VERSION ""

NS_ :

BS_:

BU_: IDM FR Tester

BO_ 1136 ADAS_AD1: 16 IDM
 SG_ Sync_SyncTime : 39|32@0+ (1,0) [0|4294967295] "" Vector__XXX
 SG_ Sync_OVS : 25|2@0+ (1,0) [0|3] "" Vector__XXX
 SG_ Sync_SGW : 26|1@0+ (1,0) [0|1] "" Vector__XXX
 SG_ Sync_Resd : 31|5@0+ (1,0) [0|31] "" Vector__XXX
 SG_ Sync_Counter : 19|4@0+ (1,0) [0|15] "" Vector__XXX
 SG_ Sync_TimeDomain : 23|4@0+ (1,0) [0|15] "" Vector__XXX
 SG_ Sync_CRC : 15|8@0+ (1,0) [0|255] "" Vector__XXX
 SG_ Sync_Type : 7|8@0+ (1,0) [0|255] "" Vector__XXX

BO_ 302 IBC_FD1: 64 IDM
 SG_ RollingCounter_IBC_FD1_1 : 59|4@0+ (1,0) [0|15] "NoUnit" Vector__XXX
 SG_ PushrodStauts : 51|2@0+ (1,0) [0|3] "NoUnit" Vector__XXX
 SG_ InpRodStk : 47|10@0+ (0.05,-5) [-5|46.15] "mm" Vector__XXX
 SG_ InpRodStkSts : 32|1@0+ (1,0) [0|1] "NoUnit" Vector__XXX
 SG_ Checksum_IBC_FD1_1 : 7|8@0+ (1,0) [0|255] "NoUnit" Vector__XXX

BO_ 311 ESP_FD2: 64 IDM
 SG_ RollingCounter_ABS3 : 379|4@0+ (1,0) [0|15] "NoUnit" Vector__XXX
 SG_ ABSActv : 347|1@0+ (1,0) [0|1] "NoUnit" Vector__XXX
 SG_ VehSpd : 332|13@0+ (0.05625,0) [0|299.98125] "kph" Vector__XXX
 SG_ ABSFailSts : 335|1@0+ (1,0) [0|1] "NoUnit" Vector__XXX
 SG_ Checksum_ABS3 : 327|8@0+ (1,0) [0|255] "NoUnit" Vector__XXX
 SG_ RollingCounter_ESP1 : 187|4@0+ (1,0) [0|15] "NoUnit" Vector__XXX
 SG_ VDCActv : 148|1@0+ (1,0) [0|1] "NoUnit" Vector__XXX
 SG_ MSRActv : 149|1@0+ (1,0) [0|1] "NoUnit" Vector__XXX
 SG_ PTCActv : 150|1@0+ (1,0) [0|1] "NoUnit" Vector__XXX
 SG_ BTCActv : 151|1@0+ (1,0) [0|1] "NoUnit" Vector__XXX
 SG_ ESPFuncOffSts : 140|1@0+ (1,0) [0|1] "NoUnit" Vector__XXX
 SG_ ESPFailSts : 143|1@0+ (1,0) [0|1] "NoUnit" Vector__XXX
 SG_ Checksum_ESP1 : 135|8@0+ (1,0) [0|255] "NoUnit" Vector__XXX
 SG_ RollingCounter_ESP2 : 123|4@0+ (1,0) [0|15] "NoUnit" Vector__XXX
 SG_ ESP_DiagActv : 73|1@0+ (1,0) [0|1] "NoUnit" Vector__XXX
 SG_ NoBrkForce : 76|1@0+ (1,0) [0|1] "NoUnit" Vector__XXX
 SG_ VehStandstill : 78|2@0+ (1,0) [0|3] "NoUnit" Vector__XXX
 SG_ Checksum_ESP2 : 71|8@0+ (1,0) [0|255] "NoUnit" Vector__XXX

BO_ 315 ESP_FD3: 64 IDM
 SG_ RollingCounter_ABS2 : 379|4@0+ (1,0) [0|15] "NoUnit" Vector__XXX
 SG_ RRWheelSpd : 348|13@0+ (0.05625,0) [0|299.98125] "kph" Vector__XXX
 SG_ RRWheelSpdVld : 349|1@0+ (1,0) [0|1] "NoUnit" Vector__XXX
 SG_ RRWheelDriveDirection : 351|2@0+ (1,0) [0|3] "NoUnit" Vector__XXX
 SG_ RLWheelSpd : 332|13@0+ (0.05625,0) [0|299.98125] "kph" Vector__XXX
 SG_ RLWheelSpdVld : 333|1@0+ (1,0) [0|1] "NoUnit" Vector__XXX
 SG_ RLWheelDriveDirection : 335|2@0+ (1,0) [0|3] "NoUnit" Vector__XXX
 SG_ Checksum_ABS2 : 327|8@0+ (1,0) [0|255] "NoUnit" Vector__XXX
 SG_ RollingCounter_ABS1 : 59|4@0+ (1,0) [0|15] "NoUnit" Vector__XXX
 SG_ FRWheelSpd : 28|13@0+ (0.05625,0) [0|299.98125] "kph" Vector__XXX
 SG_ FRWheelSpdVld : 29|1@0+ (1,0) [0|1] "NoUnit" Vector__XXX
 SG_ FRWheelDriveDirection : 31|2@0+ (1,0) [0|3] "NoUnit" Vector__XXX
 SG_ FLWheelSpd : 12|13@0+ (0.05625,0) [0|299.98125] "kph" Vector__XXX
 SG_ FLWheelSpdVld : 13|1@0+ (1,0) [0|1] "NoUnit" Vector__XXX
 SG_ FLWheelDriveDirection : 15|2@0+ (1,0) [0|3] "NoUnit" Vector__XXX
 SG_ Checksum_ABS1 : 7|8@0+ (1,0) [0|255] "NoUnit" Vector__XXX

BO_ 411 F_PBOX1: 8 IDM
 SG_ HoodSts_F_PBox : 21|1@0+ (1,0) [0|1] "NoUnit" Vector__XXX

BO_ 412 R_PBOX1: 16 IDM
 SG_ RTurnLmpSts_R_PBox : 30|1@0+ (1,0) [0|1] "NoUnit" Vector__XXX
 SG_ LTurnLmpSts_R_PBox : 31|1@0+ (1,0) [0|1] "NoUnit" Vector__XXX

BO_ 545 DCT5: 8 IDM
 SG_ TGS_LEVER : 51|4@0+ (1,0) [0|15] "NoUnit" Vector__XXX

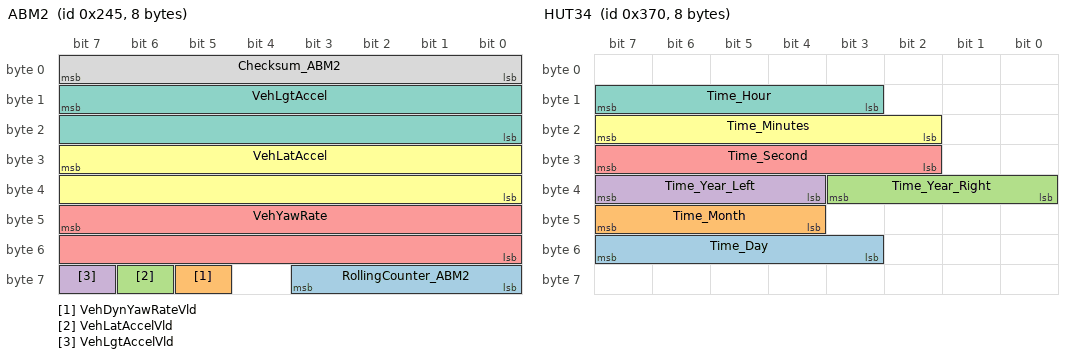
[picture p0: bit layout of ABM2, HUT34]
BO_ 581 ABM2: 8 IDM
 SG_ RollingCounter_ABM2 : 59|4@0+ (1,0) [0|15] "NoUnit" Vector__XXX
 SG_ VehDynYawRateVld : 61|1@0+ (1,0) [0|1] "NoUnit" Vector__XXX
 SG_ VehLatAccelVld : 62|1@0+ (1,0) [0|1] "NoUnit" Vector__XXX
 SG_ VehLgtAccelVld : 63|1@0+ (1,0) [0|1] "NoUnit" Vector__XXX
 SG_ VehYawRate : 47|16@0+ (0.00024,-2.093) [-2.093|2.093] "radPerSec" Vector__XXX
 SG_ VehLatAccel : 31|16@0+ (0.00098,-21.592) [-21.592|21.592] "MtrPerSecSq" Vector__XXX
 SG_ VehLgtAccel : 15|16@0+ (0.00098,-21.592) [-21.592|21.592] "MtrPerSecSq" Vector__XXX
 SG_ Checksum_ABM2 : 7|8@0+ (1,0) [0|255] "NoUnit" Vector__XXX

BO_ 639 IP2: 16 IDM
 SG_ IP_VehTotDistance : 15|24@0+ (0.1,0) [0|999999.9] "km" Vector__XXX

BO_ 671 BCM8: 8 IDM
 SG_ WiprReq_F_PBox : 51|3@0+ (1,0) [0|7] "NoUnit" Vector__XXX

BO_ 719 IFC_FD3: 64 IDM
 SG_ TSRSpdLim : 87|6@0+ (1,0) [0|63] "NoUnit" Vector__XXX
 SG_ TSRConSpdLim : 15|6@0+ (1,0) [0|63] "NoUnit" Vector__XXX

BO_ 849 ABM1: 16 IDM
 SG_ RollingCounter_ABM1 : 59|4@0+ (1,0) [0|15] "NoUnit" Vector__XXX
 SG_ DrvSBR : 11|1@0+ (1,0) [0|1] "NoUnit" Vector__XXX
 SG_ Checksum_ABM1 : 7|8@0+ (1,0) [0|255] "NoUnit" Vector__XXX

BO_ 880 HUT34: 8 IDM
 SG_ Time_Day : 55|5@0+ (1,0) [0|31] "NoUnit" Vector__XXX
 SG_ Time_Month : 47|4@0+ (1,0) [0|15] "NoUnit" Vector__XXX
 SG_ Time_Year_Right : 35|4@0+ (1,0) [0|15] "NoUnit" Vector__XXX
 SG_ Time_Year_Left : 39|4@0+ (1,0) [0|15] "NoUnit" Vector__XXX
 SG_ Time_Second : 31|6@0+ (1,0) [0|63] "NoUnit" Vector__XXX
 SG_ Time_Minutes : 23|6@0+ (1,0) [0|63] "NoUnit" Vector__XXX
 SG_ Time_Hour : 15|5@0+ (1,0) [0|31] "NoUnit" Vector__XXX

BO_ 901 AC2: 8 IDM
 SG_ ACAmbTemp : 23|8@0+ (0.5,-40) [-40|86.5] "DegC" Vector__XXX

BO_ 1001 T_BOX_FD3: 16 IDM
 SG_ T_BOX_SysErrSts : 7|5@0+ (1,0) [0|31] "NoUnit" Vector__XXX

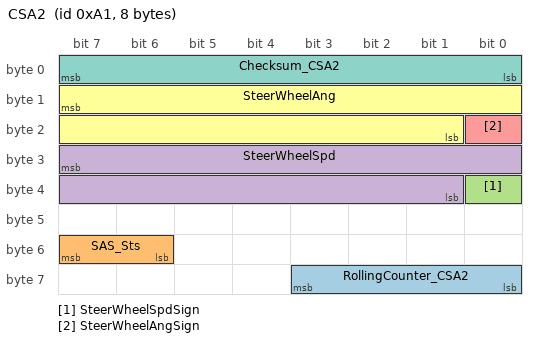
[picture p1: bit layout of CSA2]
BO_ 161 CSA2: 8 IDM
 SG_ RollingCounter_CSA2 : 59|4@0+ (1,0) [0|15] "NoUnit" Vector__XXX
 SG_ SAS_Sts : 55|2@0+ (1,0) [0|3] "NoUnit" Vector__XXX
 SG_ SteerWheelSpdSign : 32|1@0+ (1,0) [0|1] "NoUnit" Vector__XXX
 SG_ SteerWheelSpd : 31|15@0+ (0.1,0) [0|1016] "DegPerSec" Vector__XXX
 SG_ SteerWheelAngSign : 16|1@0+ (1,0) [0|1] "NoUnit" Vector__XXX
 SG_ SteerWheelAng : 15|15@0+ (0.1,0) [0|780] "Deg" Vector__XXX
 SG_ Checksum_CSA2 : 7|8@0+ (1,0) [0|255] "NoUnit" Vector__XXX

BO_ 1073 MRRAD2: 64 FR
 SG_ RollingCounter16 : 507|4@0+ (1,0) [0|15] ""  IDM
 SG_ MRR_ObjMeasured_3 : 497|2@0+ (1,0) [0|3] ""  IDM
 SG_ MRR_ObjMeasured_4 : 499|2@0+ (1,0) [0|3] ""  IDM
 SG_ MRR_ObjHeading_4 : 495|12@0+ (0.002,-3.14) [-3.14|3.14] "rad"  IDM
 SG_ MRR_ObjAge_4 : 487|8@0+ (1,0) [0|255] ""  IDM
 SG_ MRR_ObjRCS_4 : 465|10@0+ (0.125,-50) [-50|70] "dBm2"  IDM
 SG_ BlockCounter2 : 469|4@0+ (1,0) [0|15] ""  IDM
 SG_ VFC_ObjHeight_4 : 463|10@0+ (0.01,0) [0|6] "m"  IDM
 SG_ Checksum16 : 455|8@0+ (1,0) [0|255] ""  IDM
 SG_ RollingCounter15 : 443|4@0+ (1,0) [0|15] ""  IDM
 SG_ VFC_ObjMotionDirection_4 : 432|3@0+ (1,0) [0|7] ""  IDM
 SG_ VFC_ObjLength_4 : 426|10@0+ (0.05,0) [0|20] "m"  IDM
 SG_ VFC_ObjWidth_4 : 420|10@0+ (0.01,0) [0|5] "m"  IDM
 SG_ MRR_ObjMotionType_4 : 423|3@0+ (1,0) [0|7] ""  IDM
 SG_ MRR_ObjRAccelYStd_4 : 413|6@0+ (0.0625,0) [0|3.9375] "mps2"  IDM
 SG_ MRR_ObjRAccelXStd_4 : 403|6@0+ (0.0625,0) [0|3.9375] "mps2"  IDM
 SG_ MRR_ObjRelVelYStd_4 : 393|6@0+ (0.0625,0) [0|3.9375] "mps"  IDM
 SG_ MRR_ObjRelVelXStd_4 : 399|6@0+ (0.0625,0) [0|3.9375] "mps"  IDM
 SG_ Checksum15 : 391|8@0+ (1,0) [0|255] ""  IDM
 SG_ RollingCounter14 : 379|4@0+ (1,0) [0|15] ""  IDM
 SG_ MRR_ObjType_4 : 383|4@0+ (1,0) [0|15] ""  IDM
 SG_ MRR_ObjDistYStd_4 : 373|6@0+ (0.1,0) [0|6] "m"  IDM
 SG_ MRR_ObjDistXStd_4 : 363|6@0+ (0.1,0) [0|6] "m"  IDM
 SG_ MRR_ObjRelAccelY_4 : 357|10@0+ (0.03125,-16) [-16|15.96875] "mps2"  IDM
 SG_ MRR_ObjRelVelY_4 : 338|13@0+ (0.0312,-128) [-128|126.9976] "mps"  IDM
 SG_ MRR_ObjRelVelX_4 : 335|13@0+ (0.0312,-128) [-128|126.9976] "mps"  IDM
 SG_ Checksum14 : 327|8@0+ (1,0) [0|255] ""  IDM
 SG_ RollingCounter13 : 315|4@0+ (1,0) [0|15] ""  IDM
 SG_ MRR_ObjRelAccelX_4 : 310|10@0+ (0.03125,-16) [-16|15.96875] "mps2"  IDM
 SG_ MRR_ObjDistY_4 : 289|11@0+ (0.125,-128) [-128|127.875] "m"  IDM
 SG_ MRR_ObjDistX_4 : 285|12@0+ (0.0625,0) [0|254.9375] "m"  IDM
 SG_ MRR_ObjObstacleProb_4 : 274|5@0+ (0.03125,0) [0|0.96875] ""  IDM
 SG_ MRR_ObjExistProb_4 : 279|5@0+ (0.03125,0) [0|0.96875] ""  IDM
 SG_ MRR_ObjID_4 : 271|8@0+ (1,0) [0|255] ""  IDM
 SG_ Checksum13 : 263|8@0+ (1,0) [0|255] ""  IDM
 SG_ RollingCounter12 : 251|4@0+ (1,0) [0|15] ""  IDM
 SG_ MRR_ObjRefPoint_3 : 243|3@0+ (1,0) [0|7] "NoUnit"  IDM
 SG_ MRR_ObjRefPoint_4 : 247|3@0+ (1,0) [0|7] "NoUnit"  IDM
 SG_ MRR_ObjAge_3 : 239|8@0+ (1,0) [0|255] ""  IDM
 SG_ MRR_ObjRCS_3 : 217|10@0+ (0.125,-50) [-50|70] "dBm2"  IDM
 SG_ MRR_ObjHeading_3 : 213|12@0+ (0.002,-3.14) [-3.14|3.14] "rad"  IDM
 SG_ VFC_ObjHeight_3 : 207|10@0+ (0.01,0) [0|6] "m"  IDM
 SG_ Checksum12 : 199|8@0+ (1,0) [0|255] ""  IDM
 SG_ RollingCounter11 : 187|4@0+ (1,0) [0|15] ""  IDM
 SG_ VFC_ObjMotionDirection_3 : 176|3@0+ (1,0) [0|7] ""  IDM
 SG_ VFC_ObjLength_3 : 170|10@0+ (0.05,0) [0|20] "m"  IDM
 SG_ VFC_ObjWidth_3 : 164|10@0+ (0.01,0) [0|5] "m"  IDM
 SG_ MRR_ObjMotionType_3 : 167|3@0+ (1,0) [0|7] ""  IDM
 SG_ MRR_ObjRAccelYStd_3 : 157|6@0+ (0.0625,0) [0|3.9375] "mps2"  IDM
 SG_ MRR_ObjRAccelXStd_3 : 147|6@0+ (0.0625,0) [0|3.9375] "mps2"  IDM
 SG_ MRR_ObjRelVelYStd_3 : 137|6@0+ (0.0625,0) [0|3.9375] "mps"  IDM
 SG_ MRR_ObjRelVelXStd_3 : 143|6@0+ (0.0625,0) [0|3.9375] "mps"  IDM
 SG_ Checksum11 : 135|8@0+ (1,0) [0|255] ""  IDM
 SG_ RollingCounter10 : 123|4@0+ (1,0) [0|15] ""  IDM
 SG_ MRR_ObjType_3 : 127|4@0+ (1,0) [0|15] ""  IDM
 SG_ MRR_ObjDistYStd_3 : 117|6@0+ (0.1,0) [0|6] "m"  IDM
 SG_ MRR_ObjDistXStd_3 : 107|6@0+ (0.1,0) [0|6] "m"  IDM
 SG_ MRR_ObjRelAccelY_3 : 101|10@0+ (0.03125,-16) [-16|15.96875] "mps2"  IDM
 SG_ MRR_ObjRelVelY_3 : 82|13@0+ (0.0312,-128) [-128|126.9976] "mps"  IDM
 SG_ MRR_ObjRelVelX_3 : 79|13@0+ (0.0312,-128) [-128|126.9976] "mps"  IDM
 SG_ Checksum10 : 71|8@0+ (1,0) [0|255] ""  IDM
 SG_ RollingCounter9 : 59|4@0+ (1,0) [0|15] ""  IDM
 SG_ MRR_ObjRelAccelX_3 : 54|10@0+ (0.03125,-16) [-16|15.96875] "mps2"  IDM
 SG_ MRR_ObjDistY_3 : 33|11@0+ (0.125,-128) [-128|127.875] "m"  IDM
 SG_ MRR_ObjDistX_3 : 29|12@0+ (0.0625,0) [0|254.9375] "m"  IDM
 SG_ MRR_ObjObstacleProb_3 : 18|5@0+ (0.03125,0) [0|0.96875] ""  IDM
 SG_ MRR_ObjExistProb_3 : 23|5@0+ (0.03125,0) [0|0.96875] ""  IDM
 SG_ MRR_ObjID_3 : 15|8@0+ (1,0) [0|255] ""  IDM
 SG_ Checksum9 : 7|8@0+ (1,0) [0|255] ""  IDM

BO_ 1074 MRRAD3: 64 FR
 SG_ RollingCounter24 : 507|4@0+ (1,0) [0|15] ""  IDM
 SG_ MRR_ObjMeasured_5 : 497|2@0+ (1,0) [0|3] ""  IDM
 SG_ MRR_ObjMeasured_6 : 499|2@0+ (1,0) [0|3] ""  IDM
 SG_ MRR_ObjHeading_6 : 495|12@0+ (0.002,-3.14) [-3.14|3.14] "rad"  IDM
 SG_ MRR_ObjAge_6 : 487|8@0+ (1,0) [0|255] ""  IDM
 SG_ MRR_ObjRCS_6 : 465|10@0+ (0.125,-50) [-50|70] "dBm2"  IDM
 SG_ BlockCounter3 : 469|4@0+ (1,0) [0|15] ""  IDM
 SG_ VFC_ObjHeight_6 : 463|10@0+ (0.01,0) [0|6] "m"  IDM
 SG_ Checksum24 : 455|8@0+ (1,0) [0|255] ""  IDM
 SG_ RollingCounter23 : 443|4@0+ (1,0) [0|15] ""  IDM
 SG_ VFC_ObjMotionDirection_6 : 432|3@0+ (1,0) [0|7] ""  IDM
 SG_ VFC_ObjLength_6 : 426|10@0+ (0.05,0) [0|20] "m"  IDM
 SG_ VFC_ObjWidth_6 : 420|10@0+ (0.01,0) [0|5] "m"  IDM
 SG_ MRR_ObjMotionType_6 : 423|3@0+ (1,0) [0|7] ""  IDM
 SG_ MRR_ObjRAccelYStd_6 : 413|6@0+ (0.0625,0) [0|3.9375] "mps2"  IDM
 SG_ MRR_ObjRAccelXStd_6 : 403|6@0+ (0.0625,0) [0|3.9375] "mps2"  IDM
 SG_ MRR_ObjRelVelYStd_6 : 393|6@0+ (0.0625,0) [0|3.9375] "mps"  IDM
 SG_ MRR_ObjRelVelXStd_6 : 399|6@0+ (0.0625,0) [0|3.9375] "mps"  IDM
 SG_ Checksum23 : 391|8@0+ (1,0) [0|255] ""  IDM
 SG_ RollingCounter22 : 379|4@0+ (1,0) [0|15] ""  IDM
 SG_ MRR_ObjType_6 : 383|4@0+ (1,0) [0|15] ""  IDM
 SG_ MRR_ObjDistYStd_6 : 373|6@0+ (0.1,0) [0|6] "m"  IDM
 SG_ MRR_ObjDistXStd_6 : 363|6@0+ (0.1,0) [0|6] "m"  IDM
 SG_ MRR_ObjRelAccelY_6 : 357|10@0+ (0.03125,-16) [-16|15.96875] "mps2"  IDM
 SG_ MRR_ObjRelVelY_6 : 338|13@0+ (0.0312,-128) [-128|126.9976] "mps"  IDM
 SG_ MRR_ObjRelVelX_6 : 335|13@0+ (0.0312,-128) [-128|126.9976] "mps"  IDM
 SG_ Checksum22 : 327|8@0+ (1,0) [0|255] ""  IDM
 SG_ RollingCounter21 : 315|4@0+ (1,0) [0|15] ""  IDM
 SG_ MRR_ObjRelAccelX_6 : 310|10@0+ (0.03125,-16) [-16|15.96875] "mps2"  IDM
 SG_ MRR_ObjDistY_6 : 289|11@0+ (0.125,-128) [-128|127.875] "m"  IDM
 SG_ MRR_ObjDistX_6 : 285|12@0+ (0.0625,0) [0|254.9375] "m"  IDM
 SG_ MRR_ObjObstacleProb_6 : 274|5@0+ (0.03125,0) [0|0.96875] ""  IDM
 SG_ MRR_ObjExistProb_6 : 279|5@0+ (0.03125,0) [0|0.96875] ""  IDM
 SG_ MRR_ObjID_6 : 271|8@0+ (1,0) [0|255] ""  IDM
 SG_ Checksum21 : 263|8@0+ (1,0) [0|255] ""  IDM
 SG_ RollingCounter20 : 251|4@0+ (1,0) [0|15] ""  IDM
 SG_ MRR_ObjRefPoint_5 : 243|3@0+ (1,0) [0|7] "NoUnit"  IDM
 SG_ MRR_ObjRefPoint_6 : 247|3@0+ (1,0) [0|7] "NoUnit"  IDM
 SG_ MRR_ObjAge_5 : 239|8@0+ (1,0) [0|255] ""  IDM
 SG_ MRR_ObjRCS_5 : 217|10@0+ (0.125,-50) [-50|70] "dBm2"  IDM
 SG_ MRR_ObjHeading_5 : 213|12@0+ (0.002,-3.14) [-3.14|3.14] "rad"  IDM
 SG_ VFC_ObjHeight_5 : 207|10@0+ (0.01,0) [0|6] "m"  IDM
 SG_ Checksum20 : 199|8@0+ (1,0) [0|255] ""  IDM
 SG_ RollingCounter19 : 187|4@0+ (1,0) [0|15] ""  IDM
 SG_ VFC_ObjMotionDirection_5 : 176|3@0+ (1,0) [0|7] ""  IDM
 SG_ VFC_ObjLength_5 : 170|10@0+ (0.05,0) [0|20] "m"  IDM
 SG_ VFC_ObjWidth_5 : 164|10@0+ (0.01,0) [0|5] "m"  IDM
 SG_ MRR_ObjMotionType_5 : 167|3@0+ (1,0) [0|7] ""  IDM
 SG_ MRR_ObjRAccelYStd_5 : 157|6@0+ (0.0625,0) [0|3.9375] "mps2"  IDM
 SG_ MRR_ObjRAccelXStd_5 : 147|6@0+ (0.0625,0) [0|3.9375] "mps2"  IDM
 SG_ MRR_ObjRelVelYStd_5 : 137|6@0+ (0.0625,0) [0|3.9375] "mps"  IDM
 SG_ MRR_ObjRelVelXStd_5 : 143|6@0+ (0.0625,0) [0|3.9375] "mps"  IDM
 SG_ Checksum19 : 135|8@0+ (1,0) [0|255] ""  IDM
 SG_ RollingCounter18 : 123|4@0+ (1,0) [0|15] ""  IDM
 SG_ MRR_ObjType_5 : 127|4@0+ (1,0) [0|15] ""  IDM
 SG_ MRR_ObjDistYStd_5 : 117|6@0+ (0.1,0) [0|6] "m"  IDM
 SG_ MRR_ObjDistXStd_5 : 107|6@0+ (0.1,0) [0|6] "m"  IDM
 SG_ MRR_ObjRelAccelY_5 : 101|10@0+ (0.03125,-16) [-16|15.96875] "mps2"  IDM
 SG_ MRR_ObjRelVelY_5 : 82|13@0+ (0.0312,-128) [-128|126.9976] "mps"  IDM
 SG_ MRR_ObjRelVelX_5 : 79|13@0+ (0.0312,-128) [-128|126.9976] "mps"  IDM
 SG_ Checksum18 : 71|8@0+ (1,0) [0|255] ""  IDM
 SG_ RollingCounter17 : 59|4@0+ (1,0) [0|15] ""  IDM
 SG_ MRR_ObjRelAccelX_5 : 54|10@0+ (0.03125,-16) [-16|15.96875] "mps2"  IDM
 SG_ MRR_ObjDistY_5 : 33|11@0+ (0.125,-128) [-128|127.875] "m"  IDM
 SG_ MRR_ObjDistX_5 : 29|12@0+ (0.0625,0) [0|254.9375] "m"  IDM
 SG_ MRR_ObjObstacleProb_5 : 18|5@0+ (0.03125,0) [0|0.96875] ""  IDM
 SG_ MRR_ObjExistProb_5 : 23|5@0+ (0.03125,0) [0|0.96875] ""  IDM
 SG_ MRR_ObjID_5 : 15|8@0+ (1,0) [0|255] ""  IDM
 SG_ Checksum17 : 7|8@0+ (1,0) [0|255] ""  IDM

BO_ 1075 MRRAD4: 64 FR
 SG_ RollingCounter32 : 507|4@0+ (1,0) [0|15] ""  IDM
 SG_ MRR_ObjMeasured_7 : 497|2@0+ (1,0) [0|3] ""  IDM
 SG_ MRR_ObjMeasured_8 : 499|2@0+ (1,0) [0|3] ""  IDM
 SG_ MRR_ObjHeading_8 : 495|12@0+ (0.002,-3.14) [-3.14|3.14] "rad"  IDM
 SG_ MRR_ObjAge_8 : 487|8@0+ (1,0) [0|255] ""  IDM
 SG_ MRR_ObjRCS_8 : 465|10@0+ (0.125,-50) [-50|70] "dBm2"  IDM
 SG_ BlockCounter4 : 469|4@0+ (1,0) [0|15] ""  IDM
 SG_ VFC_ObjHeight_8 : 463|10@0+ (0.01,0) [0|6] "m"  IDM
 SG_ Checksum32 : 455|8@0+ (1,0) [0|255] ""  IDM
 SG_ RollingCounter31 : 443|4@0+ (1,0) [0|15] ""  IDM
 SG_ VFC_ObjMotionDirection_8 : 432|3@0+ (1,0) [0|7] ""  IDM
 SG_ VFC_ObjLength_8 : 426|10@0+ (0.05,0) [0|20] "m"  IDM
 SG_ VFC_ObjWidth_8 : 420|10@0+ (0.01,0) [0|5] "m"  IDM
 SG_ MRR_ObjMotionType_8 : 423|3@0+ (1,0) [0|7] ""  IDM
 SG_ MRR_ObjRAccelYStd_8 : 413|6@0+ (0.0625,0) [0|3.9375] "mps2"  IDM
 SG_ MRR_ObjRAccelXStd_8 : 403|6@0+ (0.0625,0) [0|3.9375] "mps2"  IDM
 SG_ MRR_ObjRelVelYStd_8 : 393|6@0+ (0.0625,0) [0|3.9375] "mps"  IDM
 SG_ MRR_ObjRelVelXStd_8 : 399|6@0+ (0.0625,0) [0|3.9375] "mps"  IDM
 SG_ Checksum31 : 391|8@0+ (1,0) [0|255] ""  IDM
 SG_ RollingCounter30 : 379|4@0+ (1,0) [0|15] ""  IDM
 SG_ MRR_ObjType_8 : 383|4@0+ (1,0) [0|15] ""  IDM
 SG_ MRR_ObjDistYStd_8 : 373|6@0+ (0.1,0) [0|6] "m"  IDM
 SG_ MRR_ObjDistXStd_8 : 363|6@0+ (0.1,0) [0|6] "m"  IDM
 SG_ MRR_ObjRelAccelY_8 : 357|10@0+ (0.03125,-16) [-16|15.96875] "mps2"  IDM
 SG_ MRR_ObjRelVelY_8 : 338|13@0+ (0.0312,-128) [-128|126.9976] "mps"  IDM
 SG_ MRR_ObjRelVelX_8 : 335|13@0+ (0.0312,-128) [-128|126.9976] "mps"  IDM
 SG_ Checksum30 : 327|8@0+ (1,0) [0|255] ""  IDM
 SG_ RollingCounter29 : 315|4@0+ (1,0) [0|15] ""  IDM
 SG_ MRR_ObjRelAccelX_8 : 310|10@0+ (0.03125,-16) [-16|15.96875] "mps2"  IDM
 SG_ MRR_ObjDistY_8 : 289|11@0+ (0.125,-128) [-128|127.875] "m"  IDM
 SG_ MRR_ObjDistX_8 : 285|12@0+ (0.0625,0) [0|254.9375] "m"  IDM
 SG_ MRR_ObjObstacleProb_8 : 274|5@0+ (0.03125,0) [0|0.96875] ""  IDM
 SG_ MRR_ObjExistProb_8 : 279|5@0+ (0.03125,0) [0|0.96875] ""  IDM
 SG_ MRR_ObjID_8 : 271|8@0+ (1,0) [0|255] ""  IDM
 SG_ Checksum29 : 263|8@0+ (1,0) [0|255] ""  IDM
 SG_ RollingCounter28 : 251|4@0+ (1,0) [0|15] ""  IDM
 SG_ MRR_ObjRefPoint_7 : 243|3@0+ (1,0) [0|7] "NoUnit"  IDM
 SG_ MRR_ObjRefPoint_8 : 247|3@0+ (1,0) [0|7] "NoUnit"  IDM
 SG_ MRR_ObjAge_7 : 239|8@0+ (1,0) [0|255] ""  IDM
 SG_ MRR_ObjRCS_7 : 217|10@0+ (0.125,-50) [-50|70] "dBm2"  IDM
 SG_ MRR_ObjHeading_7 : 213|12@0+ (0.002,-3.14) [-3.14|3.14] "rad"  IDM
 SG_ VFC_ObjHeight_7 : 207|10@0+ (0.01,0) [0|6] "m"  IDM
 SG_ Checksum28 : 199|8@0+ (1,0) [0|255] ""  IDM
 SG_ RollingCounter27 : 187|4@0+ (1,0) [0|15] ""  IDM
 SG_ VFC_ObjMotionDirection_7 : 176|3@0+ (1,0) [0|7] ""  IDM
 SG_ VFC_ObjLength_7 : 170|10@0+ (0.05,0) [0|20] "m"  IDM
 SG_ VFC_ObjWidth_7 : 164|10@0+ (0.01,0) [0|5] "m"  IDM
 SG_ MRR_ObjMotionType_7 : 167|3@0+ (1,0) [0|7] ""  IDM
 SG_ MRR_ObjRAccelYStd_7 : 157|6@0+ (0.0625,0) [0|3.9375] "mps2"  IDM
 SG_ MRR_ObjRAccelXStd_7 : 147|6@0+ (0.0625,0) [0|3.9375] "mps2"  IDM
 SG_ MRR_ObjRelVelYStd_7 : 137|6@0+ (0.0625,0) [0|3.9375] "mps"  IDM
 SG_ MRR_ObjRelVelXStd_7 : 143|6@0+ (0.0625,0) [0|3.9375] "mps"  IDM
 SG_ Checksum27 : 135|8@0+ (1,0) [0|255] ""  IDM
 SG_ RollingCounter26 : 123|4@0+ (1,0) [0|15] ""  IDM
 SG_ MRR_ObjType_7 : 127|4@0+ (1,0) [0|15] ""  IDM
 SG_ MRR_ObjDistYStd_7 : 117|6@0+ (0.1,0) [0|6] "m"  IDM
 SG_ MRR_ObjDistXStd_7 : 107|6@0+ (0.1,0) [0|6] "m"  IDM
 SG_ MRR_ObjRelAccelY_7 : 101|10@0+ (0.03125,-16) [-16|15.96875] "mps2"  IDM
 SG_ MRR_ObjRelVelY_7 : 82|13@0+ (0.0312,-128) [-128|126.9976] "mps"  IDM
 SG_ MRR_ObjRelVelX_7 : 79|13@0+ (0.0312,-128) [-128|126.9976] "mps"  IDM
 SG_ Checksum26 : 71|8@0+ (1,0) [0|255] ""  IDM
 SG_ RollingCounter25 : 59|4@0+ (1,0) [0|15] ""  IDM
 SG_ MRR_ObjRelAccelX_7 : 54|10@0+ (0.03125,-16) [-16|15.96875] "mps2"  IDM
 SG_ MRR_ObjDistY_7 : 33|11@0+ (0.125,-128) [-128|127.875] "m"  IDM
 SG_ MRR_ObjDistX_7 : 29|12@0+ (0.0625,0) [0|254.9375] "m"  IDM
 SG_ MRR_ObjObstacleProb_7 : 18|5@0+ (0.03125,0) [0|0.96875] ""  IDM
 SG_ MRR_ObjExistProb_7 : 23|5@0+ (0.03125,0) [0|0.96875] ""  IDM
 SG_ MRR_ObjID_7 : 15|8@0+ (1,0) [0|255] ""  IDM
 SG_ Checksum25 : 7|8@0+ (1,0) [0|255] ""  IDM

BO_ 1076 MRRAD5: 64 FR
 SG_ RollingCounter40 : 507|4@0+ (1,0) [0|15] ""  IDM
 SG_ MRR_ObjMeasured_9 : 497|2@0+ (1,0) [0|3] ""  IDM
 SG_ MRR_ObjMeasured_10 : 499|2@0+ (1,0) [0|3] ""  IDM
 SG_ MRR_ObjHeading_10 : 495|12@0+ (0.002,-3.14) [-3.14|3.14] "rad"  IDM
 SG_ MRR_ObjAge_10 : 487|8@0+ (1,0) [0|255] ""  IDM
 SG_ MRR_ObjRCS_10 : 465|10@0+ (0.125,-50) [-50|70] "dBm2"  IDM
 SG_ BlockCounter5 : 469|4@0+ (1,0) [0|15] ""  IDM
 SG_ VFC_ObjHeight_10 : 463|10@0+ (0.01,0) [0|6] "m"  IDM
 SG_ Checksum40 : 455|8@0+ (1,0) [0|255] ""  IDM
 SG_ RollingCounter39 : 443|4@0+ (1,0) [0|15] ""  IDM
 SG_ VFC_ObjMotionDirection_10 : 432|3@0+ (1,0) [0|7] ""  IDM
 SG_ VFC_ObjLength_10 : 426|10@0+ (0.05,0) [0|20] "m"  IDM
 SG_ VFC_ObjWidth_10 : 420|10@0+ (0.01,0) [0|5] "m"  IDM
 SG_ MRR_ObjMotionType_10 : 423|3@0+ (1,0) [0|7] ""  IDM
 SG_ MRR_ObjRAccelYStd_10 : 413|6@0+ (0.0625,0) [0|3.9375] "mps2"  IDM
 SG_ MRR_ObjRAccelXStd_10 : 403|6@0+ (0.0625,0) [0|3.9375] "mps2"  IDM
 SG_ MRR_ObjRelVelYStd_10 : 393|6@0+ (0.0625,0) [0|3.9375] "mps"  IDM
 SG_ MRR_ObjRelVelXStd_10 : 399|6@0+ (0.0625,0) [0|3.9375] "mps"  IDM
 SG_ Checksum39 : 391|8@0+ (1,0) [0|255] ""  IDM
 SG_ RollingCounter38 : 379|4@0+ (1,0) [0|15] ""  IDM
 SG_ MRR_ObjType_10 : 383|4@0+ (1,0) [0|15] ""  IDM
 SG_ MRR_ObjDistYStd_10 : 373|6@0+ (0.1,0) [0|6] "m"  IDM
 SG_ MRR_ObjDistXStd_10 : 363|6@0+ (0.1,0) [0|6] "m"  IDM
 SG_ MRR_ObjRelAccelY_10 : 357|10@0+ (0.03125,-16) [-16|15.96875] "mps2"  IDM
 SG_ MRR_ObjRelVelY_10 : 338|13@0+ (0.0312,-128) [-128|126.9976] "mps"  IDM
 SG_ MRR_ObjRelVelX_10 : 335|13@0+ (0.0312,-128) [-128|126.9976] "mps"  IDM
 SG_ Checksum38 : 327|8@0+ (1,0) [0|255] ""  IDM
 SG_ RollingCounter37 : 315|4@0+ (1,0) [0|15] ""  IDM
 SG_ MRR_ObjRelAccelX_10 : 310|10@0+ (0.03125,-16) [-16|15.96875] "mps2"  IDM
 SG_ MRR_ObjDistY_10 : 289|11@0+ (0.125,-128) [-128|127.875] "m"  IDM
 SG_ MRR_ObjDistX_10 : 285|12@0+ (0.0625,0) [0|254.9375] "m"  IDM
 SG_ MRR_ObjObstacleProb_10 : 274|5@0+ (0.03125,0) [0|0.96875] ""  IDM
 SG_ MRR_ObjExistProb_10 : 279|5@0+ (0.03125,0) [0|0.96875] ""  IDM
 SG_ MRR_ObjID_10 : 271|8@0+ (1,0) [0|255] ""  IDM
 SG_ Checksum37 : 263|8@0+ (1,0) [0|255] ""  IDM
 SG_ RollingCounter36 : 251|4@0+ (1,0) [0|15] ""  IDM
 SG_ MRR_ObjRefPoint_9 : 243|3@0+ (1,0) [0|7] "NoUnit"  IDM
 SG_ MRR_ObjRefPoint_10 : 247|3@0+ (1,0) [0|7] "NoUnit"  IDM
 SG_ MRR_ObjAge_9 : 239|8@0+ (1,0) [0|255] ""  IDM
 SG_ MRR_ObjRCS_9 : 217|10@0+ (0.125,-50) [-50|70] "dBm2"  IDM
 SG_ MRR_ObjHeading_9 : 213|12@0+ (0.002,-3.14) [-3.14|3.14] "rad"  IDM
 SG_ VFC_ObjHeight_9 : 207|10@0+ (0.01,0) [0|6] "m"  IDM
 SG_ Checksum36 : 199|8@0+ (1,0) [0|255] ""  IDM
 SG_ RollingCounter35 : 187|4@0+ (1,0) [0|15] ""  IDM
 SG_ VFC_ObjMotionDirection_9 : 176|3@0+ (1,0) [0|7] ""  IDM
 SG_ VFC_ObjLength_9 : 170|10@0+ (0.05,0) [0|20] "m"  IDM
 SG_ VFC_ObjWidth_9 : 164|10@0+ (0.01,0) [0|5] "m"  IDM
 SG_ MRR_ObjMotionType_9 : 167|3@0+ (1,0) [0|7] ""  IDM
 SG_ MRR_ObjRAccelYStd_9 : 157|6@0+ (0.0625,0) [0|3.9375] "mps2"  IDM
 SG_ MRR_ObjRAccelXStd_9 : 147|6@0+ (0.0625,0) [0|3.9375] "mps2"  IDM
 SG_ MRR_ObjRelVelYStd_9 : 137|6@0+ (0.0625,0) [0|3.9375] "mps"  IDM
 SG_ MRR_ObjRelVelXStd_9 : 143|6@0+ (0.0625,0) [0|3.9375] "mps"  IDM
 SG_ Checksum35 : 135|8@0+ (1,0) [0|255] ""  IDM
 SG_ RollingCounter34 : 123|4@0+ (1,0) [0|15] ""  IDM
 SG_ MRR_ObjType_9 : 127|4@0+ (1,0) [0|15] ""  IDM
 SG_ MRR_ObjDistYStd_9 : 117|6@0+ (0.1,0) [0|6] "m"  IDM
 SG_ MRR_ObjDistXStd_9 : 107|6@0+ (0.1,0) [0|6] "m"  IDM
 SG_ MRR_ObjRelAccelY_9 : 101|10@0+ (0.03125,-16) [-16|15.96875] "mps2"  IDM
 SG_ MRR_ObjRelVelY_9 : 82|13@0+ (0.0312,-128) [-128|126.9976] "mps"  IDM
 SG_ MRR_ObjRelVelX_9 : 79|13@0+ (0.0312,-128) [-128|126.9976] "mps"  IDM
 SG_ Checksum34 : 71|8@0+ (1,0) [0|255] ""  IDM
 SG_ RollingCounter33 : 59|4@0+ (1,0) [0|15] ""  IDM
 SG_ MRR_ObjRelAccelX_9 : 54|10@0+ (0.03125,-16) [-16|15.96875] "mps2"  IDM
 SG_ MRR_ObjDistY_9 : 33|11@0+ (0.125,-128) [-128|127.875] "m"  IDM
 SG_ MRR_ObjDistX_9 : 29|12@0+ (0.0625,0) [0|254.9375] "m"  IDM
 SG_ MRR_ObjObstacleProb_9 : 18|5@0+ (0.03125,0) [0|0.96875] ""  IDM
 SG_ MRR_ObjExistProb_9 : 23|5@0+ (0.03125,0) [0|0.96875] ""  IDM
 SG_ MRR_ObjID_9 : 15|8@0+ (1,0) [0|255] ""  IDM
 SG_ Checksum33 : 7|8@0+ (1,0) [0|255] ""  IDM

BO_ 1077 MRRAD6: 64 FR
 SG_ RollingCounter48 : 507|4@0+ (1,0) [0|15] ""  IDM
 SG_ MRR_ObjMeasured_11 : 497|2@0+ (1,0) [0|3] ""  IDM
 SG_ MRR_ObjMeasured_12 : 499|2@0+ (1,0) [0|3] ""  IDM
 SG_ MRR_ObjHeading_12 : 495|12@0+ (0.002,-3.14) [-3.14|3.14] "rad"  IDM
 SG_ MRR_ObjAge_12 : 487|8@0+ (1,0) [0|255] ""  IDM
 SG_ MRR_ObjRCS_12 : 465|10@0+ (0.125,-50) [-50|70] "dBm2"  IDM
 SG_ BlockCounter6 : 469|4@0+ (1,0) [0|15] ""  IDM
 SG_ VFC_ObjHeight_12 : 463|10@0+ (0.01,0) [0|6] "m"  IDM
 SG_ Checksum48 : 455|8@0+ (1,0) [0|255] ""  IDM
 SG_ RollingCounter47 : 443|4@0+ (1,0) [0|15] ""  IDM
 SG_ VFC_ObjMotionDirection_12 : 432|3@0+ (1,0) [0|7] ""  IDM
 SG_ VFC_ObjLength_12 : 426|10@0+ (0.05,0) [0|20] "m"  IDM
 SG_ VFC_ObjWidth_12 : 420|10@0+ (0.01,0) [0|5] "m"  IDM
 SG_ MRR_ObjMotionType_12 : 423|3@0+ (1,0) [0|7] ""  IDM
 SG_ MRR_ObjRAccelYStd_12 : 413|6@0+ (0.0625,0) [0|3.9375] "mps2"  IDM
 SG_ MRR_ObjRAccelXStd_12 : 403|6@0+ (0.0625,0) [0|3.9375] "mps2"  IDM
 SG_ MRR_ObjRelVelYStd_12 : 393|6@0+ (0.0625,0) [0|3.9375] "mps"  IDM
 SG_ MRR_ObjRelVelXStd_12 : 399|6@0+ (0.0625,0) [0|3.9375] "mps"  IDM
 SG_ Checksum47 : 391|8@0+ (1,0) [0|255] ""  IDM
 SG_ RollingCounter46 : 379|4@0+ (1,0) [0|15] ""  IDM
 SG_ MRR_ObjType_12 : 383|4@0+ (1,0) [0|15] ""  IDM
 SG_ MRR_ObjDistYStd_12 : 373|6@0+ (0.1,0) [0|6] "m"  IDM
 SG_ MRR_ObjDistXStd_12 : 363|6@0+ (0.1,0) [0|6] "m"  IDM
 SG_ MRR_ObjRelAccelY_12 : 357|10@0+ (0.03125,-16) [-16|15.96875] "mps2"  IDM
 SG_ MRR_ObjRelVelY_12 : 338|13@0+ (0.0312,-128) [-128|126.9976] "mps"  IDM
 SG_ MRR_ObjRelVelX_12 : 335|13@0+ (0.0312,-128) [-128|126.9976] "mps"  IDM
 SG_ Checksum46 : 327|8@0+ (1,0) [0|255] ""  IDM
 SG_ RollingCounter45 : 315|4@0+ (1,0) [0|15] ""  IDM
 SG_ MRR_ObjRelAccelX_12 : 310|10@0+ (0.03125,-16) [-16|15.96875] "mps2"  IDM
 SG_ MRR_ObjDistY_12 : 289|11@0+ (0.125,-128) [-128|127.875] "m"  IDM
 SG_ MRR_ObjDistX_12 : 285|12@0+ (0.0625,0) [0|254.9375] "m"  IDM
 SG_ MRR_ObjObstacleProb_12 : 274|5@0+ (0.03125,0) [0|0.96875] ""  IDM
 SG_ MRR_ObjExistProb_12 : 279|5@0+ (0.03125,0) [0|0.96875] ""  IDM
 SG_ MRR_ObjID_12 : 271|8@0+ (1,0) [0|255] ""  IDM
 SG_ Checksum45 : 263|8@0+ (1,0) [0|255] ""  IDM
 SG_ RollingCounter44 : 251|4@0+ (1,0) [0|15] ""  IDM
 SG_ MRR_ObjRefPoint_11 : 243|3@0+ (1,0) [0|7] "NoUnit"  IDM
 SG_ MRR_ObjRefPoint_12 : 247|3@0+ (1,0) [0|7] "NoUnit"  IDM
 SG_ MRR_ObjAge_11 : 239|8@0+ (1,0) [0|255] ""  IDM
 SG_ MRR_ObjRCS_11 : 217|10@0+ (0.125,-50) [-50|70] "dBm2"  IDM
 SG_ MRR_ObjHeading_11 : 213|12@0+ (0.002,-3.14) [-3.14|3.14] "rad"  IDM
 SG_ VFC_ObjHeight_11 : 207|10@0+ (0.01,0) [0|6] "m"  IDM
 SG_ Checksum44 : 199|8@0+ (1,0) [0|255] ""  IDM
 SG_ RollingCounter43 : 187|4@0+ (1,0) [0|15] ""  IDM
 SG_ VFC_ObjMotionDirection_11 : 176|3@0+ (1,0) [0|7] ""  IDM
 SG_ VFC_ObjLength_11 : 170|10@0+ (0.05,0) [0|20] "m"  IDM
 SG_ VFC_ObjWidth_11 : 164|10@0+ (0.01,0) [0|5] "m"  IDM
 SG_ MRR_ObjMotionType_11 : 167|3@0+ (1,0) [0|7] ""  IDM
 SG_ MRR_ObjRAccelYStd_11 : 157|6@0+ (0.0625,0) [0|3.9375] "mps2"  IDM
 SG_ MRR_ObjRAccelXStd_11 : 147|6@0+ (0.0625,0) [0|3.9375] "mps2"  IDM
 SG_ MRR_ObjRelVelYStd_11 : 137|6@0+ (0.0625,0) [0|3.9375] "mps"  IDM
 SG_ MRR_ObjRelVelXStd_11 : 143|6@0+ (0.0625,0) [0|3.9375] "mps"  IDM
 SG_ Checksum43 : 135|8@0+ (1,0) [0|255] ""  IDM
 SG_ RollingCounter42 : 123|4@0+ (1,0) [0|15] ""  IDM
 SG_ MRR_ObjType_11 : 127|4@0+ (1,0) [0|15] ""  IDM
 SG_ MRR_ObjDistYStd_11 : 117|6@0+ (0.1,0) [0|6] "m"  IDM
 SG_ MRR_ObjDistXStd_11 : 107|6@0+ (0.1,0) [0|6] "m"  IDM
 SG_ MRR_ObjRelAccelY_11 : 101|10@0+ (0.03125,-16) [-16|15.96875] "mps2"  IDM
 SG_ MRR_ObjRelVelY_11 : 82|13@0+ (0.0312,-128) [-128|126.9976] "mps"  IDM
 SG_ MRR_ObjRelVelX_11 : 79|13@0+ (0.0312,-128) [-128|126.9976] "mps"  IDM
 SG_ Checksum42 : 71|8@0+ (1,0) [0|255] ""  IDM
 SG_ RollingCounter41 : 59|4@0+ (1,0) [0|15] ""  IDM
 SG_ MRR_ObjRelAccelX_11 : 54|10@0+ (0.03125,-16) [-16|15.96875] "mps2"  IDM
 SG_ MRR_ObjDistY_11 : 33|11@0+ (0.125,-128) [-128|127.875] "m"  IDM
 SG_ MRR_ObjDistX_11 : 29|12@0+ (0.0625,0) [0|254.9375] "m"  IDM
 SG_ MRR_ObjObstacleProb_11 : 18|5@0+ (0.03125,0) [0|0.96875] ""  IDM
 SG_ MRR_ObjExistProb_11 : 23|5@0+ (0.03125,0) [0|0.96875] ""  IDM
 SG_ MRR_ObjID_11 : 15|8@0+ (1,0) [0|255] ""  IDM
 SG_ Checksum41 : 7|8@0+ (1,0) [0|255] ""  IDM

BO_ 1078 MRRAD7: 64 FR
 SG_ RollingCounter56 : 507|4@0+ (1,0) [0|15] ""  IDM
 SG_ MRR_ObjMeasured_13 : 497|2@0+ (1,0) [0|3] ""  IDM
 SG_ MRR_ObjMeasured_14 : 499|2@0+ (1,0) [0|3] ""  IDM
 SG_ MRR_ObjHeading_14 : 495|12@0+ (0.002,-3.14) [-3.14|3.14] "rad"  IDM
 SG_ MRR_ObjAge_14 : 487|8@0+ (1,0) [0|255] ""  IDM
 SG_ MRR_ObjRCS_14 : 465|10@0+ (0.125,-50) [-50|70] "dBm2"  IDM
 SG_ BlockCounter7 : 469|4@0+ (1,0) [0|15] ""  IDM
 SG_ VFC_ObjHeight_14 : 463|10@0+ (0.01,0) [0|6] "m"  IDM
 SG_ Checksum56 : 455|8@0+ (1,0) [0|255] ""  IDM
 SG_ RollingCounter55 : 443|4@0+ (1,0) [0|15] ""  IDM
 SG_ VFC_ObjMotionDirection_14 : 432|3@0+ (1,0) [0|7] ""  IDM
 SG_ VFC_ObjLength_14 : 426|10@0+ (0.05,0) [0|20] "m"  IDM
 SG_ VFC_ObjWidth_14 : 420|10@0+ (0.01,0) [0|5] "m"  IDM
 SG_ MRR_ObjMotionType_14 : 423|3@0+ (1,0) [0|7] ""  IDM
 SG_ MRR_ObjRAccelYStd_14 : 413|6@0+ (0.0625,0) [0|3.9375] "mps2"  IDM
 SG_ MRR_ObjRAccelXStd_14 : 403|6@0+ (0.0625,0) [0|3.9375] "mps2"  IDM
 SG_ MRR_ObjRelVelYStd_14 : 393|6@0+ (0.0625,0) [0|3.9375] "mps"  IDM
 SG_ MRR_ObjRelVelXStd_14 : 399|6@0+ (0.0625,0) [0|3.9375] "mps"  IDM
 SG_ Checksum55 : 391|8@0+ (1,0) [0|255] ""  IDM
 SG_ RollingCounter54 : 379|4@0+ (1,0) [0|15] ""  IDM
 SG_ MRR_ObjType_14 : 383|4@0+ (1,0) [0|15] ""  IDM
 SG_ MRR_ObjDistYStd_14 : 373|6@0+ (0.1,0) [0|6] "m"  IDM
 SG_ MRR_ObjDistXStd_14 : 363|6@0+ (0.1,0) [0|6] "m"  IDM
 SG_ MRR_ObjRelAccelY_14 : 357|10@0+ (0.03125,-16) [-16|15.96875] "mps2"  IDM
 SG_ MRR_ObjRelVelY_14 : 338|13@0+ (0.0312,-128) [-128|126.9976] "mps"  IDM
 SG_ MRR_ObjRelVelX_14 : 335|13@0+ (0.0312,-128) [-128|126.9976] "mps"  IDM
 SG_ Checksum54 : 327|8@0+ (1,0) [0|255] ""  IDM
 SG_ RollingCounter53 : 315|4@0+ (1,0) [0|15] ""  IDM
 SG_ MRR_ObjRelAccelX_14 : 310|10@0+ (0.03125,-16) [-16|15.96875] "mps2"  IDM
 SG_ MRR_ObjDistY_14 : 289|11@0+ (0.125,-128) [-128|127.875] "m"  IDM
 SG_ MRR_ObjDistX_14 : 285|12@0+ (0.0625,0) [0|254.9375] "m"  IDM
 SG_ MRR_ObjObstacleProb_14 : 274|5@0+ (0.03125,0) [0|0.96875] ""  IDM
 SG_ MRR_ObjExistProb_14 : 279|5@0+ (0.03125,0) [0|0.96875] ""  IDM
 SG_ MRR_ObjID_14 : 271|8@0+ (1,0) [0|255] ""  IDM
 SG_ Checksum53 : 263|8@0+ (1,0) [0|255] ""  IDM
 SG_ RollingCounter52 : 251|4@0+ (1,0) [0|15] ""  IDM
 SG_ MRR_ObjRefPoint_13 : 243|3@0+ (1,0) [0|7] "NoUnit"  IDM
 SG_ MRR_ObjRefPoint_14 : 247|3@0+ (1,0) [0|7] "NoUnit"  IDM
 SG_ MRR_ObjAge_13 : 239|8@0+ (1,0) [0|255] ""  IDM
 SG_ MRR_ObjRCS_13 : 217|10@0+ (0.125,-50) [-50|70] "dBm2"  IDM
 SG_ MRR_ObjHeading_13 : 213|12@0+ (0.002,-3.14) [-3.14|3.14] "rad"  IDM
 SG_ VFC_ObjHeight_13 : 207|10@0+ (0.01,0) [0|6] "m"  IDM
 SG_ Checksum52 : 199|8@0+ (1,0) [0|255] ""  IDM
 SG_ RollingCounter51 : 187|4@0+ (1,0) [0|15] ""  IDM
 SG_ VFC_ObjMotionDirection_13 : 176|3@0+ (1,0) [0|7] ""  IDM
 SG_ VFC_ObjLength_13 : 170|10@0+ (0.05,0) [0|20] "m"  IDM
 SG_ VFC_ObjWidth_13 : 164|10@0+ (0.01,0) [0|5] "m"  IDM
 SG_ MRR_ObjMotionType_13 : 167|3@0+ (1,0) [0|7] ""  IDM
 SG_ MRR_ObjRAccelYStd_13 : 157|6@0+ (0.0625,0) [0|3.9375] "mps2"  IDM
 SG_ MRR_ObjRAccelXStd_13 : 147|6@0+ (0.0625,0) [0|3.9375] "mps2"  IDM
 SG_ MRR_ObjRelVelYStd_13 : 137|6@0+ (0.0625,0) [0|3.9375] "mps"  IDM
 SG_ MRR_ObjRelVelXStd_13 : 143|6@0+ (0.0625,0) [0|3.9375] "mps"  IDM
 SG_ Checksum51 : 135|8@0+ (1,0) [0|255] ""  IDM
 SG_ RollingCounter50 : 123|4@0+ (1,0) [0|15] ""  IDM
 SG_ MRR_ObjType_13 : 127|4@0+ (1,0) [0|15] ""  IDM
 SG_ MRR_ObjDistYStd_13 : 117|6@0+ (0.1,0) [0|6] "m"  IDM
 SG_ MRR_ObjDistXStd_13 : 107|6@0+ (0.1,0) [0|6] "m"  IDM
 SG_ MRR_ObjRelAccelY_13 : 101|10@0+ (0.03125,-16) [-16|15.96875] "mps2"  IDM
 SG_ MRR_ObjRelVelY_13 : 82|13@0+ (0.0312,-128) [-128|126.9976] "mps"  IDM
 SG_ MRR_ObjRelVelX_13 : 79|13@0+ (0.0312,-128) [-128|126.9976] "mps"  IDM
 SG_ Checksum50 : 71|8@0+ (1,0) [0|255] ""  IDM
 SG_ RollingCounter49 : 59|4@0+ (1,0) [0|15] ""  IDM
 SG_ MRR_ObjRelAccelX_13 : 54|10@0+ (0.03125,-16) [-16|15.96875] "mps2"  IDM
 SG_ MRR_ObjDistY_13 : 33|11@0+ (0.125,-128) [-128|127.875] "m"  IDM
 SG_ MRR_ObjDistX_13 : 29|12@0+ (0.0625,0) [0|254.9375] "m"  IDM
 SG_ MRR_ObjObstacleProb_13 : 18|5@0+ (0.03125,0) [0|0.96875] ""  IDM
 SG_ MRR_ObjExistProb_13 : 23|5@0+ (0.03125,0) [0|0.96875] ""  IDM
 SG_ MRR_ObjID_13 : 15|8@0+ (1,0) [0|255] ""  IDM
 SG_ Checksum49 : 7|8@0+ (1,0) [0|255] ""  IDM

BO_ 1079 MRRAD8: 64 FR
 SG_ RollingCounter64 : 507|4@0+ (1,0) [0|15] ""  IDM
 SG_ MRR_ObjMeasured_15 : 497|2@0+ (1,0) [0|3] ""  IDM
 SG_ MRR_ObjMeasured_16 : 499|2@0+ (1,0) [0|3] ""  IDM
 SG_ MRR_ObjHeading_16 : 495|12@0+ (0.002,-3.14) [-3.14|3.14] "rad"  IDM
 SG_ MRR_ObjAge_16 : 487|8@0+ (1,0) [0|255] ""  IDM
 SG_ MRR_ObjRCS_16 : 465|10@0+ (0.125,-50) [-50|70] "dBm2"  IDM
 SG_ BlockCounter8 : 469|4@0+ (1,0) [0|15] ""  IDM
 SG_ VFC_ObjHeight_16 : 463|10@0+ (0.01,0) [0|6] "m"  IDM
 SG_ Checksum64 : 455|8@0+ (1,0) [0|255] ""  IDM
 SG_ RollingCounter63 : 443|4@0+ (1,0) [0|15] ""  IDM
 SG_ VFC_ObjMotionDirection_16 : 432|3@0+ (1,0) [0|7] ""  IDM
 SG_ VFC_ObjLength_16 : 426|10@0+ (0.05,0) [0|20] "m"  IDM
 SG_ VFC_ObjWidth_16 : 420|10@0+ (0.01,0) [0|5] "m"  IDM
 SG_ MRR_ObjMotionType_16 : 423|3@0+ (1,0) [0|7] ""  IDM
 SG_ MRR_ObjRAccelYStd_16 : 413|6@0+ (0.0625,0) [0|3.9375] "mps2"  IDM
 SG_ MRR_ObjRAccelXStd_16 : 403|6@0+ (0.0625,0) [0|3.9375] "mps2"  IDM
 SG_ MRR_ObjRelVelYStd_16 : 393|6@0+ (0.0625,0) [0|3.9375] "mps"  IDM
 SG_ MRR_ObjRelVelXStd_16 : 399|6@0+ (0.0625,0) [0|3.9375] "mps"  IDM
 SG_ Checksum63 : 391|8@0+ (1,0) [0|255] ""  IDM
 SG_ RollingCounter62 : 379|4@0+ (1,0) [0|15] ""  IDM
 SG_ MRR_ObjType_16 : 383|4@0+ (1,0) [0|15] ""  IDM
 SG_ MRR_ObjDistYStd_16 : 373|6@0+ (0.1,0) [0|6] "m"  IDM
 SG_ MRR_ObjDistXStd_16 : 363|6@0+ (0.1,0) [0|6] "m"  IDM
 SG_ MRR_ObjRelAccelY_16 : 357|10@0+ (0.03125,-16) [-16|15.96875] "mps2"  IDM
 SG_ MRR_ObjRelVelY_16 : 338|13@0+ (0.0312,-128) [-128|126.9976] "mps"  IDM
 SG_ MRR_ObjRelVelX_16 : 335|13@0+ (0.0312,-128) [-128|126.9976] "mps"  IDM
 SG_ Checksum62 : 327|8@0+ (1,0) [0|255] ""  IDM
 SG_ RollingCounter61 : 315|4@0+ (1,0) [0|15] ""  IDM
 SG_ MRR_ObjRelAccelX_16 : 310|10@0+ (0.03125,-16) [-16|15.96875] "mps2"  IDM
 SG_ MRR_ObjDistY_16 : 289|11@0+ (0.125,-128) [-128|127.875] "m"  IDM
 SG_ MRR_ObjDistX_16 : 285|12@0+ (0.0625,0) [0|254.9375] "m"  IDM
 SG_ MRR_ObjObstacleProb_16 : 274|5@0+ (0.03125,0) [0|0.96875] ""  IDM
 SG_ MRR_ObjExistProb_16 : 279|5@0+ (0.03125,0) [0|0.96875] ""  IDM
 SG_ MRR_ObjID_16 : 271|8@0+ (1,0) [0|255] ""  IDM
 SG_ Checksum61 : 263|8@0+ (1,0) [0|255] ""  IDM
 SG_ RollingCounter60 : 251|4@0+ (1,0) [0|15] ""  IDM
 SG_ MRR_ObjRefPoint_15 : 243|3@0+ (1,0) [0|7] "NoUnit"  IDM
 SG_ MRR_ObjRefPoint_16 : 247|3@0+ (1,0) [0|7] "NoUnit"  IDM
 SG_ MRR_ObjAge_15 : 239|8@0+ (1,0) [0|255] ""  IDM
 SG_ MRR_ObjRCS_15 : 217|10@0+ (0.125,-50) [-50|70] "dBm2"  IDM
 SG_ MRR_ObjHeading_15 : 213|12@0+ (0.002,-3.14) [-3.14|3.14] "rad"  IDM
 SG_ VFC_ObjHeight_15 : 207|10@0+ (0.01,0) [0|6] "m"  IDM
 SG_ Checksum60 : 199|8@0+ (1,0) [0|255] ""  IDM
 SG_ RollingCounter59 : 187|4@0+ (1,0) [0|15] ""  IDM
 SG_ VFC_ObjMotionDirection_15 : 176|3@0+ (1,0) [0|7] ""  IDM
 SG_ VFC_ObjLength_15 : 170|10@0+ (0.05,0) [0|20] "m"  IDM
 SG_ VFC_ObjWidth_15 : 164|10@0+ (0.01,0) [0|5] "m"  IDM
 SG_ MRR_ObjMotionType_15 : 167|3@0+ (1,0) [0|7] ""  IDM
 SG_ MRR_ObjRAccelYStd_15 : 157|6@0+ (0.0625,0) [0|3.9375] "mps2"  IDM
 SG_ MRR_ObjRAccelXStd_15 : 147|6@0+ (0.0625,0) [0|3.9375] "mps2"  IDM
 SG_ MRR_ObjRelVelYStd_15 : 137|6@0+ (0.0625,0) [0|3.9375] "mps"  IDM
 SG_ MRR_ObjRelVelXStd_15 : 143|6@0+ (0.0625,0) [0|3.9375] "mps"  IDM
 SG_ Checksum59 : 135|8@0+ (1,0) [0|255] ""  IDM
 SG_ RollingCounter58 : 123|4@0+ (1,0) [0|15] ""  IDM
 SG_ MRR_ObjType_15 : 127|4@0+ (1,0) [0|15] ""  IDM
 SG_ MRR_ObjDistYStd_15 : 117|6@0+ (0.1,0) [0|6] "m"  IDM
 SG_ MRR_ObjDistXStd_15 : 107|6@0+ (0.1,0) [0|6] "m"  IDM
 SG_ MRR_ObjRelAccelY_15 : 101|10@0+ (0.03125,-16) [-16|15.96875] "mps2"  IDM
 SG_ MRR_ObjRelVelY_15 : 82|13@0+ (0.0312,-128) [-128|126.9976] "mps"  IDM
 SG_ MRR_ObjRelVelX_15 : 79|13@0+ (0.0312,-128) [-128|126.9976] "mps"  IDM
 SG_ Checksum58 : 71|8@0+ (1,0) [0|255] ""  IDM
 SG_ RollingCounter57 : 59|4@0+ (1,0) [0|15] ""  IDM
 SG_ MRR_ObjRelAccelX_15 : 54|10@0+ (0.03125,-16) [-16|15.96875] "mps2"  IDM
 SG_ MRR_ObjDistY_15 : 33|11@0+ (0.125,-128) [-128|127.875] "m"  IDM
 SG_ MRR_ObjDistX_15 : 29|12@0+ (0.0625,0) [0|254.9375] "m"  IDM
 SG_ MRR_ObjObstacleProb_15 : 18|5@0+ (0.03125,0) [0|0.96875] ""  IDM
 SG_ MRR_ObjExistProb_15 : 23|5@0+ (0.03125,0) [0|0.96875] ""  IDM
 SG_ MRR_ObjID_15 : 15|8@0+ (1,0) [0|255] ""  IDM
 SG_ Checksum57 : 7|8@0+ (1,0) [0|255] ""  IDM

BO_ 1080 MRRAD9: 64 FR
 SG_ RollingCounter72 : 507|4@0+ (1,0) [0|15] ""  IDM
 SG_ MRR_ObjMeasured_17 : 497|2@0+ (1,0) [0|3] ""  IDM
 SG_ MRR_ObjMeasured_18 : 499|2@0+ (1,0) [0|3] ""  IDM
 SG_ MRR_ObjHeading_18 : 495|12@0+ (0.002,-3.14) [-3.14|3.14] "rad"  IDM
 SG_ MRR_ObjAge_18 : 487|8@0+ (1,0) [0|255] ""  IDM
 SG_ MRR_ObjRCS_18 : 465|10@0+ (0.125,-50) [-50|70] "dBm2"  IDM
 SG_ BlockCounter9 : 469|4@0+ (1,0) [0|15] ""  IDM
 SG_ VFC_ObjHeight_18 : 463|10@0+ (0.01,0) [0|6] "m"  IDM
 SG_ Checksum72 : 455|8@0+ (1,0) [0|255] ""  IDM
 SG_ RollingCounter71 : 443|4@0+ (1,0) [0|15] ""  IDM
 SG_ VFC_ObjMotionDirection_18 : 432|3@0+ (1,0) [0|7] ""  IDM
 SG_ VFC_ObjLength_18 : 426|10@0+ (0.05,0) [0|20] "m"  IDM
 SG_ VFC_ObjWidth_18 : 420|10@0+ (0.01,0) [0|5] "m"  IDM
 SG_ MRR_ObjMotionType_18 : 423|3@0+ (1,0) [0|7] ""  IDM
 SG_ MRR_ObjRAccelYStd_18 : 413|6@0+ (0.0625,0) [0|3.9375] "mps2"  IDM
 SG_ MRR_ObjRAccelXStd_18 : 403|6@0+ (0.0625,0) [0|3.9375] "mps2"  IDM
 SG_ MRR_ObjRelVelYStd_18 : 393|6@0+ (0.0625,0) [0|3.9375] "mps"  IDM
 SG_ MRR_ObjRelVelXStd_18 : 399|6@0+ (0.0625,0) [0|3.9375] "mps"  IDM
 SG_ Checksum71 : 391|8@0+ (1,0) [0|255] ""  IDM
 SG_ RollingCounter70 : 379|4@0+ (1,0) [0|15] ""  IDM
 SG_ MRR_ObjType_18 : 383|4@0+ (1,0) [0|15] ""  IDM
 SG_ MRR_ObjDistYStd_18 : 373|6@0+ (0.1,0) [0|6] "m"  IDM
 SG_ MRR_ObjDistXStd_18 : 363|6@0+ (0.1,0) [0|6] "m"  IDM
 SG_ MRR_ObjRelAccelY_18 : 357|10@0+ (0.03125,-16) [-16|15.96875] "mps2"  IDM
 SG_ MRR_ObjRelVelY_18 : 338|13@0+ (0.0312,-128) [-128|126.9976] "mps"  IDM
 SG_ MRR_ObjRelVelX_18 : 335|13@0+ (0.0312,-128) [-128|126.9976] "mps"  IDM
 SG_ Checksum70 : 327|8@0+ (1,0) [0|255] ""  IDM
 SG_ RollingCounter69 : 315|4@0+ (1,0) [0|15] ""  IDM
 SG_ MRR_ObjRelAccelX_18 : 310|10@0+ (0.03125,-16) [-16|15.96875] "mps2"  IDM
 SG_ MRR_ObjDistY_18 : 289|11@0+ (0.125,-128) [-128|127.875] "m"  IDM
 SG_ MRR_ObjDistX_18 : 285|12@0+ (0.0625,0) [0|254.9375] "m"  IDM
 SG_ MRR_ObjObstacleProb_18 : 274|5@0+ (0.03125,0) [0|0.96875] ""  IDM
 SG_ MRR_ObjExistProb_18 : 279|5@0+ (0.03125,0) [0|0.96875] ""  IDM
 SG_ MRR_ObjID_18 : 271|8@0+ (1,0) [0|255] ""  IDM
 SG_ Checksum69 : 263|8@0+ (1,0) [0|255] ""  IDM
 SG_ RollingCounter68 : 251|4@0+ (1,0) [0|15] ""  IDM
 SG_ MRR_ObjRefPoint_17 : 243|3@0+ (1,0) [0|7] "NoUnit"  IDM
 SG_ MRR_ObjRefPoint_18 : 247|3@0+ (1,0) [0|7] "NoUnit"  IDM
 SG_ MRR_ObjAge_17 : 239|8@0+ (1,0) [0|255] ""  IDM
 SG_ MRR_ObjRCS_17 : 217|10@0+ (0.125,-50) [-50|70] "dBm2"  IDM
 SG_ MRR_ObjHeading_17 : 213|12@0+ (0.002,-3.14) [-3.14|3.14] "rad"  IDM
 SG_ VFC_ObjHeight_17 : 207|10@0+ (0.01,0) [0|6] "m"  IDM
 SG_ Checksum68 : 199|8@0+ (1,0) [0|255] ""  IDM
 SG_ RollingCounter67 : 187|4@0+ (1,0) [0|15] ""  IDM
 SG_ VFC_ObjMotionDirection_17 : 176|3@0+ (1,0) [0|7] ""  IDM
 SG_ VFC_ObjLength_17 : 170|10@0+ (0.05,0) [0|20] "m"  IDM
 SG_ VFC_ObjWidth_17 : 164|10@0+ (0.01,0) [0|5] "m"  IDM
 SG_ MRR_ObjMotionType_17 : 167|3@0+ (1,0) [0|7] ""  IDM
 SG_ MRR_ObjRAccelYStd_17 : 157|6@0+ (0.0625,0) [0|3.9375] "mps2"  IDM
 SG_ MRR_ObjRAccelXStd_17 : 147|6@0+ (0.0625,0) [0|3.9375] "mps2"  IDM
 SG_ MRR_ObjRelVelYStd_17 : 137|6@0+ (0.0625,0) [0|3.9375] "mps"  IDM
 SG_ MRR_ObjRelVelXStd_17 : 143|6@0+ (0.0625,0) [0|3.9375] "mps"  IDM
 SG_ Checksum67 : 135|8@0+ (1,0) [0|255] ""  IDM
 SG_ RollingCounter66 : 123|4@0+ (1,0) [0|15] ""  IDM
 SG_ MRR_ObjType_17 : 127|4@0+ (1,0) [0|15] ""  IDM
 SG_ MRR_ObjDistYStd_17 : 117|6@0+ (0.1,0) [0|6] "m"  IDM
 SG_ MRR_ObjDistXStd_17 : 107|6@0+ (0.1,0) [0|6] "m"  IDM
 SG_ MRR_ObjRelAccelY_17 : 101|10@0+ (0.03125,-16) [-16|15.96875] "mps2"  IDM
 SG_ MRR_ObjRelVelY_17 : 82|13@0+ (0.0312,-128) [-128|126.9976] "mps"  IDM
 SG_ MRR_ObjRelVelX_17 : 79|13@0+ (0.0312,-128) [-128|126.9976] "mps"  IDM
 SG_ Checksum66 : 71|8@0+ (1,0) [0|255] ""  IDM
 SG_ RollingCounter65 : 59|4@0+ (1,0) [0|15] ""  IDM
 SG_ MRR_ObjRelAccelX_17 : 54|10@0+ (0.03125,-16) [-16|15.96875] "mps2"  IDM
 SG_ MRR_ObjDistY_17 : 33|11@0+ (0.125,-128) [-128|127.875] "m"  IDM
 SG_ MRR_ObjDistX_17 : 29|12@0+ (0.0625,0) [0|254.9375] "m"  IDM
 SG_ MRR_ObjObstacleProb_17 : 18|5@0+ (0.03125,0) [0|0.96875] ""  IDM
 SG_ MRR_ObjExistProb_17 : 23|5@0+ (0.03125,0) [0|0.96875] ""  IDM
 SG_ MRR_ObjID_17 : 15|8@0+ (1,0) [0|255] ""  IDM
 SG_ Checksum65 : 7|8@0+ (1,0) [0|255] ""  IDM

BO_ 1081 MRRAD10: 64 FR
 SG_ RollingCounter80 : 507|4@0+ (1,0) [0|15] ""  IDM
 SG_ MRR_ObjMeasured_19 : 497|2@0+ (1,0) [0|3] ""  IDM
 SG_ MRR_ObjMeasured_20 : 499|2@0+ (1,0) [0|3] ""  IDM
 SG_ MRR_ObjHeading_20 : 495|12@0+ (0.002,-3.14) [-3.14|3.14] "rad"  IDM
 SG_ MRR_ObjAge_20 : 487|8@0+ (1,0) [0|255] ""  IDM
 SG_ MRR_ObjRCS_20 : 465|10@0+ (0.125,-50) [-50|70] "dBm2"  IDM
 SG_ BlockCounter10 : 469|4@0+ (1,0) [0|15] ""  IDM
 SG_ VFC_ObjHeight_20 : 463|10@0+ (0.01,0) [0|6] "m"  IDM
 SG_ Checksum80 : 455|8@0+ (1,0) [0|255] ""  IDM
 SG_ RollingCounter79 : 443|4@0+ (1,0) [0|15] ""  IDM
 SG_ VFC_ObjMotionDirection_20 : 432|3@0+ (1,0) [0|7] ""  IDM
 SG_ VFC_ObjLength_20 : 426|10@0+ (0.05,0) [0|20] "m"  IDM
 SG_ VFC_ObjWidth_20 : 420|10@0+ (0.01,0) [0|5] "m"  IDM
 SG_ MRR_ObjMotionType_20 : 423|3@0+ (1,0) [0|7] ""  IDM
 SG_ MRR_ObjRAccelYStd_20 : 413|6@0+ (0.0625,0) [0|3.9375] "mps2"  IDM
 SG_ MRR_ObjRAccelXStd_20 : 403|6@0+ (0.0625,0) [0|3.9375] "mps2"  IDM
 SG_ MRR_ObjRelVelYStd_20 : 393|6@0+ (0.0625,0) [0|3.9375] "mps"  IDM
 SG_ MRR_ObjRelVelXStd_20 : 399|6@0+ (0.0625,0) [0|3.9375] "mps"  IDM
 SG_ Checksum79 : 391|8@0+ (1,0) [0|255] ""  IDM
 SG_ RollingCounter78 : 379|4@0+ (1,0) [0|15] ""  IDM
 SG_ MRR_ObjType_20 : 383|4@0+ (1,0) [0|15] ""  IDM
 SG_ MRR_ObjDistYStd_20 : 373|6@0+ (0.1,0) [0|6] "m"  IDM
 SG_ MRR_ObjDistXStd_20 : 363|6@0+ (0.1,0) [0|6] "m"  IDM
 SG_ MRR_ObjRelAccelY_20 : 357|10@0+ (0.03125,-16) [-16|15.96875] "mps2"  IDM
 SG_ MRR_ObjRelVelY_20 : 338|13@0+ (0.0312,-128) [-128|126.9976] "mps"  IDM
 SG_ MRR_ObjRelVelX_20 : 335|13@0+ (0.0312,-128) [-128|126.9976] "mps"  IDM
 SG_ Checksum78 : 327|8@0+ (1,0) [0|255] ""  IDM
 SG_ RollingCounter77 : 315|4@0+ (1,0) [0|15] ""  IDM
 SG_ MRR_ObjRelAccelX_20 : 310|10@0+ (0.03125,-16) [-16|15.96875] "mps2"  IDM
 SG_ MRR_ObjDistY_20 : 289|11@0+ (0.125,-128) [-128|127.875] "m"  IDM
 SG_ MRR_ObjDistX_20 : 285|12@0+ (0.0625,0) [0|254.9375] "m"  IDM
 SG_ MRR_ObjObstacleProb_20 : 274|5@0+ (0.03125,0) [0|0.96875] ""  IDM
 SG_ MRR_ObjExistProb_20 : 279|5@0+ (0.03125,0) [0|0.96875] ""  IDM
 SG_ MRR_ObjID_20 : 271|8@0+ (1,0) [0|255] ""  IDM
 SG_ Checksum77 : 263|8@0+ (1,0) [0|255] ""  IDM
 SG_ RollingCounter76 : 251|4@0+ (1,0) [0|15] ""  IDM
 SG_ MRR_ObjRefPoint_19 : 243|3@0+ (1,0) [0|7] "NoUnit"  IDM
 SG_ MRR_ObjRefPoint_20 : 247|3@0+ (1,0) [0|7] "NoUnit"  IDM
 SG_ MRR_ObjAge_19 : 239|8@0+ (1,0) [0|255] ""  IDM
 SG_ MRR_ObjRCS_19 : 217|10@0+ (0.125,-50) [-50|70] "dBm2"  IDM
 SG_ MRR_ObjHeading_19 : 213|12@0+ (0.002,-3.14) [-3.14|3.14] "rad"  IDM
 SG_ VFC_ObjHeight_19 : 207|10@0+ (0.01,0) [0|6] "m"  IDM
 SG_ Checksum76 : 199|8@0+ (1,0) [0|255] ""  IDM
 SG_ RollingCounter75 : 187|4@0+ (1,0) [0|15] ""  IDM
 SG_ VFC_ObjMotionDirection_19 : 176|3@0+ (1,0) [0|7] ""  IDM
 SG_ VFC_ObjLength_19 : 170|10@0+ (0.05,0) [0|20] "m"  IDM
 SG_ VFC_ObjWidth_19 : 164|10@0+ (0.01,0) [0|5] "m"  IDM
 SG_ MRR_ObjMotionType_19 : 167|3@0+ (1,0) [0|7] ""  IDM
 SG_ MRR_ObjRAccelYStd_19 : 157|6@0+ (0.0625,0) [0|3.9375] "mps2"  IDM
 SG_ MRR_ObjRAccelXStd_19 : 147|6@0+ (0.0625,0) [0|3.9375] "mps2"  IDM
 SG_ MRR_ObjRelVelYStd_19 : 137|6@0+ (0.0625,0) [0|3.9375] "mps"  IDM
 SG_ MRR_ObjRelVelXStd_19 : 143|6@0+ (0.0625,0) [0|3.9375] "mps"  IDM
 SG_ Checksum75 : 135|8@0+ (1,0) [0|255] ""  IDM
 SG_ RollingCounter74 : 123|4@0+ (1,0) [0|15] ""  IDM
 SG_ MRR_ObjType_19 : 127|4@0+ (1,0) [0|15] ""  IDM
 SG_ MRR_ObjDistYStd_19 : 117|6@0+ (0.1,0) [0|6] "m"  IDM
 SG_ MRR_ObjDistXStd_19 : 107|6@0+ (0.1,0) [0|6] "m"  IDM
 SG_ MRR_ObjRelAccelY_19 : 101|10@0+ (0.03125,-16) [-16|15.96875] "mps2"  IDM
 SG_ MRR_ObjRelVelY_19 : 82|13@0+ (0.0312,-128) [-128|126.9976] "mps"  IDM
 SG_ MRR_ObjRelVelX_19 : 79|13@0+ (0.0312,-128) [-128|126.9976] "mps"  IDM
 SG_ Checksum74 : 71|8@0+ (1,0) [0|255] ""  IDM
 SG_ RollingCounter73 : 59|4@0+ (1,0) [0|15] ""  IDM
 SG_ MRR_ObjRelAccelX_19 : 54|10@0+ (0.03125,-16) [-16|15.96875] "mps2"  IDM
 SG_ MRR_ObjDistY_19 : 33|11@0+ (0.125,-128) [-128|127.875] "m"  IDM
 SG_ MRR_ObjDistX_19 : 29|12@0+ (0.0625,0) [0|254.9375] "m"  IDM
 SG_ MRR_ObjObstacleProb_19 : 18|5@0+ (0.03125,0) [0|0.96875] ""  IDM
 SG_ MRR_ObjExistProb_19 : 23|5@0+ (0.03125,0) [0|0.96875] ""  IDM
 SG_ MRR_ObjID_19 : 15|8@0+ (1,0) [0|255] ""  IDM
 SG_ Checksum73 : 7|8@0+ (1,0) [0|255] ""  IDM

BO_ 1082 MRRAD11: 64 FR
 SG_ RollingCounter88 : 507|4@0+ (1,0) [0|15] ""  IDM
 SG_ MRR_ObjMeasured_21 : 497|2@0+ (1,0) [0|3] ""  IDM
 SG_ MRR_ObjMeasured_22 : 499|2@0+ (1,0) [0|3] ""  IDM
 SG_ MRR_ObjHeading_22 : 495|12@0+ (0.002,-3.14) [-3.14|3.14] "rad"  IDM
 SG_ MRR_ObjAge_22 : 487|8@0+ (1,0) [0|255] ""  IDM
 SG_ MRR_ObjRCS_22 : 465|10@0+ (0.125,-50) [-50|70] "dBm2"  IDM
 SG_ BlockCounter11 : 469|4@0+ (1,0) [0|15] ""  IDM
 SG_ VFC_ObjHeight_22 : 463|10@0+ (0.01,0) [0|6] "m"  IDM
 SG_ Checksum88 : 455|8@0+ (1,0) [0|255] ""  IDM
 SG_ RollingCounter87 : 443|4@0+ (1,0) [0|15] ""  IDM
 SG_ VFC_ObjMotionDirection_22 : 432|3@0+ (1,0) [0|7] ""  IDM
 SG_ VFC_ObjLength_22 : 426|10@0+ (0.05,0) [0|20] "m"  IDM
 SG_ VFC_ObjWidth_22 : 420|10@0+ (0.01,0) [0|5] "m"  IDM
 SG_ MRR_ObjMotionType_22 : 423|3@0+ (1,0) [0|7] ""  IDM
 SG_ MRR_ObjRAccelYStd_22 : 413|6@0+ (0.0625,0) [0|3.9375] "mps2"  IDM
 SG_ MRR_ObjRAccelXStd_22 : 403|6@0+ (0.0625,0) [0|3.9375] "mps2"  IDM
 SG_ MRR_ObjRelVelYStd_22 : 393|6@0+ (0.0625,0) [0|3.9375] "mps"  IDM
 SG_ MRR_ObjRelVelXStd_22 : 399|6@0+ (0.0625,0) [0|3.9375] "mps"  IDM
 SG_ Checksum87 : 391|8@0+ (1,0) [0|255] ""  IDM
 SG_ RollingCounter86 : 379|4@0+ (1,0) [0|15] ""  IDM
 SG_ MRR_ObjType_22 : 383|4@0+ (1,0) [0|15] ""  IDM
 SG_ MRR_ObjDistYStd_22 : 373|6@0+ (0.1,0) [0|6] "m"  IDM
 SG_ MRR_ObjDistXStd_22 : 363|6@0+ (0.1,0) [0|6] "m"  IDM
 SG_ MRR_ObjRelAccelY_22 : 357|10@0+ (0.03125,-16) [-16|15.96875] "mps2"  IDM
 SG_ MRR_ObjRelVelY_22 : 338|13@0+ (0.0312,-128) [-128|126.9976] "mps"  IDM
 SG_ MRR_ObjRelVelX_22 : 335|13@0+ (0.0312,-128) [-128|126.9976] "mps"  IDM
 SG_ Checksum86 : 327|8@0+ (1,0) [0|255] ""  IDM
 SG_ RollingCounter85 : 315|4@0+ (1,0) [0|15] ""  IDM
 SG_ MRR_ObjRelAccelX_22 : 310|10@0+ (0.03125,-16) [-16|15.96875] "mps2"  IDM
 SG_ MRR_ObjDistY_22 : 289|11@0+ (0.125,-128) [-128|127.875] "m"  IDM
 SG_ MRR_ObjDistX_22 : 285|12@0+ (0.0625,0) [0|254.9375] "m"  IDM
 SG_ MRR_ObjObstacleProb_22 : 274|5@0+ (0.03125,0) [0|0.96875] ""  IDM
 SG_ MRR_ObjExistProb_22 : 279|5@0+ (0.03125,0) [0|0.96875] ""  IDM
 SG_ MRR_ObjID_22 : 271|8@0+ (1,0) [0|255] ""  IDM
 SG_ Checksum85 : 263|8@0+ (1,0) [0|255] ""  IDM
 SG_ RollingCounter84 : 251|4@0+ (1,0) [0|15] ""  IDM
 SG_ MRR_ObjRefPoint_21 : 243|3@0+ (1,0) [0|7] "NoUnit"  IDM
 SG_ MRR_ObjRefPoint_22 : 247|3@0+ (1,0) [0|7] "NoUnit"  IDM
 SG_ MRR_ObjAge_21 : 239|8@0+ (1,0) [0|255] ""  IDM
 SG_ MRR_ObjRCS_21 : 217|10@0+ (0.125,-50) [-50|70] "dBm2"  IDM
 SG_ MRR_ObjHeading_21 : 213|12@0+ (0.002,-3.14) [-3.14|3.14] "rad"  IDM
 SG_ VFC_ObjHeight_21 : 207|10@0+ (0.01,0) [0|6] "m"  IDM
 SG_ Checksum84 : 199|8@0+ (1,0) [0|255] ""  IDM
 SG_ RollingCounter83 : 187|4@0+ (1,0) [0|15] ""  IDM
 SG_ VFC_ObjMotionDirection_21 : 176|3@0+ (1,0) [0|7] ""  IDM
 SG_ VFC_ObjLength_21 : 170|10@0+ (0.05,0) [0|20] "m"  IDM
 SG_ VFC_ObjWidth_21 : 164|10@0+ (0.01,0) [0|5] "m"  IDM
 SG_ MRR_ObjMotionType_21 : 167|3@0+ (1,0) [0|7] ""  IDM
 SG_ MRR_ObjRAccelYStd_21 : 157|6@0+ (0.0625,0) [0|3.9375] "mps2"  IDM
 SG_ MRR_ObjRAccelXStd_21 : 147|6@0+ (0.0625,0) [0|3.9375] "mps2"  IDM
 SG_ MRR_ObjRelVelYStd_21 : 137|6@0+ (0.0625,0) [0|3.9375] "mps"  IDM
 SG_ MRR_ObjRelVelXStd_21 : 143|6@0+ (0.0625,0) [0|3.9375] "mps"  IDM
 SG_ Checksum83 : 135|8@0+ (1,0) [0|255] ""  IDM
 SG_ RollingCounter82 : 123|4@0+ (1,0) [0|15] ""  IDM
 SG_ MRR_ObjType_21 : 127|4@0+ (1,0) [0|15] ""  IDM
 SG_ MRR_ObjDistYStd_21 : 117|6@0+ (0.1,0) [0|6] "m"  IDM
 SG_ MRR_ObjDistXStd_21 : 107|6@0+ (0.1,0) [0|6] "m"  IDM
 SG_ MRR_ObjRelAccelY_21 : 101|10@0+ (0.03125,-16) [-16|15.96875] "mps2"  IDM
 SG_ MRR_ObjRelVelY_21 : 82|13@0+ (0.0312,-128) [-128|126.9976] "mps"  IDM
 SG_ MRR_ObjRelVelX_21 : 79|13@0+ (0.0312,-128) [-128|126.9976] "mps"  IDM
 SG_ Checksum82 : 71|8@0+ (1,0) [0|255] ""  IDM
 SG_ RollingCounter81 : 59|4@0+ (1,0) [0|15] ""  IDM
 SG_ MRR_ObjRelAccelX_21 : 54|10@0+ (0.03125,-16) [-16|15.96875] "mps2"  IDM
 SG_ MRR_ObjDistY_21 : 33|11@0+ (0.125,-128) [-128|127.875] "m"  IDM
 SG_ MRR_ObjDistX_21 : 29|12@0+ (0.0625,0) [0|254.9375] "m"  IDM
 SG_ MRR_ObjObstacleProb_21 : 18|5@0+ (0.03125,0) [0|0.96875] ""  IDM
 SG_ MRR_ObjExistProb_21 : 23|5@0+ (0.03125,0) [0|0.96875] ""  IDM
 SG_ MRR_ObjID_21 : 15|8@0+ (1,0) [0|255] ""  IDM
 SG_ Checksum81 : 7|8@0+ (1,0) [0|255] ""  IDM

BO_ 1083 MRRAD12: 64 FR
 SG_ RollingCounter96 : 507|4@0+ (1,0) [0|15] ""  IDM
 SG_ MRR_ObjMeasured_23 : 497|2@0+ (1,0) [0|3] ""  IDM
 SG_ MRR_ObjMeasured_24 : 499|2@0+ (1,0) [0|3] ""  IDM
 SG_ MRR_ObjHeading_24 : 495|12@0+ (0.002,-3.14) [-3.14|3.14] "rad"  IDM
 SG_ MRR_ObjAge_24 : 487|8@0+ (1,0) [0|255] ""  IDM
 SG_ MRR_ObjRCS_24 : 465|10@0+ (0.125,-50) [-50|70] "dBm2"  IDM
 SG_ BlockCounter12 : 469|4@0+ (1,0) [0|15] ""  IDM
 SG_ VFC_ObjHeight_24 : 463|10@0+ (0.01,0) [0|6] "m"  IDM
 SG_ Checksum96 : 455|8@0+ (1,0) [0|255] ""  IDM
 SG_ RollingCounter95 : 443|4@0+ (1,0) [0|15] ""  IDM
 SG_ VFC_ObjMotionDirection_24 : 432|3@0+ (1,0) [0|7] ""  IDM
 SG_ VFC_ObjLength_24 : 426|10@0+ (0.05,0) [0|20] "m"  IDM
 SG_ VFC_ObjWidth_24 : 420|10@0+ (0.01,0) [0|5] "m"  IDM
 SG_ MRR_ObjMotionType_24 : 423|3@0+ (1,0) [0|7] ""  IDM
 SG_ MRR_ObjRAccelYStd_24 : 413|6@0+ (0.0625,0) [0|3.9375] "mps2"  IDM
 SG_ MRR_ObjRAccelXStd_24 : 403|6@0+ (0.0625,0) [0|3.9375] "mps2"  IDM
 SG_ MRR_ObjRelVelYStd_24 : 393|6@0+ (0.0625,0) [0|3.9375] "mps"  IDM
 SG_ MRR_ObjRelVelXStd_24 : 399|6@0+ (0.0625,0) [0|3.9375] "mps"  IDM
 SG_ Checksum95 : 391|8@0+ (1,0) [0|255] ""  IDM
 SG_ RollingCounter94 : 379|4@0+ (1,0) [0|15] ""  IDM
 SG_ MRR_ObjType_24 : 383|4@0+ (1,0) [0|15] ""  IDM
 SG_ MRR_ObjDistYStd_24 : 373|6@0+ (0.1,0) [0|6] "m"  IDM
 SG_ MRR_ObjDistXStd_24 : 363|6@0+ (0.1,0) [0|6] "m"  IDM
 SG_ MRR_ObjRelAccelY_24 : 357|10@0+ (0.03125,-16) [-16|15.96875] "mps2"  IDM
 SG_ MRR_ObjRelVelY_24 : 338|13@0+ (0.0312,-128) [-128|126.9976] "mps"  IDM
 SG_ MRR_ObjRelVelX_24 : 335|13@0+ (0.0312,-128) [-128|126.9976] "mps"  IDM
 SG_ Checksum94 : 327|8@0+ (1,0) [0|255] ""  IDM
 SG_ RollingCounter93 : 315|4@0+ (1,0) [0|15] ""  IDM
 SG_ MRR_ObjRelAccelX_24 : 310|10@0+ (0.03125,-16) [-16|15.96875] "mps2"  IDM
 SG_ MRR_ObjDistY_24 : 289|11@0+ (0.125,-128) [-128|127.875] "m"  IDM
 SG_ MRR_ObjDistX_24 : 285|12@0+ (0.0625,0) [0|254.9375] "m"  IDM
 SG_ MRR_ObjObstacleProb_24 : 274|5@0+ (0.03125,0) [0|0.96875] ""  IDM
 SG_ MRR_ObjExistProb_24 : 279|5@0+ (0.03125,0) [0|0.96875] ""  IDM
 SG_ MRR_ObjID_24 : 271|8@0+ (1,0) [0|255] ""  IDM
 SG_ Checksum93 : 263|8@0+ (1,0) [0|255] ""  IDM
 SG_ RollingCounter92 : 251|4@0+ (1,0) [0|15] ""  IDM
 SG_ MRR_ObjRefPoint_23 : 243|3@0+ (1,0) [0|7] "NoUnit"  IDM
 SG_ MRR_ObjRefPoint_24 : 247|3@0+ (1,0) [0|7] "NoUnit"  IDM
 SG_ MRR_ObjAge_23 : 239|8@0+ (1,0) [0|255] ""  IDM
 SG_ MRR_ObjRCS_23 : 217|10@0+ (0.125,-50) [-50|70] "dBm2"  IDM
 SG_ MRR_ObjHeading_23 : 213|12@0+ (0.002,-3.14) [-3.14|3.14] "rad"  IDM
 SG_ VFC_ObjHeight_23 : 207|10@0+ (0.01,0) [0|6] "m"  IDM
 SG_ Checksum92 : 199|8@0+ (1,0) [0|255] ""  IDM
 SG_ RollingCounter91 : 187|4@0+ (1,0) [0|15] ""  IDM
 SG_ VFC_ObjMotionDirection_23 : 176|3@0+ (1,0) [0|7] ""  IDM
 SG_ VFC_ObjLength_23 : 170|10@0+ (0.05,0) [0|20] "m"  IDM
 SG_ VFC_ObjWidth_23 : 164|10@0+ (0.01,0) [0|5] "m"  IDM
 SG_ MRR_ObjMotionType_23 : 167|3@0+ (1,0) [0|7] ""  IDM
 SG_ MRR_ObjRAccelYStd_23 : 157|6@0+ (0.0625,0) [0|3.9375] "mps2"  IDM
 SG_ MRR_ObjRAccelXStd_23 : 147|6@0+ (0.0625,0) [0|3.9375] "mps2"  IDM
 SG_ MRR_ObjRelVelYStd_23 : 137|6@0+ (0.0625,0) [0|3.9375] "mps"  IDM
 SG_ MRR_ObjRelVelXStd_23 : 143|6@0+ (0.0625,0) [0|3.9375] "mps"  IDM
 SG_ Checksum91 : 135|8@0+ (1,0) [0|255] ""  IDM
 SG_ RollingCounter90 : 123|4@0+ (1,0) [0|15] ""  IDM
 SG_ MRR_ObjType_23 : 127|4@0+ (1,0) [0|15] ""  IDM
 SG_ MRR_ObjDistYStd_23 : 117|6@0+ (0.1,0) [0|6] "m"  IDM
 SG_ MRR_ObjDistXStd_23 : 107|6@0+ (0.1,0) [0|6] "m"  IDM
 SG_ MRR_ObjRelAccelY_23 : 101|10@0+ (0.03125,-16) [-16|15.96875] "mps2"  IDM
 SG_ MRR_ObjRelVelY_23 : 82|13@0+ (0.0312,-128) [-128|126.9976] "mps"  IDM
 SG_ MRR_ObjRelVelX_23 : 79|13@0+ (0.0312,-128) [-128|126.9976] "mps"  IDM
 SG_ Checksum90 : 71|8@0+ (1,0) [0|255] ""  IDM
 SG_ RollingCounter89 : 59|4@0+ (1,0) [0|15] ""  IDM
 SG_ MRR_ObjRelAccelX_23 : 54|10@0+ (0.03125,-16) [-16|15.96875] "mps2"  IDM
 SG_ MRR_ObjDistY_23 : 33|11@0+ (0.125,-128) [-128|127.875] "m"  IDM
 SG_ MRR_ObjDistX_23 : 29|12@0+ (0.0625,0) [0|254.9375] "m"  IDM
 SG_ MRR_ObjObstacleProb_23 : 18|5@0+ (0.03125,0) [0|0.96875] ""  IDM
 SG_ MRR_ObjExistProb_23 : 23|5@0+ (0.03125,0) [0|0.96875] ""  IDM
 SG_ MRR_ObjID_23 : 15|8@0+ (1,0) [0|255] ""  IDM
 SG_ Checksum89 : 7|8@0+ (1,0) [0|255] ""  IDM

CM_ SG_ 545 TGS_LEVER "B";
CM_ SG_ 901 ACAmbTemp "/";
BA_DEF_ BO_  "GenMsgILSupport" ENUM  "No","Yes";
BA_DEF_ BO_  "VFrameFormat" ENUM  "StandardCAN","ExtendedCAN","reserved","reserved","reserved","reserved","reserved","reserved","reserved","reserved","reserved","reserved","reserved","reserved","StandardCAN_FD","ExtendedCAN_FD";
BA_DEF_ SG_  "GenSigSendType" ENUM  "Cyclic","OnWrite","OnWriteWithRepetition","OnChange","OnChangeWithRepetition","IfActive","IfActiveWithRepetition","NoSigSendType","CyclicAndSpontanX","NotUsed","Event","CE";
BA_DEF_ SG_  "IsMonitor" ENUM  "*","Monitor";
BA_DEF_  "DBName" STRING ;
BA_DEF_  "BusType" STRING ;
BA_DEF_  "Manufacturer" STRING ;
BA_DEF_ SG_  "UnitConversionFactor" FLOAT -100 100;
BA_DEF_ SG_  "SigInvalidSetFlag" ENUM  "*","Yes";
BA_DEF_ SG_  "Internal_type" ENUM  "*","UB","UW","UL","SB","SW","SL";
BA_DEF_ SG_  "IsCrcSignal" ENUM  "No","Yes";
BA_DEF_ SG_  "IsRcSignal" ENUM  "No","Yes";
BA_DEF_ BO_  "GenMsgSendType" ENUM  "Cyclic","Event","CE","NotUsed","NotUsed","NotUsed","NotUsed","NotUsed","NoMsgSendType","IfActive","IfActiveWithRepetition","CyclicAndSpontanX";
BA_DEF_ SG_  "GenSigStartValue" INT 0 2147483647;
BA_DEF_ BO_  "MsgType" ENUM  "Normal","NM","Diag","vector_leerstring";
BA_DEF_ BO_  "GenMsgCycleTime" INT 0 65535;
BA_DEF_DEF_  "GenMsgILSupport" "Yes";
BA_DEF_DEF_  "VFrameFormat" "StandardCAN";
BA_DEF_DEF_  "GenSigSendType" "Cyclic";
BA_DEF_DEF_  "IsMonitor" "*";
BA_DEF_DEF_  "DBName" "";
BA_DEF_DEF_  "BusType" "";
BA_DEF_DEF_  "Manufacturer" "Vector";
BA_DEF_DEF_  "UnitConversionFactor" 1;
BA_DEF_DEF_  "SigInvalidSetFlag" "*";
BA_DEF_DEF_  "Internal_type" "*";
BA_DEF_DEF_  "IsCrcSignal" "No";
BA_DEF_DEF_  "IsRcSignal" "No";
BA_DEF_DEF_  "GenMsgSendType" "Cyclic";
BA_DEF_DEF_  "GenSigStartValue" 0;
BA_DEF_DEF_  "MsgType" "";
BA_DEF_DEF_  "GenMsgCycleTime" 0;
BA_ "BusType" "CAN FD";
BA_ "DBName" "CAN_PR2";
BA_ "GenMsgCycleTime" BO_ 1136 500;
BA_ "MsgType" BO_ 1136 0;
BA_ "GenMsgILSupport" BO_ 1136 0;
BA_ "VFrameFormat" BO_ 1136 14;
BA_ "GenMsgCycleTime" BO_ 302 20;
BA_ "MsgType" BO_ 302 0;
BA_ "GenMsgILSupport" BO_ 302 0;
BA_ "VFrameFormat" BO_ 302 14;
BA_ "GenMsgCycleTime" BO_ 311 20;
BA_ "MsgType" BO_ 311 0;
BA_ "GenMsgILSupport" BO_ 311 0;
BA_ "VFrameFormat" BO_ 311 14;
BA_ "GenMsgCycleTime" BO_ 315 20;
BA_ "MsgType" BO_ 315 0;
BA_ "GenMsgILSupport" BO_ 315 0;
BA_ "VFrameFormat" BO_ 315 14;
BA_ "GenMsgCycleTime" BO_ 411 50;
BA_ "MsgType" BO_ 411 0;
BA_ "GenMsgILSupport" BO_ 411 0;
BA_ "VFrameFormat" BO_ 411 14;
BA_ "GenMsgCycleTime" BO_ 412 50;
BA_ "MsgType" BO_ 412 0;
BA_ "GenMsgILSupport" BO_ 412 0;
BA_ "VFrameFormat" BO_ 412 14;
BA_ "GenMsgCycleTime" BO_ 545 20;
BA_ "MsgType" BO_ 545 0;
BA_ "GenMsgILSupport" BO_ 545 0;
BA_ "VFrameFormat" BO_ 545 14;
BA_ "GenMsgCycleTime" BO_ 581 20;
BA_ "MsgType" BO_ 581 0;
BA_ "GenMsgILSupport" BO_ 581 0;
BA_ "VFrameFormat" BO_ 581 14;
BA_ "GenMsgCycleTime" BO_ 639 50;
BA_ "MsgType" BO_ 639 0;
BA_ "GenMsgILSupport" BO_ 639 0;
BA_ "VFrameFormat" BO_ 639 14;
BA_ "GenMsgCycleTime" BO_ 671 100;
BA_ "MsgType" BO_ 671 0;
BA_ "GenMsgILSupport" BO_ 671 0;
BA_ "VFrameFormat" BO_ 671 14;
BA_ "GenMsgCycleTime" BO_ 719 100;
BA_ "MsgType" BO_ 719 0;
BA_ "VFrameFormat" BO_ 719 14;
BA_ "GenMsgCycleTime" BO_ 849 500;
BA_ "MsgType" BO_ 849 0;
BA_ "GenMsgILSupport" BO_ 849 0;
BA_ "GenMsgSendType" BO_ 849 11;
BA_ "VFrameFormat" BO_ 849 14;
BA_ "GenMsgCycleTime" BO_ 880 1000;
BA_ "MsgType" BO_ 880 0;
BA_ "GenMsgILSupport" BO_ 880 0;
BA_ "VFrameFormat" BO_ 880 14;
BA_ "GenMsgCycleTime" BO_ 901 100;
BA_ "MsgType" BO_ 901 0;
BA_ "GenMsgILSupport" BO_ 901 0;
BA_ "VFrameFormat" BO_ 901 14;
BA_ "GenMsgCycleTime" BO_ 1001 1000;
BA_ "MsgType" BO_ 1001 0;
BA_ "GenMsgILSupport" BO_ 1001 0;
BA_ "VFrameFormat" BO_ 1001 14;
BA_ "GenMsgCycleTime" BO_ 161 10;
BA_ "MsgType" BO_ 161 0;
BA_ "GenMsgILSupport" BO_ 161 0;
BA_ "VFrameFormat" BO_ 161 14;
BA_ "MsgType" BO_ 1073 0;
BA_ "GenMsgSendType" BO_ 1073 1;
BA_ "VFrameFormat" BO_ 1073 14;
BA_ "MsgType" BO_ 1074 0;
BA_ "GenMsgSendType" BO_ 1074 1;
BA_ "VFrameFormat" BO_ 1074 14;
BA_ "MsgType" BO_ 1075 0;
BA_ "GenMsgSendType" BO_ 1075 1;
BA_ "VFrameFormat" BO_ 1075 14;
BA_ "MsgType" BO_ 1076 0;
BA_ "GenMsgSendType" BO_ 1076 1;
BA_ "VFrameFormat" BO_ 1076 14;
BA_ "MsgType" BO_ 1077 0;
BA_ "GenMsgSendType" BO_ 1077 1;
BA_ "VFrameFormat" BO_ 1077 14;
BA_ "MsgType" BO_ 1078 0;
BA_ "GenMsgSendType" BO_ 1078 1;
BA_ "VFrameFormat" BO_ 1078 14;
BA_ "MsgType" BO_ 1079 0;
BA_ "GenMsgSendType" BO_ 1079 1;
BA_ "VFrameFormat" BO_ 1079 14;
BA_ "MsgType" BO_ 1080 0;
BA_ "GenMsgSendType" BO_ 1080 1;
BA_ "VFrameFormat" BO_ 1080 14;
BA_ "MsgType" BO_ 1081 0;
BA_ "GenMsgSendType" BO_ 1081 1;
BA_ "VFrameFormat" BO_ 1081 14;
BA_ "MsgType" BO_ 1082 0;
BA_ "GenMsgSendType" BO_ 1082 1;
BA_ "VFrameFormat" BO_ 1082 14;
BA_ "MsgType" BO_ 1083 0;
BA_ "GenMsgSendType" BO_ 1083 1;
BA_ "VFrameFormat" BO_ 1083 14;
BA_ "IsRcSignal" SG_ 302 RollingCounter_IBC_FD1_1 1;
BA_ "IsCrcSignal" SG_ 302 Checksum_IBC_FD1_1 1;
BA_ "IsRcSignal" SG_ 311 RollingCounter_ABS3 1;
BA_ "GenSigStartValue" SG_ 311 ABSFailSts 1;
BA_ "IsCrcSignal" SG_ 311 Checksum_ABS3 1;
BA_ "IsRcSignal" SG_ 311 RollingCounter_ESP1 1;
BA_ "IsCrcSignal" SG_ 311 Checksum_ESP1 1;
BA_ "IsRcSignal" SG_ 311 RollingCounter_ESP2 1;
BA_ "IsCrcSignal" SG_ 311 Checksum_ESP2 1;
BA_ "IsRcSignal" SG_ 315 RollingCounter_ABS2 1;
BA_ "IsCrcSignal" SG_ 315 Checksum_ABS2 1;
BA_ "IsRcSignal" SG_ 315 RollingCounter_ABS1 1;
BA_ "IsCrcSignal" SG_ 315 Checksum_ABS1 1;
BA_ "GenSigStartValue" SG_ 545 TGS_LEVER 14;
BA_ "IsRcSignal" SG_ 581 RollingCounter_ABM2 1;
BA_ "GenSigStartValue" SG_ 581 VehYawRate 8721;
BA_ "GenSigStartValue" SG_ 581 VehLatAccel 22033;
BA_ "GenSigStartValue" SG_ 581 VehLgtAccel 22033;
BA_ "IsCrcSignal" SG_ 581 Checksum_ABM2 1;
BA_ "IsRcSignal" SG_ 849 RollingCounter_ABM1 1;
BA_ "GenSigStartValue" SG_ 849 DrvSBR 1;
BA_ "IsCrcSignal" SG_ 849 Checksum_ABM1 1;
BA_ "GenSigStartValue" SG_ 880 Time_Year_Right 15;
BA_ "GenSigStartValue" SG_ 880 Time_Year_Left 15;
BA_ "GenSigStartValue" SG_ 880 Time_Second 63;
BA_ "GenSigStartValue" SG_ 880 Time_Minutes 63;
BA_ "GenSigStartValue" SG_ 880 Time_Hour 31;
BA_ "GenSigStartValue" SG_ 901 ACAmbTemp 254;
BA_ "IsRcSignal" SG_ 161 RollingCounter_CSA2 1;
BA_ "IsCrcSignal" SG_ 161 Checksum_CSA2 1;
BA_ "IsRcSignal" SG_ 1073 RollingCounter16 1;
BA_ "GenSigSendType" SG_ 1073 RollingCounter16 9;
BA_ "GenSigSendType" SG_ 1073 MRR_ObjMeasured_3 9;
BA_ "GenSigStartValue" SG_ 1073 MRR_ObjMeasured_3 1;
BA_ "GenSigSendType" SG_ 1073 MRR_ObjMeasured_4 9;
BA_ "GenSigStartValue" SG_ 1073 MRR_ObjMeasured_4 1;
BA_ "GenSigSendType" SG_ 1073 MRR_ObjHeading_4 9;
BA_ "GenSigSendType" SG_ 1073 MRR_ObjAge_4 9;
BA_ "GenSigSendType" SG_ 1073 MRR_ObjRCS_4 9;
BA_ "GenSigStartValue" SG_ 1073 MRR_ObjRCS_4 400;
BA_ "GenSigSendType" SG_ 1073 BlockCounter2 9;
BA_ "GenSigSendType" SG_ 1073 VFC_ObjHeight_4 9;
BA_ "IsCrcSignal" SG_ 1073 Checksum16 1;
BA_ "GenSigSendType" SG_ 1073 Checksum16 9;
BA_ "IsRcSignal" SG_ 1073 RollingCounter15 1;
BA_ "GenSigSendType" SG_ 1073 RollingCounter15 9;
BA_ "GenSigSendType" SG_ 1073 VFC_ObjMotionDirection_4 9;
BA_ "GenSigSendType" SG_ 1073 VFC_ObjLength_4 9;
BA_ "GenSigSendType" SG_ 1073 VFC_ObjWidth_4 9;
BA_ "GenSigSendType" SG_ 1073 MRR_ObjMotionType_4 9;
BA_ "GenSigSendType" SG_ 1073 MRR_ObjRAccelYStd_4 9;
BA_ "GenSigSendType" SG_ 1073 MRR_ObjRAccelXStd_4 9;
BA_ "GenSigSendType" SG_ 1073 MRR_ObjRelVelYStd_4 9;
BA_ "GenSigSendType" SG_ 1073 MRR_ObjRelVelXStd_4 9;
BA_ "IsCrcSignal" SG_ 1073 Checksum15 1;
BA_ "GenSigSendType" SG_ 1073 Checksum15 9;
BA_ "IsRcSignal" SG_ 1073 RollingCounter14 1;
BA_ "GenSigSendType" SG_ 1073 RollingCounter14 9;
BA_ "GenSigSendType" SG_ 1073 MRR_ObjType_4 9;
BA_ "GenSigSendType" SG_ 1073 MRR_ObjDistYStd_4 9;
BA_ "GenSigSendType" SG_ 1073 MRR_ObjDistXStd_4 9;
BA_ "GenSigSendType" SG_ 1073 MRR_ObjRelAccelY_4 9;
BA_ "GenSigStartValue" SG_ 1073 MRR_ObjRelAccelY_4 512;
BA_ "GenSigSendType" SG_ 1073 MRR_ObjRelVelY_4 9;
BA_ "GenSigStartValue" SG_ 1073 MRR_ObjRelVelY_4 4102;
BA_ "GenSigSendType" SG_ 1073 MRR_ObjRelVelX_4 9;
BA_ "GenSigStartValue" SG_ 1073 MRR_ObjRelVelX_4 4102;
BA_ "IsCrcSignal" SG_ 1073 Checksum14 1;
BA_ "GenSigSendType" SG_ 1073 Checksum14 9;
BA_ "IsRcSignal" SG_ 1073 RollingCounter13 1;
BA_ "GenSigSendType" SG_ 1073 RollingCounter13 9;
BA_ "GenSigSendType" SG_ 1073 MRR_ObjRelAccelX_4 9;
BA_ "GenSigStartValue" SG_ 1073 MRR_ObjRelAccelX_4 512;
BA_ "GenSigSendType" SG_ 1073 MRR_ObjDistY_4 9;
BA_ "GenSigStartValue" SG_ 1073 MRR_ObjDistY_4 1024;
BA_ "GenSigSendType" SG_ 1073 MRR_ObjDistX_4 9;
BA_ "GenSigSendType" SG_ 1073 MRR_ObjObstacleProb_4 9;
BA_ "GenSigSendType" SG_ 1073 MRR_ObjExistProb_4 9;
BA_ "GenSigSendType" SG_ 1073 MRR_ObjID_4 9;
BA_ "IsCrcSignal" SG_ 1073 Checksum13 1;
BA_ "GenSigSendType" SG_ 1073 Checksum13 9;
BA_ "IsRcSignal" SG_ 1073 RollingCounter12 1;
BA_ "GenSigSendType" SG_ 1073 RollingCounter12 9;
BA_ "GenSigSendType" SG_ 1073 MRR_ObjRefPoint_3 9;
BA_ "GenSigSendType" SG_ 1073 MRR_ObjRefPoint_4 9;
BA_ "GenSigSendType" SG_ 1073 MRR_ObjAge_3 9;
BA_ "GenSigSendType" SG_ 1073 MRR_ObjRCS_3 9;
BA_ "GenSigStartValue" SG_ 1073 MRR_ObjRCS_3 400;
BA_ "GenSigSendType" SG_ 1073 MRR_ObjHeading_3 9;
BA_ "GenSigSendType" SG_ 1073 VFC_ObjHeight_3 9;
BA_ "IsCrcSignal" SG_ 1073 Checksum12 1;
BA_ "GenSigSendType" SG_ 1073 Checksum12 9;
BA_ "IsRcSignal" SG_ 1073 RollingCounter11 1;
BA_ "GenSigSendType" SG_ 1073 RollingCounter11 9;
BA_ "GenSigSendType" SG_ 1073 VFC_ObjMotionDirection_3 9;
BA_ "GenSigSendType" SG_ 1073 VFC_ObjLength_3 9;
BA_ "GenSigSendType" SG_ 1073 VFC_ObjWidth_3 9;
BA_ "GenSigSendType" SG_ 1073 MRR_ObjMotionType_3 9;
BA_ "GenSigSendType" SG_ 1073 MRR_ObjRAccelYStd_3 9;
BA_ "GenSigSendType" SG_ 1073 MRR_ObjRAccelXStd_3 9;
BA_ "GenSigSendType" SG_ 1073 MRR_ObjRelVelYStd_3 9;
BA_ "GenSigSendType" SG_ 1073 MRR_ObjRelVelXStd_3 9;
BA_ "IsCrcSignal" SG_ 1073 Checksum11 1;
BA_ "GenSigSendType" SG_ 1073 Checksum11 9;
BA_ "IsRcSignal" SG_ 1073 RollingCounter10 1;
BA_ "GenSigSendType" SG_ 1073 RollingCounter10 9;
BA_ "GenSigSendType" SG_ 1073 MRR_ObjType_3 9;
BA_ "GenSigSendType" SG_ 1073 MRR_ObjDistYStd_3 9;
BA_ "GenSigSendType" SG_ 1073 MRR_ObjDistXStd_3 9;
BA_ "GenSigSendType" SG_ 1073 MRR_ObjRelAccelY_3 9;
BA_ "GenSigStartValue" SG_ 1073 MRR_ObjRelAccelY_3 512;
BA_ "GenSigSendType" SG_ 1073 MRR_ObjRelVelY_3 9;
BA_ "GenSigStartValue" SG_ 1073 MRR_ObjRelVelY_3 4102;
BA_ "GenSigSendType" SG_ 1073 MRR_ObjRelVelX_3 9;
BA_ "GenSigStartValue" SG_ 1073 MRR_ObjRelVelX_3 4102;
BA_ "IsCrcSignal" SG_ 1073 Checksum10 1;
BA_ "GenSigSendType" SG_ 1073 Checksum10 9;
BA_ "IsRcSignal" SG_ 1073 RollingCounter9 1;
BA_ "GenSigSendType" SG_ 1073 RollingCounter9 9;
BA_ "GenSigSendType" SG_ 1073 MRR_ObjRelAccelX_3 9;
BA_ "GenSigStartValue" SG_ 1073 MRR_ObjRelAccelX_3 512;
BA_ "GenSigSendType" SG_ 1073 MRR_ObjDistY_3 9;
BA_ "GenSigStartValue" SG_ 1073 MRR_ObjDistY_3 1024;
BA_ "GenSigSendType" SG_ 1073 MRR_ObjDistX_3 9;
BA_ "GenSigSendType" SG_ 1073 MRR_ObjObstacleProb_3 9;
BA_ "GenSigSendType" SG_ 1073 MRR_ObjExistProb_3 9;
BA_ "GenSigSendType" SG_ 1073 MRR_ObjID_3 9;
BA_ "IsCrcSignal" SG_ 1073 Checksum9 1;
BA_ "GenSigSendType" SG_ 1073 Checksum9 9;
BA_ "IsRcSignal" SG_ 1074 RollingCounter24 1;
BA_ "GenSigSendType" SG_ 1074 RollingCounter24 9;
BA_ "GenSigSendType" SG_ 1074 MRR_ObjMeasured_5 9;
BA_ "GenSigStartValue" SG_ 1074 MRR_ObjMeasured_5 1;
BA_ "GenSigSendType" SG_ 1074 MRR_ObjMeasured_6 9;
BA_ "GenSigStartValue" SG_ 1074 MRR_ObjMeasured_6 1;
BA_ "GenSigSendType" SG_ 1074 MRR_ObjHeading_6 9;
BA_ "GenSigSendType" SG_ 1074 MRR_ObjAge_6 9;
BA_ "GenSigSendType" SG_ 1074 MRR_ObjRCS_6 9;
BA_ "GenSigStartValue" SG_ 1074 MRR_ObjRCS_6 400;
BA_ "GenSigSendType" SG_ 1074 BlockCounter3 9;
BA_ "GenSigSendType" SG_ 1074 VFC_ObjHeight_6 9;
BA_ "IsCrcSignal" SG_ 1074 Checksum24 1;
BA_ "GenSigSendType" SG_ 1074 Checksum24 9;
BA_ "IsRcSignal" SG_ 1074 RollingCounter23 1;
BA_ "GenSigSendType" SG_ 1074 RollingCounter23 9;
BA_ "GenSigSendType" SG_ 1074 VFC_ObjMotionDirection_6 9;
BA_ "GenSigSendType" SG_ 1074 VFC_ObjLength_6 9;
BA_ "GenSigSendType" SG_ 1074 VFC_ObjWidth_6 9;
BA_ "GenSigSendType" SG_ 1074 MRR_ObjMotionType_6 9;
BA_ "GenSigSendType" SG_ 1074 MRR_ObjRAccelYStd_6 9;
BA_ "GenSigSendType" SG_ 1074 MRR_ObjRAccelXStd_6 9;
BA_ "GenSigSendType" SG_ 1074 MRR_ObjRelVelYStd_6 9;
BA_ "GenSigSendType" SG_ 1074 MRR_ObjRelVelXStd_6 9;
BA_ "IsCrcSignal" SG_ 1074 Checksum23 1;
BA_ "GenSigSendType" SG_ 1074 Checksum23 9;
BA_ "IsRcSignal" SG_ 1074 RollingCounter22 1;
BA_ "GenSigSendType" SG_ 1074 RollingCounter22 9;
BA_ "GenSigSendType" SG_ 1074 MRR_ObjType_6 9;
BA_ "GenSigSendType" SG_ 1074 MRR_ObjDistYStd_6 9;
BA_ "GenSigSendType" SG_ 1074 MRR_ObjDistXStd_6 9;
BA_ "GenSigSendType" SG_ 1074 MRR_ObjRelAccelY_6 9;
BA_ "GenSigStartValue" SG_ 1074 MRR_ObjRelAccelY_6 512;
BA_ "GenSigSendType" SG_ 1074 MRR_ObjRelVelY_6 9;
BA_ "GenSigStartValue" SG_ 1074 MRR_ObjRelVelY_6 4102;
BA_ "GenSigSendType" SG_ 1074 MRR_ObjRelVelX_6 9;
BA_ "GenSigStartValue" SG_ 1074 MRR_ObjRelVelX_6 4102;
BA_ "IsCrcSignal" SG_ 1074 Checksum22 1;
BA_ "GenSigSendType" SG_ 1074 Checksum22 9;
BA_ "IsRcSignal" SG_ 1074 RollingCounter21 1;
BA_ "GenSigSendType" SG_ 1074 RollingCounter21 9;
BA_ "GenSigSendType" SG_ 1074 MRR_ObjRelAccelX_6 9;
BA_ "GenSigStartValue" SG_ 1074 MRR_ObjRelAccelX_6 512;
BA_ "GenSigSendType" SG_ 1074 MRR_ObjDistY_6 9;
BA_ "GenSigStartValue" SG_ 1074 MRR_ObjDistY_6 1024;
BA_ "GenSigSendType" SG_ 1074 MRR_ObjDistX_6 9;
BA_ "GenSigSendType" SG_ 1074 MRR_ObjObstacleProb_6 9;
BA_ "GenSigSendType" SG_ 1074 MRR_ObjExistProb_6 9;
BA_ "GenSigSendType" SG_ 1074 MRR_ObjID_6 9;
BA_ "IsCrcSignal" SG_ 1074 Checksum21 1;
BA_ "GenSigSendType" SG_ 1074 Checksum21 9;
BA_ "IsRcSignal" SG_ 1074 RollingCounter20 1;
BA_ "GenSigSendType" SG_ 1074 RollingCounter20 9;
BA_ "GenSigSendType" SG_ 1074 MRR_ObjRefPoint_5 9;
BA_ "GenSigSendType" SG_ 1074 MRR_ObjRefPoint_6 9;
BA_ "GenSigSendType" SG_ 1074 MRR_ObjAge_5 9;
BA_ "GenSigSendType" SG_ 1074 MRR_ObjRCS_5 9;
BA_ "GenSigStartValue" SG_ 1074 MRR_ObjRCS_5 400;
BA_ "GenSigSendType" SG_ 1074 MRR_ObjHeading_5 9;
BA_ "GenSigSendType" SG_ 1074 VFC_ObjHeight_5 9;
BA_ "IsCrcSignal" SG_ 1074 Checksum20 1;
BA_ "GenSigSendType" SG_ 1074 Checksum20 9;
BA_ "IsRcSignal" SG_ 1074 RollingCounter19 1;
BA_ "GenSigSendType" SG_ 1074 RollingCounter19 9;
BA_ "GenSigSendType" SG_ 1074 VFC_ObjMotionDirection_5 9;
BA_ "GenSigSendType" SG_ 1074 VFC_ObjLength_5 9;
BA_ "GenSigSendType" SG_ 1074 VFC_ObjWidth_5 9;
BA_ "GenSigSendType" SG_ 1074 MRR_ObjMotionType_5 9;
BA_ "GenSigSendType" SG_ 1074 MRR_ObjRAccelYStd_5 9;
BA_ "GenSigSendType" SG_ 1074 MRR_ObjRAccelXStd_5 9;
BA_ "GenSigSendType" SG_ 1074 MRR_ObjRelVelYStd_5 9;
BA_ "GenSigSendType" SG_ 1074 MRR_ObjRelVelXStd_5 9;
BA_ "IsCrcSignal" SG_ 1074 Checksum19 1;
BA_ "GenSigSendType" SG_ 1074 Checksum19 9;
BA_ "IsRcSignal" SG_ 1074 RollingCounter18 1;
BA_ "GenSigSendType" SG_ 1074 RollingCounter18 9;
BA_ "GenSigSendType" SG_ 1074 MRR_ObjType_5 9;
BA_ "GenSigSendType" SG_ 1074 MRR_ObjDistYStd_5 9;
BA_ "GenSigSendType" SG_ 1074 MRR_ObjDistXStd_5 9;
BA_ "GenSigSendType" SG_ 1074 MRR_ObjRelAccelY_5 9;
BA_ "GenSigStartValue" SG_ 1074 MRR_ObjRelAccelY_5 512;
BA_ "GenSigSendType" SG_ 1074 MRR_ObjRelVelY_5 9;
BA_ "GenSigStartValue" SG_ 1074 MRR_ObjRelVelY_5 4102;
BA_ "GenSigSendType" SG_ 1074 MRR_ObjRelVelX_5 9;
BA_ "GenSigStartValue" SG_ 1074 MRR_ObjRelVelX_5 4102;
BA_ "IsCrcSignal" SG_ 1074 Checksum18 1;
BA_ "GenSigSendType" SG_ 1074 Checksum18 9;
BA_ "IsRcSignal" SG_ 1074 RollingCounter17 1;
BA_ "GenSigSendType" SG_ 1074 RollingCounter17 9;
BA_ "GenSigSendType" SG_ 1074 MRR_ObjRelAccelX_5 9;
BA_ "GenSigStartValue" SG_ 1074 MRR_ObjRelAccelX_5 512;
BA_ "GenSigSendType" SG_ 1074 MRR_ObjDistY_5 9;
BA_ "GenSigStartValue" SG_ 1074 MRR_ObjDistY_5 1024;
BA_ "GenSigSendType" SG_ 1074 MRR_ObjDistX_5 9;
BA_ "GenSigSendType" SG_ 1074 MRR_ObjObstacleProb_5 9;
BA_ "GenSigSendType" SG_ 1074 MRR_ObjExistProb_5 9;
BA_ "GenSigSendType" SG_ 1074 MRR_ObjID_5 9;
BA_ "IsCrcSignal" SG_ 1074 Checksum17 1;
BA_ "GenSigSendType" SG_ 1074 Checksum17 9;
BA_ "IsRcSignal" SG_ 1075 RollingCounter32 1;
BA_ "GenSigSendType" SG_ 1075 RollingCounter32 9;
BA_ "GenSigSendType" SG_ 1075 MRR_ObjMeasured_7 9;
BA_ "GenSigStartValue" SG_ 1075 MRR_ObjMeasured_7 1;
BA_ "GenSigSendType" SG_ 1075 MRR_ObjMeasured_8 9;
BA_ "GenSigStartValue" SG_ 1075 MRR_ObjMeasured_8 1;
BA_ "GenSigSendType" SG_ 1075 MRR_ObjHeading_8 9;
BA_ "GenSigSendType" SG_ 1075 MRR_ObjAge_8 9;
BA_ "GenSigSendType" SG_ 1075 MRR_ObjRCS_8 9;
BA_ "GenSigStartValue" SG_ 1075 MRR_ObjRCS_8 400;
BA_ "GenSigSendType" SG_ 1075 BlockCounter4 9;
BA_ "GenSigSendType" SG_ 1075 VFC_ObjHeight_8 9;
BA_ "IsCrcSignal" SG_ 1075 Checksum32 1;
BA_ "GenSigSendType" SG_ 1075 Checksum32 9;
BA_ "IsRcSignal" SG_ 1075 RollingCounter31 1;
BA_ "GenSigSendType" SG_ 1075 RollingCounter31 9;
BA_ "GenSigSendType" SG_ 1075 VFC_ObjMotionDirection_8 9;
BA_ "GenSigSendType" SG_ 1075 VFC_ObjLength_8 9;
BA_ "GenSigSendType" SG_ 1075 VFC_ObjWidth_8 9;
BA_ "GenSigSendType" SG_ 1075 MRR_ObjMotionType_8 9;
BA_ "GenSigSendType" SG_ 1075 MRR_ObjRAccelYStd_8 9;
BA_ "GenSigSendType" SG_ 1075 MRR_ObjRAccelXStd_8 9;
BA_ "GenSigSendType" SG_ 1075 MRR_ObjRelVelYStd_8 9;
BA_ "GenSigSendType" SG_ 1075 MRR_ObjRelVelXStd_8 9;
BA_ "IsCrcSignal" SG_ 1075 Checksum31 1;
BA_ "GenSigSendType" SG_ 1075 Checksum31 9;
BA_ "IsRcSignal" SG_ 1075 RollingCounter30 1;
BA_ "GenSigSendType" SG_ 1075 RollingCounter30 9;
BA_ "GenSigSendType" SG_ 1075 MRR_ObjType_8 9;
BA_ "GenSigSendType" SG_ 1075 MRR_ObjDistYStd_8 9;
BA_ "GenSigSendType" SG_ 1075 MRR_ObjDistXStd_8 9;
BA_ "GenSigSendType" SG_ 1075 MRR_ObjRelAccelY_8 9;
BA_ "GenSigStartValue" SG_ 1075 MRR_ObjRelAccelY_8 512;
BA_ "GenSigSendType" SG_ 1075 MRR_ObjRelVelY_8 9;
BA_ "GenSigStartValue" SG_ 1075 MRR_ObjRelVelY_8 4102;
BA_ "GenSigSendType" SG_ 1075 MRR_ObjRelVelX_8 9;
BA_ "GenSigStartValue" SG_ 1075 MRR_ObjRelVelX_8 4102;
BA_ "IsCrcSignal" SG_ 1075 Checksum30 1;
BA_ "GenSigSendType" SG_ 1075 Checksum30 9;
BA_ "IsRcSignal" SG_ 1075 RollingCounter29 1;
BA_ "GenSigSendType" SG_ 1075 RollingCounter29 9;
BA_ "GenSigSendType" SG_ 1075 MRR_ObjRelAccelX_8 9;
BA_ "GenSigStartValue" SG_ 1075 MRR_ObjRelAccelX_8 512;
BA_ "GenSigSendType" SG_ 1075 MRR_ObjDistY_8 9;
BA_ "GenSigStartValue" SG_ 1075 MRR_ObjDistY_8 1024;
BA_ "GenSigSendType" SG_ 1075 MRR_ObjDistX_8 9;
BA_ "GenSigSendType" SG_ 1075 MRR_ObjObstacleProb_8 9;
BA_ "GenSigSendType" SG_ 1075 MRR_ObjExistProb_8 9;
BA_ "GenSigSendType" SG_ 1075 MRR_ObjID_8 9;
BA_ "IsCrcSignal" SG_ 1075 Checksum29 1;
BA_ "GenSigSendType" SG_ 1075 Checksum29 9;
BA_ "IsRcSignal" SG_ 1075 RollingCounter28 1;
BA_ "GenSigSendType" SG_ 1075 RollingCounter28 9;
BA_ "GenSigSendType" SG_ 1075 MRR_ObjRefPoint_7 9;
BA_ "GenSigSendType" SG_ 1075 MRR_ObjRefPoint_8 9;
BA_ "GenSigSendType" SG_ 1075 MRR_ObjAge_7 9;
BA_ "GenSigSendType" SG_ 1075 MRR_ObjRCS_7 9;
BA_ "GenSigStartValue" SG_ 1075 MRR_ObjRCS_7 400;
BA_ "GenSigSendType" SG_ 1075 MRR_ObjHeading_7 9;
BA_ "GenSigSendType" SG_ 1075 VFC_ObjHeight_7 9;
BA_ "IsCrcSignal" SG_ 1075 Checksum28 1;
BA_ "GenSigSendType" SG_ 1075 Checksum28 9;
BA_ "IsRcSignal" SG_ 1075 RollingCounter27 1;
BA_ "GenSigSendType" SG_ 1075 RollingCounter27 9;
BA_ "GenSigSendType" SG_ 1075 VFC_ObjMotionDirection_7 9;
BA_ "GenSigSendType" SG_ 1075 VFC_ObjLength_7 9;
BA_ "GenSigSendType" SG_ 1075 VFC_ObjWidth_7 9;
BA_ "GenSigSendType" SG_ 1075 MRR_ObjMotionType_7 9;
BA_ "GenSigSendType" SG_ 1075 MRR_ObjRAccelYStd_7 9;
BA_ "GenSigSendType" SG_ 1075 MRR_ObjRAccelXStd_7 9;
BA_ "GenSigSendType" SG_ 1075 MRR_ObjRelVelYStd_7 9;
BA_ "GenSigSendType" SG_ 1075 MRR_ObjRelVelXStd_7 9;
BA_ "IsCrcSignal" SG_ 1075 Checksum27 1;
BA_ "GenSigSendType" SG_ 1075 Checksum27 9;
BA_ "IsRcSignal" SG_ 1075 RollingCounter26 1;
BA_ "GenSigSendType" SG_ 1075 RollingCounter26 9;
BA_ "GenSigSendType" SG_ 1075 MRR_ObjType_7 9;
BA_ "GenSigSendType" SG_ 1075 MRR_ObjDistYStd_7 9;
BA_ "GenSigSendType" SG_ 1075 MRR_ObjDistXStd_7 9;
BA_ "GenSigSendType" SG_ 1075 MRR_ObjRelAccelY_7 9;
BA_ "GenSigStartValue" SG_ 1075 MRR_ObjRelAccelY_7 512;
BA_ "GenSigSendType" SG_ 1075 MRR_ObjRelVelY_7 9;
BA_ "GenSigStartValue" SG_ 1075 MRR_ObjRelVelY_7 4102;
BA_ "GenSigSendType" SG_ 1075 MRR_ObjRelVelX_7 9;
BA_ "GenSigStartValue" SG_ 1075 MRR_ObjRelVelX_7 4102;
BA_ "IsCrcSignal" SG_ 1075 Checksum26 1;
BA_ "GenSigSendType" SG_ 1075 Checksum26 9;
BA_ "IsRcSignal" SG_ 1075 RollingCounter25 1;
BA_ "GenSigSendType" SG_ 1075 RollingCounter25 9;
BA_ "GenSigSendType" SG_ 1075 MRR_ObjRelAccelX_7 9;
BA_ "GenSigStartValue" SG_ 1075 MRR_ObjRelAccelX_7 512;
BA_ "GenSigSendType" SG_ 1075 MRR_ObjDistY_7 9;
BA_ "GenSigStartValue" SG_ 1075 MRR_ObjDistY_7 1024;
BA_ "GenSigSendType" SG_ 1075 MRR_ObjDistX_7 9;
BA_ "GenSigSendType" SG_ 1075 MRR_ObjObstacleProb_7 9;
BA_ "GenSigSendType" SG_ 1075 MRR_ObjExistProb_7 9;
BA_ "GenSigSendType" SG_ 1075 MRR_ObjID_7 9;
BA_ "IsCrcSignal" SG_ 1075 Checksum25 1;
BA_ "GenSigSendType" SG_ 1075 Checksum25 9;
BA_ "IsRcSignal" SG_ 1076 RollingCounter40 1;
BA_ "GenSigSendType" SG_ 1076 RollingCounter40 9;
BA_ "GenSigSendType" SG_ 1076 MRR_ObjMeasured_9 9;
BA_ "GenSigStartValue" SG_ 1076 MRR_ObjMeasured_9 1;
BA_ "GenSigSendType" SG_ 1076 MRR_ObjMeasured_10 9;
BA_ "GenSigStartValue" SG_ 1076 MRR_ObjMeasured_10 1;
BA_ "GenSigSendType" SG_ 1076 MRR_ObjHeading_10 9;
BA_ "GenSigSendType" SG_ 1076 MRR_ObjAge_10 9;
BA_ "GenSigSendType" SG_ 1076 MRR_ObjRCS_10 9;
BA_ "GenSigStartValue" SG_ 1076 MRR_ObjRCS_10 400;
BA_ "GenSigSendType" SG_ 1076 BlockCounter5 9;
BA_ "GenSigSendType" SG_ 1076 VFC_ObjHeight_10 9;
BA_ "IsCrcSignal" SG_ 1076 Checksum40 1;
BA_ "GenSigSendType" SG_ 1076 Checksum40 9;
BA_ "IsRcSignal" SG_ 1076 RollingCounter39 1;
BA_ "GenSigSendType" SG_ 1076 RollingCounter39 9;
BA_ "GenSigSendType" SG_ 1076 VFC_ObjMotionDirection_10 9;
BA_ "GenSigSendType" SG_ 1076 VFC_ObjLength_10 9;
BA_ "GenSigSendType" SG_ 1076 VFC_ObjWidth_10 9;
BA_ "GenSigSendType" SG_ 1076 MRR_ObjMotionType_10 9;
BA_ "GenSigSendType" SG_ 1076 MRR_ObjRAccelYStd_10 9;
BA_ "GenSigSendType" SG_ 1076 MRR_ObjRAccelXStd_10 9;
BA_ "GenSigSendType" SG_ 1076 MRR_ObjRelVelYStd_10 9;
BA_ "GenSigSendType" SG_ 1076 MRR_ObjRelVelXStd_10 9;
BA_ "IsCrcSignal" SG_ 1076 Checksum39 1;
BA_ "GenSigSendType" SG_ 1076 Checksum39 9;
BA_ "IsRcSignal" SG_ 1076 RollingCounter38 1;
BA_ "GenSigSendType" SG_ 1076 RollingCounter38 9;
BA_ "GenSigSendType" SG_ 1076 MRR_ObjType_10 9;
BA_ "GenSigSendType" SG_ 1076 MRR_ObjDistYStd_10 9;
BA_ "GenSigSendType" SG_ 1076 MRR_ObjDistXStd_10 9;
BA_ "GenSigSendType" SG_ 1076 MRR_ObjRelAccelY_10 9;
BA_ "GenSigStartValue" SG_ 1076 MRR_ObjRelAccelY_10 512;
BA_ "GenSigSendType" SG_ 1076 MRR_ObjRelVelY_10 9;
BA_ "GenSigStartValue" SG_ 1076 MRR_ObjRelVelY_10 4102;
BA_ "GenSigSendType" SG_ 1076 MRR_ObjRelVelX_10 9;
BA_ "GenSigStartValue" SG_ 1076 MRR_ObjRelVelX_10 4102;
BA_ "IsCrcSignal" SG_ 1076 Checksum38 1;
BA_ "GenSigSendType" SG_ 1076 Checksum38 9;
BA_ "IsRcSignal" SG_ 1076 RollingCounter37 1;
BA_ "GenSigSendType" SG_ 1076 RollingCounter37 9;
BA_ "GenSigSendType" SG_ 1076 MRR_ObjRelAccelX_10 9;
BA_ "GenSigStartValue" SG_ 1076 MRR_ObjRelAccelX_10 512;
BA_ "GenSigSendType" SG_ 1076 MRR_ObjDistY_10 9;
BA_ "GenSigStartValue" SG_ 1076 MRR_ObjDistY_10 1024;
BA_ "GenSigSendType" SG_ 1076 MRR_ObjDistX_10 9;
BA_ "GenSigSendType" SG_ 1076 MRR_ObjObstacleProb_10 9;
BA_ "GenSigSendType" SG_ 1076 MRR_ObjExistProb_10 9;
BA_ "GenSigSendType" SG_ 1076 MRR_ObjID_10 9;
BA_ "IsCrcSignal" SG_ 1076 Checksum37 1;
BA_ "GenSigSendType" SG_ 1076 Checksum37 9;
BA_ "IsRcSignal" SG_ 1076 RollingCounter36 1;
BA_ "GenSigSendType" SG_ 1076 RollingCounter36 9;
BA_ "GenSigSendType" SG_ 1076 MRR_ObjRefPoint_9 9;
BA_ "GenSigSendType" SG_ 1076 MRR_ObjRefPoint_10 9;
BA_ "GenSigSendType" SG_ 1076 MRR_ObjAge_9 9;
BA_ "GenSigSendType" SG_ 1076 MRR_ObjRCS_9 9;
BA_ "GenSigStartValue" SG_ 1076 MRR_ObjRCS_9 400;
BA_ "GenSigSendType" SG_ 1076 MRR_ObjHeading_9 9;
BA_ "GenSigSendType" SG_ 1076 VFC_ObjHeight_9 9;
BA_ "IsCrcSignal" SG_ 1076 Checksum36 1;
BA_ "GenSigSendType" SG_ 1076 Checksum36 9;
BA_ "IsRcSignal" SG_ 1076 RollingCounter35 1;
BA_ "GenSigSendType" SG_ 1076 RollingCounter35 9;
BA_ "GenSigSendType" SG_ 1076 VFC_ObjMotionDirection_9 9;
BA_ "GenSigSendType" SG_ 1076 VFC_ObjLength_9 9;
BA_ "GenSigSendType" SG_ 1076 VFC_ObjWidth_9 9;
BA_ "GenSigSendType" SG_ 1076 MRR_ObjMotionType_9 9;
BA_ "GenSigSendType" SG_ 1076 MRR_ObjRAccelYStd_9 9;
BA_ "GenSigSendType" SG_ 1076 MRR_ObjRAccelXStd_9 9;
BA_ "GenSigSendType" SG_ 1076 MRR_ObjRelVelYStd_9 9;
BA_ "GenSigSendType" SG_ 1076 MRR_ObjRelVelXStd_9 9;
BA_ "IsCrcSignal" SG_ 1076 Checksum35 1;
BA_ "GenSigSendType" SG_ 1076 Checksum35 9;
BA_ "IsRcSignal" SG_ 1076 RollingCounter34 1;
BA_ "GenSigSendType" SG_ 1076 RollingCounter34 9;
BA_ "GenSigSendType" SG_ 1076 MRR_ObjType_9 9;
BA_ "GenSigSendType" SG_ 1076 MRR_ObjDistYStd_9 9;
BA_ "GenSigSendType" SG_ 1076 MRR_ObjDistXStd_9 9;
BA_ "GenSigSendType" SG_ 1076 MRR_ObjRelAccelY_9 9;
BA_ "GenSigStartValue" SG_ 1076 MRR_ObjRelAccelY_9 512;
BA_ "GenSigSendType" SG_ 1076 MRR_ObjRelVelY_9 9;
BA_ "GenSigStartValue" SG_ 1076 MRR_ObjRelVelY_9 4102;
BA_ "GenSigSendType" SG_ 1076 MRR_ObjRelVelX_9 9;
BA_ "GenSigStartValue" SG_ 1076 MRR_ObjRelVelX_9 4102;
BA_ "IsCrcSignal" SG_ 1076 Checksum34 1;
BA_ "GenSigSendType" SG_ 1076 Checksum34 9;
BA_ "IsRcSignal" SG_ 1076 RollingCounter33 1;
BA_ "GenSigSendType" SG_ 1076 RollingCounter33 9;
BA_ "GenSigSendType" SG_ 1076 MRR_ObjRelAccelX_9 9;
BA_ "GenSigStartValue" SG_ 1076 MRR_ObjRelAccelX_9 512;
BA_ "GenSigSendType" SG_ 1076 MRR_ObjDistY_9 9;
BA_ "GenSigStartValue" SG_ 1076 MRR_ObjDistY_9 1024;
BA_ "GenSigSendType" SG_ 1076 MRR_ObjDistX_9 9;
BA_ "GenSigSendType" SG_ 1076 MRR_ObjObstacleProb_9 9;
BA_ "GenSigSendType" SG_ 1076 MRR_ObjExistProb_9 9;
BA_ "GenSigSendType" SG_ 1076 MRR_ObjID_9 9;
BA_ "IsCrcSignal" SG_ 1076 Checksum33 1;
BA_ "GenSigSendType" SG_ 1076 Checksum33 9;
BA_ "IsRcSignal" SG_ 1077 RollingCounter48 1;
BA_ "GenSigSendType" SG_ 1077 RollingCounter48 9;
BA_ "GenSigSendType" SG_ 1077 MRR_ObjMeasured_11 9;
BA_ "GenSigStartValue" SG_ 1077 MRR_ObjMeasured_11 1;
BA_ "GenSigSendType" SG_ 1077 MRR_ObjMeasured_12 9;
BA_ "GenSigStartValue" SG_ 1077 MRR_ObjMeasured_12 1;
BA_ "GenSigSendType" SG_ 1077 MRR_ObjHeading_12 9;
BA_ "GenSigSendType" SG_ 1077 MRR_ObjAge_12 9;
BA_ "GenSigSendType" SG_ 1077 MRR_ObjRCS_12 9;
BA_ "GenSigStartValue" SG_ 1077 MRR_ObjRCS_12 400;
BA_ "GenSigSendType" SG_ 1077 BlockCounter6 9;
BA_ "GenSigSendType" SG_ 1077 VFC_ObjHeight_12 9;
BA_ "IsCrcSignal" SG_ 1077 Checksum48 1;
BA_ "GenSigSendType" SG_ 1077 Checksum48 9;
BA_ "IsRcSignal" SG_ 1077 RollingCounter47 1;
BA_ "GenSigSendType" SG_ 1077 RollingCounter47 9;
BA_ "GenSigSendType" SG_ 1077 VFC_ObjMotionDirection_12 9;
BA_ "GenSigSendType" SG_ 1077 VFC_ObjLength_12 9;
BA_ "GenSigSendType" SG_ 1077 VFC_ObjWidth_12 9;
BA_ "GenSigSendType" SG_ 1077 MRR_ObjMotionType_12 9;
BA_ "GenSigSendType" SG_ 1077 MRR_ObjRAccelYStd_12 9;
BA_ "GenSigSendType" SG_ 1077 MRR_ObjRAccelXStd_12 9;
BA_ "GenSigSendType" SG_ 1077 MRR_ObjRelVelYStd_12 9;
BA_ "GenSigSendType" SG_ 1077 MRR_ObjRelVelXStd_12 9;
BA_ "IsCrcSignal" SG_ 1077 Checksum47 1;
BA_ "GenSigSendType" SG_ 1077 Checksum47 9;
BA_ "IsRcSignal" SG_ 1077 RollingCounter46 1;
BA_ "GenSigSendType" SG_ 1077 RollingCounter46 9;
BA_ "GenSigSendType" SG_ 1077 MRR_ObjType_12 9;
BA_ "GenSigSendType" SG_ 1077 MRR_ObjDistYStd_12 9;
BA_ "GenSigSendType" SG_ 1077 MRR_ObjDistXStd_12 9;
BA_ "GenSigSendType" SG_ 1077 MRR_ObjRelAccelY_12 9;
BA_ "GenSigStartValue" SG_ 1077 MRR_ObjRelAccelY_12 512;
BA_ "GenSigSendType" SG_ 1077 MRR_ObjRelVelY_12 9;
BA_ "GenSigStartValue" SG_ 1077 MRR_ObjRelVelY_12 4102;
BA_ "GenSigSendType" SG_ 1077 MRR_ObjRelVelX_12 9;
BA_ "GenSigStartValue" SG_ 1077 MRR_ObjRelVelX_12 4102;
BA_ "IsCrcSignal" SG_ 1077 Checksum46 1;
BA_ "GenSigSendType" SG_ 1077 Checksum46 9;
BA_ "IsRcSignal" SG_ 1077 RollingCounter45 1;
BA_ "GenSigSendType" SG_ 1077 RollingCounter45 9;
BA_ "GenSigSendType" SG_ 1077 MRR_ObjRelAccelX_12 9;
BA_ "GenSigStartValue" SG_ 1077 MRR_ObjRelAccelX_12 512;
BA_ "GenSigSendType" SG_ 1077 MRR_ObjDistY_12 9;
BA_ "GenSigStartValue" SG_ 1077 MRR_ObjDistY_12 1024;
BA_ "GenSigSendType" SG_ 1077 MRR_ObjDistX_12 9;
BA_ "GenSigSendType" SG_ 1077 MRR_ObjObstacleProb_12 9;
BA_ "GenSigSendType" SG_ 1077 MRR_ObjExistProb_12 9;
BA_ "GenSigSendType" SG_ 1077 MRR_ObjID_12 9;
BA_ "IsCrcSignal" SG_ 1077 Checksum45 1;
BA_ "GenSigSendType" SG_ 1077 Checksum45 9;
BA_ "IsRcSignal" SG_ 1077 RollingCounter44 1;
BA_ "GenSigSendType" SG_ 1077 RollingCounter44 9;
BA_ "GenSigSendType" SG_ 1077 MRR_ObjRefPoint_11 9;
BA_ "GenSigSendType" SG_ 1077 MRR_ObjRefPoint_12 9;
BA_ "GenSigSendType" SG_ 1077 MRR_ObjAge_11 9;
BA_ "GenSigSendType" SG_ 1077 MRR_ObjRCS_11 9;
BA_ "GenSigStartValue" SG_ 1077 MRR_ObjRCS_11 400;
BA_ "GenSigSendType" SG_ 1077 MRR_ObjHeading_11 9;
BA_ "GenSigSendType" SG_ 1077 VFC_ObjHeight_11 9;
BA_ "IsCrcSignal" SG_ 1077 Checksum44 1;
BA_ "GenSigSendType" SG_ 1077 Checksum44 9;
BA_ "IsRcSignal" SG_ 1077 RollingCounter43 1;
BA_ "GenSigSendType" SG_ 1077 RollingCounter43 9;
BA_ "GenSigSendType" SG_ 1077 VFC_ObjMotionDirection_11 9;
BA_ "GenSigSendType" SG_ 1077 VFC_ObjLength_11 9;
BA_ "GenSigSendType" SG_ 1077 VFC_ObjWidth_11 9;
BA_ "GenSigSendType" SG_ 1077 MRR_ObjMotionType_11 9;
BA_ "GenSigSendType" SG_ 1077 MRR_ObjRAccelYStd_11 9;
BA_ "GenSigSendType" SG_ 1077 MRR_ObjRAccelXStd_11 9;
BA_ "GenSigSendType" SG_ 1077 MRR_ObjRelVelYStd_11 9;
BA_ "GenSigSendType" SG_ 1077 MRR_ObjRelVelXStd_11 9;
BA_ "IsCrcSignal" SG_ 1077 Checksum43 1;
BA_ "GenSigSendType" SG_ 1077 Checksum43 9;
BA_ "IsRcSignal" SG_ 1077 RollingCounter42 1;
BA_ "GenSigSendType" SG_ 1077 RollingCounter42 9;
BA_ "GenSigSendType" SG_ 1077 MRR_ObjType_11 9;
BA_ "GenSigSendType" SG_ 1077 MRR_ObjDistYStd_11 9;
BA_ "GenSigSendType" SG_ 1077 MRR_ObjDistXStd_11 9;
BA_ "GenSigSendType" SG_ 1077 MRR_ObjRelAccelY_11 9;
BA_ "GenSigStartValue" SG_ 1077 MRR_ObjRelAccelY_11 512;
BA_ "GenSigSendType" SG_ 1077 MRR_ObjRelVelY_11 9;
BA_ "GenSigStartValue" SG_ 1077 MRR_ObjRelVelY_11 4102;
BA_ "GenSigSendType" SG_ 1077 MRR_ObjRelVelX_11 9;
BA_ "GenSigStartValue" SG_ 1077 MRR_ObjRelVelX_11 4102;
BA_ "IsCrcSignal" SG_ 1077 Checksum42 1;
BA_ "GenSigSendType" SG_ 1077 Checksum42 9;
BA_ "IsRcSignal" SG_ 1077 RollingCounter41 1;
BA_ "GenSigSendType" SG_ 1077 RollingCounter41 9;
BA_ "GenSigSendType" SG_ 1077 MRR_ObjRelAccelX_11 9;
BA_ "GenSigStartValue" SG_ 1077 MRR_ObjRelAccelX_11 512;
BA_ "GenSigSendType" SG_ 1077 MRR_ObjDistY_11 9;
BA_ "GenSigStartValue" SG_ 1077 MRR_ObjDistY_11 1024;
BA_ "GenSigSendType" SG_ 1077 MRR_ObjDistX_11 9;
BA_ "GenSigSendType" SG_ 1077 MRR_ObjObstacleProb_11 9;
BA_ "GenSigSendType" SG_ 1077 MRR_ObjExistProb_11 9;
BA_ "GenSigSendType" SG_ 1077 MRR_ObjID_11 9;
BA_ "IsCrcSignal" SG_ 1077 Checksum41 1;
BA_ "GenSigSendType" SG_ 1077 Checksum41 9;
BA_ "IsRcSignal" SG_ 1078 RollingCounter56 1;
BA_ "GenSigSendType" SG_ 1078 RollingCounter56 9;
BA_ "GenSigSendType" SG_ 1078 MRR_ObjMeasured_13 9;
BA_ "GenSigStartValue" SG_ 1078 MRR_ObjMeasured_13 1;
BA_ "GenSigSendType" SG_ 1078 MRR_ObjMeasured_14 9;
BA_ "GenSigStartValue" SG_ 1078 MRR_ObjMeasured_14 1;
BA_ "GenSigSendType" SG_ 1078 MRR_ObjHeading_14 9;
BA_ "GenSigSendType" SG_ 1078 MRR_ObjAge_14 9;
BA_ "GenSigSendType" SG_ 1078 MRR_ObjRCS_14 9;
BA_ "GenSigStartValue" SG_ 1078 MRR_ObjRCS_14 400;
BA_ "GenSigSendType" SG_ 1078 BlockCounter7 9;
BA_ "GenSigSendType" SG_ 1078 VFC_ObjHeight_14 9;
BA_ "IsCrcSignal" SG_ 1078 Checksum56 1;
BA_ "GenSigSendType" SG_ 1078 Checksum56 9;
BA_ "IsRcSignal" SG_ 1078 RollingCounter55 1;
BA_ "GenSigSendType" SG_ 1078 RollingCounter55 9;
BA_ "GenSigSendType" SG_ 1078 VFC_ObjMotionDirection_14 9;
BA_ "GenSigSendType" SG_ 1078 VFC_ObjLength_14 9;
BA_ "GenSigSendType" SG_ 1078 VFC_ObjWidth_14 9;
BA_ "GenSigSendType" SG_ 1078 MRR_ObjMotionType_14 9;
BA_ "GenSigSendType" SG_ 1078 MRR_ObjRAccelYStd_14 9;
BA_ "GenSigSendType" SG_ 1078 MRR_ObjRAccelXStd_14 9;
BA_ "GenSigSendType" SG_ 1078 MRR_ObjRelVelYStd_14 9;
BA_ "GenSigSendType" SG_ 1078 MRR_ObjRelVelXStd_14 9;
BA_ "IsCrcSignal" SG_ 1078 Checksum55 1;
BA_ "GenSigSendType" SG_ 1078 Checksum55 9;
BA_ "IsRcSignal" SG_ 1078 RollingCounter54 1;
BA_ "GenSigSendType" SG_ 1078 RollingCounter54 9;
BA_ "GenSigSendType" SG_ 1078 MRR_ObjType_14 9;
BA_ "GenSigSendType" SG_ 1078 MRR_ObjDistYStd_14 9;
BA_ "GenSigSendType" SG_ 1078 MRR_ObjDistXStd_14 9;
BA_ "GenSigSendType" SG_ 1078 MRR_ObjRelAccelY_14 9;
BA_ "GenSigStartValue" SG_ 1078 MRR_ObjRelAccelY_14 512;
BA_ "GenSigSendType" SG_ 1078 MRR_ObjRelVelY_14 9;
BA_ "GenSigStartValue" SG_ 1078 MRR_ObjRelVelY_14 4102;
BA_ "GenSigSendType" SG_ 1078 MRR_ObjRelVelX_14 9;
BA_ "GenSigStartValue" SG_ 1078 MRR_ObjRelVelX_14 4102;
BA_ "IsCrcSignal" SG_ 1078 Checksum54 1;
BA_ "GenSigSendType" SG_ 1078 Checksum54 9;
BA_ "IsRcSignal" SG_ 1078 RollingCounter53 1;
BA_ "GenSigSendType" SG_ 1078 RollingCounter53 9;
BA_ "GenSigSendType" SG_ 1078 MRR_ObjRelAccelX_14 9;
BA_ "GenSigStartValue" SG_ 1078 MRR_ObjRelAccelX_14 512;
BA_ "GenSigSendType" SG_ 1078 MRR_ObjDistY_14 9;
BA_ "GenSigStartValue" SG_ 1078 MRR_ObjDistY_14 1024;
BA_ "GenSigSendType" SG_ 1078 MRR_ObjDistX_14 9;
BA_ "GenSigSendType" SG_ 1078 MRR_ObjObstacleProb_14 9;
BA_ "GenSigSendType" SG_ 1078 MRR_ObjExistProb_14 9;
BA_ "GenSigSendType" SG_ 1078 MRR_ObjID_14 9;
BA_ "IsCrcSignal" SG_ 1078 Checksum53 1;
BA_ "GenSigSendType" SG_ 1078 Checksum53 9;
BA_ "IsRcSignal" SG_ 1078 RollingCounter52 1;
BA_ "GenSigSendType" SG_ 1078 RollingCounter52 9;
BA_ "GenSigSendType" SG_ 1078 MRR_ObjRefPoint_13 9;
BA_ "GenSigSendType" SG_ 1078 MRR_ObjRefPoint_14 9;
BA_ "GenSigSendType" SG_ 1078 MRR_ObjAge_13 9;
BA_ "GenSigSendType" SG_ 1078 MRR_ObjRCS_13 9;
BA_ "GenSigStartValue" SG_ 1078 MRR_ObjRCS_13 400;
BA_ "GenSigSendType" SG_ 1078 MRR_ObjHeading_13 9;
BA_ "GenSigSendType" SG_ 1078 VFC_ObjHeight_13 9;
BA_ "IsCrcSignal" SG_ 1078 Checksum52 1;
BA_ "GenSigSendType" SG_ 1078 Checksum52 9;
BA_ "IsRcSignal" SG_ 1078 RollingCounter51 1;
BA_ "GenSigSendType" SG_ 1078 RollingCounter51 9;
BA_ "GenSigSendType" SG_ 1078 VFC_ObjMotionDirection_13 9;
BA_ "GenSigSendType" SG_ 1078 VFC_ObjLength_13 9;
BA_ "GenSigSendType" SG_ 1078 VFC_ObjWidth_13 9;
BA_ "GenSigSendType" SG_ 1078 MRR_ObjMotionType_13 9;
BA_ "GenSigSendType" SG_ 1078 MRR_ObjRAccelYStd_13 9;
BA_ "GenSigSendType" SG_ 1078 MRR_ObjRAccelXStd_13 9;
BA_ "GenSigSendType" SG_ 1078 MRR_ObjRelVelYStd_13 9;
BA_ "GenSigSendType" SG_ 1078 MRR_ObjRelVelXStd_13 9;
BA_ "IsCrcSignal" SG_ 1078 Checksum51 1;
BA_ "GenSigSendType" SG_ 1078 Checksum51 9;
BA_ "IsRcSignal" SG_ 1078 RollingCounter50 1;
BA_ "GenSigSendType" SG_ 1078 RollingCounter50 9;
BA_ "GenSigSendType" SG_ 1078 MRR_ObjType_13 9;
BA_ "GenSigSendType" SG_ 1078 MRR_ObjDistYStd_13 9;
BA_ "GenSigSendType" SG_ 1078 MRR_ObjDistXStd_13 9;
BA_ "GenSigSendType" SG_ 1078 MRR_ObjRelAccelY_13 9;
BA_ "GenSigStartValue" SG_ 1078 MRR_ObjRelAccelY_13 512;
BA_ "GenSigSendType" SG_ 1078 MRR_ObjRelVelY_13 9;
BA_ "GenSigStartValue" SG_ 1078 MRR_ObjRelVelY_13 4102;
BA_ "GenSigSendType" SG_ 1078 MRR_ObjRelVelX_13 9;
BA_ "GenSigStartValue" SG_ 1078 MRR_ObjRelVelX_13 4102;
BA_ "IsCrcSignal" SG_ 1078 Checksum50 1;
BA_ "GenSigSendType" SG_ 1078 Checksum50 9;
BA_ "IsRcSignal" SG_ 1078 RollingCounter49 1;
BA_ "GenSigSendType" SG_ 1078 RollingCounter49 9;
BA_ "GenSigSendType" SG_ 1078 MRR_ObjRelAccelX_13 9;
BA_ "GenSigStartValue" SG_ 1078 MRR_ObjRelAccelX_13 512;
BA_ "GenSigSendType" SG_ 1078 MRR_ObjDistY_13 9;
BA_ "GenSigStartValue" SG_ 1078 MRR_ObjDistY_13 1024;
BA_ "GenSigSendType" SG_ 1078 MRR_ObjDistX_13 9;
BA_ "GenSigSendType" SG_ 1078 MRR_ObjObstacleProb_13 9;
BA_ "GenSigSendType" SG_ 1078 MRR_ObjExistProb_13 9;
BA_ "GenSigSendType" SG_ 1078 MRR_ObjID_13 9;
BA_ "IsCrcSignal" SG_ 1078 Checksum49 1;
BA_ "GenSigSendType" SG_ 1078 Checksum49 9;
BA_ "IsRcSignal" SG_ 1079 RollingCounter64 1;
BA_ "GenSigSendType" SG_ 1079 RollingCounter64 9;
BA_ "GenSigSendType" SG_ 1079 MRR_ObjMeasured_15 9;
BA_ "GenSigStartValue" SG_ 1079 MRR_ObjMeasured_15 1;
BA_ "GenSigSendType" SG_ 1079 MRR_ObjMeasured_16 9;
BA_ "GenSigStartValue" SG_ 1079 MRR_ObjMeasured_16 1;
BA_ "GenSigSendType" SG_ 1079 MRR_ObjHeading_16 9;
BA_ "GenSigSendType" SG_ 1079 MRR_ObjAge_16 9;
BA_ "GenSigSendType" SG_ 1079 MRR_ObjRCS_16 9;
BA_ "GenSigStartValue" SG_ 1079 MRR_ObjRCS_16 400;
BA_ "GenSigSendType" SG_ 1079 BlockCounter8 9;
BA_ "GenSigSendType" SG_ 1079 VFC_ObjHeight_16 9;
BA_ "IsCrcSignal" SG_ 1079 Checksum64 1;
BA_ "GenSigSendType" SG_ 1079 Checksum64 9;
BA_ "IsRcSignal" SG_ 1079 RollingCounter63 1;
BA_ "GenSigSendType" SG_ 1079 RollingCounter63 9;
BA_ "GenSigSendType" SG_ 1079 VFC_ObjMotionDirection_16 9;
BA_ "GenSigSendType" SG_ 1079 VFC_ObjLength_16 9;
BA_ "GenSigSendType" SG_ 1079 VFC_ObjWidth_16 9;
BA_ "GenSigSendType" SG_ 1079 MRR_ObjMotionType_16 9;
BA_ "GenSigSendType" SG_ 1079 MRR_ObjRAccelYStd_16 9;
BA_ "GenSigSendType" SG_ 1079 MRR_ObjRAccelXStd_16 9;
BA_ "GenSigSendType" SG_ 1079 MRR_ObjRelVelYStd_16 9;
BA_ "GenSigSendType" SG_ 1079 MRR_ObjRelVelXStd_16 9;
BA_ "IsCrcSignal" SG_ 1079 Checksum63 1;
BA_ "GenSigSendType" SG_ 1079 Checksum63 9;
BA_ "IsRcSignal" SG_ 1079 RollingCounter62 1;
BA_ "GenSigSendType" SG_ 1079 RollingCounter62 9;
BA_ "GenSigSendType" SG_ 1079 MRR_ObjType_16 9;
BA_ "GenSigSendType" SG_ 1079 MRR_ObjDistYStd_16 9;
BA_ "GenSigSendType" SG_ 1079 MRR_ObjDistXStd_16 9;
BA_ "GenSigSendType" SG_ 1079 MRR_ObjRelAccelY_16 9;
BA_ "GenSigStartValue" SG_ 1079 MRR_ObjRelAccelY_16 512;
BA_ "GenSigSendType" SG_ 1079 MRR_ObjRelVelY_16 9;
BA_ "GenSigStartValue" SG_ 1079 MRR_ObjRelVelY_16 4102;
BA_ "GenSigSendType" SG_ 1079 MRR_ObjRelVelX_16 9;
BA_ "GenSigStartValue" SG_ 1079 MRR_ObjRelVelX_16 4102;
BA_ "IsCrcSignal" SG_ 1079 Checksum62 1;
BA_ "GenSigSendType" SG_ 1079 Checksum62 9;
BA_ "IsRcSignal" SG_ 1079 RollingCounter61 1;
BA_ "GenSigSendType" SG_ 1079 RollingCounter61 9;
BA_ "GenSigSendType" SG_ 1079 MRR_ObjRelAccelX_16 9;
BA_ "GenSigStartValue" SG_ 1079 MRR_ObjRelAccelX_16 512;
BA_ "GenSigSendType" SG_ 1079 MRR_ObjDistY_16 9;
BA_ "GenSigStartValue" SG_ 1079 MRR_ObjDistY_16 1024;
BA_ "GenSigSendType" SG_ 1079 MRR_ObjDistX_16 9;
BA_ "GenSigSendType" SG_ 1079 MRR_ObjObstacleProb_16 9;
BA_ "GenSigSendType" SG_ 1079 MRR_ObjExistProb_16 9;
BA_ "GenSigSendType" SG_ 1079 MRR_ObjID_16 9;
BA_ "IsCrcSignal" SG_ 1079 Checksum61 1;
BA_ "GenSigSendType" SG_ 1079 Checksum61 9;
BA_ "IsRcSignal" SG_ 1079 RollingCounter60 1;
BA_ "GenSigSendType" SG_ 1079 RollingCounter60 9;
BA_ "GenSigSendType" SG_ 1079 MRR_ObjRefPoint_15 9;
BA_ "GenSigSendType" SG_ 1079 MRR_ObjRefPoint_16 9;
BA_ "GenSigSendType" SG_ 1079 MRR_ObjAge_15 9;
BA_ "GenSigSendType" SG_ 1079 MRR_ObjRCS_15 9;
BA_ "GenSigStartValue" SG_ 1079 MRR_ObjRCS_15 400;
BA_ "GenSigSendType" SG_ 1079 MRR_ObjHeading_15 9;
BA_ "GenSigSendType" SG_ 1079 VFC_ObjHeight_15 9;
BA_ "IsCrcSignal" SG_ 1079 Checksum60 1;
BA_ "GenSigSendType" SG_ 1079 Checksum60 9;
BA_ "IsRcSignal" SG_ 1079 RollingCounter59 1;
BA_ "GenSigSendType" SG_ 1079 RollingCounter59 9;
BA_ "GenSigSendType" SG_ 1079 VFC_ObjMotionDirection_15 9;
BA_ "GenSigSendType" SG_ 1079 VFC_ObjLength_15 9;
BA_ "GenSigSendType" SG_ 1079 VFC_ObjWidth_15 9;
BA_ "GenSigSendType" SG_ 1079 MRR_ObjMotionType_15 9;
BA_ "GenSigSendType" SG_ 1079 MRR_ObjRAccelYStd_15 9;
BA_ "GenSigSendType" SG_ 1079 MRR_ObjRAccelXStd_15 9;
BA_ "GenSigSendType" SG_ 1079 MRR_ObjRelVelYStd_15 9;
BA_ "GenSigSendType" SG_ 1079 MRR_ObjRelVelXStd_15 9;
BA_ "IsCrcSignal" SG_ 1079 Checksum59 1;
BA_ "GenSigSendType" SG_ 1079 Checksum59 9;
BA_ "IsRcSignal" SG_ 1079 RollingCounter58 1;
BA_ "GenSigSendType" SG_ 1079 RollingCounter58 9;
BA_ "GenSigSendType" SG_ 1079 MRR_ObjType_15 9;
BA_ "GenSigSendType" SG_ 1079 MRR_ObjDistYStd_15 9;
BA_ "GenSigSendType" SG_ 1079 MRR_ObjDistXStd_15 9;
BA_ "GenSigSendType" SG_ 1079 MRR_ObjRelAccelY_15 9;
BA_ "GenSigStartValue" SG_ 1079 MRR_ObjRelAccelY_15 512;
BA_ "GenSigSendType" SG_ 1079 MRR_ObjRelVelY_15 9;
BA_ "GenSigStartValue" SG_ 1079 MRR_ObjRelVelY_15 4102;
BA_ "GenSigSendType" SG_ 1079 MRR_ObjRelVelX_15 9;
BA_ "GenSigStartValue" SG_ 1079 MRR_ObjRelVelX_15 4102;
BA_ "IsCrcSignal" SG_ 1079 Checksum58 1;
BA_ "GenSigSendType" SG_ 1079 Checksum58 9;
BA_ "IsRcSignal" SG_ 1079 RollingCounter57 1;
BA_ "GenSigSendType" SG_ 1079 RollingCounter57 9;
BA_ "GenSigSendType" SG_ 1079 MRR_ObjRelAccelX_15 9;
BA_ "GenSigStartValue" SG_ 1079 MRR_ObjRelAccelX_15 512;
BA_ "GenSigSendType" SG_ 1079 MRR_ObjDistY_15 9;
BA_ "GenSigStartValue" SG_ 1079 MRR_ObjDistY_15 1024;
BA_ "GenSigSendType" SG_ 1079 MRR_ObjDistX_15 9;
BA_ "GenSigSendType" SG_ 1079 MRR_ObjObstacleProb_15 9;
BA_ "GenSigSendType" SG_ 1079 MRR_ObjExistProb_15 9;
BA_ "GenSigSendType" SG_ 1079 MRR_ObjID_15 9;
BA_ "IsCrcSignal" SG_ 1079 Checksum57 1;
BA_ "GenSigSendType" SG_ 1079 Checksum57 9;
BA_ "IsRcSignal" SG_ 1080 RollingCounter72 1;
BA_ "GenSigSendType" SG_ 1080 RollingCounter72 9;
BA_ "GenSigSendType" SG_ 1080 MRR_ObjMeasured_17 9;
BA_ "GenSigStartValue" SG_ 1080 MRR_ObjMeasured_17 1;
BA_ "GenSigSendType" SG_ 1080 MRR_ObjMeasured_18 9;
BA_ "GenSigStartValue" SG_ 1080 MRR_ObjMeasured_18 1;
BA_ "GenSigSendType" SG_ 1080 MRR_ObjHeading_18 9;
BA_ "GenSigSendType" SG_ 1080 MRR_ObjAge_18 9;
BA_ "GenSigSendType" SG_ 1080 MRR_ObjRCS_18 9;
BA_ "GenSigStartValue" SG_ 1080 MRR_ObjRCS_18 400;
BA_ "GenSigSendType" SG_ 1080 BlockCounter9 9;
BA_ "GenSigSendType" SG_ 1080 VFC_ObjHeight_18 9;
BA_ "IsCrcSignal" SG_ 1080 Checksum72 1;
BA_ "GenSigSendType" SG_ 1080 Checksum72 9;
BA_ "IsRcSignal" SG_ 1080 RollingCounter71 1;
BA_ "GenSigSendType" SG_ 1080 RollingCounter71 9;
BA_ "GenSigSendType" SG_ 1080 VFC_ObjMotionDirection_18 9;
BA_ "GenSigSendType" SG_ 1080 VFC_ObjLength_18 9;
BA_ "GenSigSendType" SG_ 1080 VFC_ObjWidth_18 9;
BA_ "GenSigSendType" SG_ 1080 MRR_ObjMotionType_18 9;
BA_ "GenSigSendType" SG_ 1080 MRR_ObjRAccelYStd_18 9;
BA_ "GenSigSendType" SG_ 1080 MRR_ObjRAccelXStd_18 9;
BA_ "GenSigSendType" SG_ 1080 MRR_ObjRelVelYStd_18 9;
BA_ "GenSigSendType" SG_ 1080 MRR_ObjRelVelXStd_18 9;
BA_ "IsCrcSignal" SG_ 1080 Checksum71 1;
BA_ "GenSigSendType" SG_ 1080 Checksum71 9;
BA_ "IsRcSignal" SG_ 1080 RollingCounter70 1;
BA_ "GenSigSendType" SG_ 1080 RollingCounter70 9;
BA_ "GenSigSendType" SG_ 1080 MRR_ObjType_18 9;
BA_ "GenSigSendType" SG_ 1080 MRR_ObjDistYStd_18 9;
BA_ "GenSigSendType" SG_ 1080 MRR_ObjDistXStd_18 9;
BA_ "GenSigSendType" SG_ 1080 MRR_ObjRelAccelY_18 9;
BA_ "GenSigStartValue" SG_ 1080 MRR_ObjRelAccelY_18 512;
BA_ "GenSigSendType" SG_ 1080 MRR_ObjRelVelY_18 9;
BA_ "GenSigStartValue" SG_ 1080 MRR_ObjRelVelY_18 4102;
BA_ "GenSigSendType" SG_ 1080 MRR_ObjRelVelX_18 9;
BA_ "GenSigStartValue" SG_ 1080 MRR_ObjRelVelX_18 4102;
BA_ "IsCrcSignal" SG_ 1080 Checksum70 1;
BA_ "GenSigSendType" SG_ 1080 Checksum70 9;
BA_ "IsRcSignal" SG_ 1080 RollingCounter69 1;
BA_ "GenSigSendType" SG_ 1080 RollingCounter69 9;
BA_ "GenSigSendType" SG_ 1080 MRR_ObjRelAccelX_18 9;
BA_ "GenSigStartValue" SG_ 1080 MRR_ObjRelAccelX_18 512;
BA_ "GenSigSendType" SG_ 1080 MRR_ObjDistY_18 9;
BA_ "GenSigStartValue" SG_ 1080 MRR_ObjDistY_18 1024;
BA_ "GenSigSendType" SG_ 1080 MRR_ObjDistX_18 9;
BA_ "GenSigSendType" SG_ 1080 MRR_ObjObstacleProb_18 9;
BA_ "GenSigSendType" SG_ 1080 MRR_ObjExistProb_18 9;
BA_ "GenSigSendType" SG_ 1080 MRR_ObjID_18 9;
BA_ "IsCrcSignal" SG_ 1080 Checksum69 1;
BA_ "GenSigSendType" SG_ 1080 Checksum69 9;
BA_ "IsRcSignal" SG_ 1080 RollingCounter68 1;
BA_ "GenSigSendType" SG_ 1080 RollingCounter68 9;
BA_ "GenSigSendType" SG_ 1080 MRR_ObjRefPoint_17 9;
BA_ "GenSigSendType" SG_ 1080 MRR_ObjRefPoint_18 9;
BA_ "GenSigSendType" SG_ 1080 MRR_ObjAge_17 9;
BA_ "GenSigSendType" SG_ 1080 MRR_ObjRCS_17 9;
BA_ "GenSigStartValue" SG_ 1080 MRR_ObjRCS_17 400;
BA_ "GenSigSendType" SG_ 1080 MRR_ObjHeading_17 9;
BA_ "GenSigSendType" SG_ 1080 VFC_ObjHeight_17 9;
BA_ "IsCrcSignal" SG_ 1080 Checksum68 1;
BA_ "GenSigSendType" SG_ 1080 Checksum68 9;
BA_ "IsRcSignal" SG_ 1080 RollingCounter67 1;
BA_ "GenSigSendType" SG_ 1080 RollingCounter67 9;
BA_ "GenSigSendType" SG_ 1080 VFC_ObjMotionDirection_17 9;
BA_ "GenSigSendType" SG_ 1080 VFC_ObjLength_17 9;
BA_ "GenSigSendType" SG_ 1080 VFC_ObjWidth_17 9;
BA_ "GenSigSendType" SG_ 1080 MRR_ObjMotionType_17 9;
BA_ "GenSigSendType" SG_ 1080 MRR_ObjRAccelYStd_17 9;
BA_ "GenSigSendType" SG_ 1080 MRR_ObjRAccelXStd_17 9;
BA_ "GenSigSendType" SG_ 1080 MRR_ObjRelVelYStd_17 9;
BA_ "GenSigSendType" SG_ 1080 MRR_ObjRelVelXStd_17 9;
BA_ "IsCrcSignal" SG_ 1080 Checksum67 1;
BA_ "GenSigSendType" SG_ 1080 Checksum67 9;
BA_ "IsRcSignal" SG_ 1080 RollingCounter66 1;
BA_ "GenSigSendType" SG_ 1080 RollingCounter66 9;
BA_ "GenSigSendType" SG_ 1080 MRR_ObjType_17 9;
BA_ "GenSigSendType" SG_ 1080 MRR_ObjDistYStd_17 9;
BA_ "GenSigSendType" SG_ 1080 MRR_ObjDistXStd_17 9;
BA_ "GenSigSendType" SG_ 1080 MRR_ObjRelAccelY_17 9;
BA_ "GenSigStartValue" SG_ 1080 MRR_ObjRelAccelY_17 512;
BA_ "GenSigSendType" SG_ 1080 MRR_ObjRelVelY_17 9;
BA_ "GenSigStartValue" SG_ 1080 MRR_ObjRelVelY_17 4102;
BA_ "GenSigSendType" SG_ 1080 MRR_ObjRelVelX_17 9;
BA_ "GenSigStartValue" SG_ 1080 MRR_ObjRelVelX_17 4102;
BA_ "IsCrcSignal" SG_ 1080 Checksum66 1;
BA_ "GenSigSendType" SG_ 1080 Checksum66 9;
BA_ "IsRcSignal" SG_ 1080 RollingCounter65 1;
BA_ "GenSigSendType" SG_ 1080 RollingCounter65 9;
BA_ "GenSigSendType" SG_ 1080 MRR_ObjRelAccelX_17 9;
BA_ "GenSigStartValue" SG_ 1080 MRR_ObjRelAccelX_17 512;
BA_ "GenSigSendType" SG_ 1080 MRR_ObjDistY_17 9;
BA_ "GenSigStartValue" SG_ 1080 MRR_ObjDistY_17 1024;
BA_ "GenSigSendType" SG_ 1080 MRR_ObjDistX_17 9;
BA_ "GenSigSendType" SG_ 1080 MRR_ObjObstacleProb_17 9;
BA_ "GenSigSendType" SG_ 1080 MRR_ObjExistProb_17 9;
BA_ "GenSigSendType" SG_ 1080 MRR_ObjID_17 9;
BA_ "IsCrcSignal" SG_ 1080 Checksum65 1;
BA_ "GenSigSendType" SG_ 1080 Checksum65 9;
BA_ "IsRcSignal" SG_ 1081 RollingCounter80 1;
BA_ "GenSigSendType" SG_ 1081 RollingCounter80 9;
BA_ "GenSigSendType" SG_ 1081 MRR_ObjMeasured_19 9;
BA_ "GenSigStartValue" SG_ 1081 MRR_ObjMeasured_19 1;
BA_ "GenSigSendType" SG_ 1081 MRR_ObjMeasured_20 9;
BA_ "GenSigStartValue" SG_ 1081 MRR_ObjMeasured_20 1;
BA_ "GenSigSendType" SG_ 1081 MRR_ObjHeading_20 9;
BA_ "GenSigSendType" SG_ 1081 MRR_ObjAge_20 9;
BA_ "GenSigSendType" SG_ 1081 MRR_ObjRCS_20 9;
BA_ "GenSigStartValue" SG_ 1081 MRR_ObjRCS_20 400;
BA_ "GenSigSendType" SG_ 1081 BlockCounter10 9;
BA_ "GenSigSendType" SG_ 1081 VFC_ObjHeight_20 9;
BA_ "IsCrcSignal" SG_ 1081 Checksum80 1;
BA_ "GenSigSendType" SG_ 1081 Checksum80 9;
BA_ "IsRcSignal" SG_ 1081 RollingCounter79 1;
BA_ "GenSigSendType" SG_ 1081 RollingCounter79 9;
BA_ "GenSigSendType" SG_ 1081 VFC_ObjMotionDirection_20 9;
BA_ "GenSigSendType" SG_ 1081 VFC_ObjLength_20 9;
BA_ "GenSigSendType" SG_ 1081 VFC_ObjWidth_20 9;
BA_ "GenSigSendType" SG_ 1081 MRR_ObjMotionType_20 9;
BA_ "GenSigSendType" SG_ 1081 MRR_ObjRAccelYStd_20 9;
BA_ "GenSigSendType" SG_ 1081 MRR_ObjRAccelXStd_20 9;
BA_ "GenSigSendType" SG_ 1081 MRR_ObjRelVelYStd_20 9;
BA_ "GenSigSendType" SG_ 1081 MRR_ObjRelVelXStd_20 9;
BA_ "IsCrcSignal" SG_ 1081 Checksum79 1;
BA_ "GenSigSendType" SG_ 1081 Checksum79 9;
BA_ "IsRcSignal" SG_ 1081 RollingCounter78 1;
BA_ "GenSigSendType" SG_ 1081 RollingCounter78 9;
BA_ "GenSigSendType" SG_ 1081 MRR_ObjType_20 9;
BA_ "GenSigSendType" SG_ 1081 MRR_ObjDistYStd_20 9;
BA_ "GenSigSendType" SG_ 1081 MRR_ObjDistXStd_20 9;
BA_ "GenSigSendType" SG_ 1081 MRR_ObjRelAccelY_20 9;
BA_ "GenSigStartValue" SG_ 1081 MRR_ObjRelAccelY_20 512;
BA_ "GenSigSendType" SG_ 1081 MRR_ObjRelVelY_20 9;
BA_ "GenSigStartValue" SG_ 1081 MRR_ObjRelVelY_20 4102;
BA_ "GenSigSendType" SG_ 1081 MRR_ObjRelVelX_20 9;
BA_ "GenSigStartValue" SG_ 1081 MRR_ObjRelVelX_20 4102;
BA_ "IsCrcSignal" SG_ 1081 Checksum78 1;
BA_ "GenSigSendType" SG_ 1081 Checksum78 9;
BA_ "IsRcSignal" SG_ 1081 RollingCounter77 1;
BA_ "GenSigSendType" SG_ 1081 RollingCounter77 9;
BA_ "GenSigSendType" SG_ 1081 MRR_ObjRelAccelX_20 9;
BA_ "GenSigStartValue" SG_ 1081 MRR_ObjRelAccelX_20 512;
BA_ "GenSigSendType" SG_ 1081 MRR_ObjDistY_20 9;
BA_ "GenSigStartValue" SG_ 1081 MRR_ObjDistY_20 1024;
BA_ "GenSigSendType" SG_ 1081 MRR_ObjDistX_20 9;
BA_ "GenSigSendType" SG_ 1081 MRR_ObjObstacleProb_20 9;
BA_ "GenSigSendType" SG_ 1081 MRR_ObjExistProb_20 9;
BA_ "GenSigSendType" SG_ 1081 MRR_ObjID_20 9;
BA_ "IsCrcSignal" SG_ 1081 Checksum77 1;
BA_ "GenSigSendType" SG_ 1081 Checksum77 9;
BA_ "IsRcSignal" SG_ 1081 RollingCounter76 1;
BA_ "GenSigSendType" SG_ 1081 RollingCounter76 9;
BA_ "GenSigSendType" SG_ 1081 MRR_ObjRefPoint_19 9;
BA_ "GenSigSendType" SG_ 1081 MRR_ObjRefPoint_20 9;
BA_ "GenSigSendType" SG_ 1081 MRR_ObjAge_19 9;
BA_ "GenSigSendType" SG_ 1081 MRR_ObjRCS_19 9;
BA_ "GenSigStartValue" SG_ 1081 MRR_ObjRCS_19 400;
BA_ "GenSigSendType" SG_ 1081 MRR_ObjHeading_19 9;
BA_ "GenSigSendType" SG_ 1081 VFC_ObjHeight_19 9;
BA_ "IsCrcSignal" SG_ 1081 Checksum76 1;
BA_ "GenSigSendType" SG_ 1081 Checksum76 9;
BA_ "IsRcSignal" SG_ 1081 RollingCounter75 1;
BA_ "GenSigSendType" SG_ 1081 RollingCounter75 9;
BA_ "GenSigSendType" SG_ 1081 VFC_ObjMotionDirection_19 9;
BA_ "GenSigSendType" SG_ 1081 VFC_ObjLength_19 9;
BA_ "GenSigSendType" SG_ 1081 VFC_ObjWidth_19 9;
BA_ "GenSigSendType" SG_ 1081 MRR_ObjMotionType_19 9;
BA_ "GenSigSendType" SG_ 1081 MRR_ObjRAccelYStd_19 9;
BA_ "GenSigSendType" SG_ 1081 MRR_ObjRAccelXStd_19 9;
BA_ "GenSigSendType" SG_ 1081 MRR_ObjRelVelYStd_19 9;
BA_ "GenSigSendType" SG_ 1081 MRR_ObjRelVelXStd_19 9;
BA_ "IsCrcSignal" SG_ 1081 Checksum75 1;
BA_ "GenSigSendType" SG_ 1081 Checksum75 9;
BA_ "IsRcSignal" SG_ 1081 RollingCounter74 1;
BA_ "GenSigSendType" SG_ 1081 RollingCounter74 9;
BA_ "GenSigSendType" SG_ 1081 MRR_ObjType_19 9;
BA_ "GenSigSendType" SG_ 1081 MRR_ObjDistYStd_19 9;
BA_ "GenSigSendType" SG_ 1081 MRR_ObjDistXStd_19 9;
BA_ "GenSigSendType" SG_ 1081 MRR_ObjRelAccelY_19 9;
BA_ "GenSigStartValue" SG_ 1081 MRR_ObjRelAccelY_19 512;
BA_ "GenSigSendType" SG_ 1081 MRR_ObjRelVelY_19 9;
BA_ "GenSigStartValue" SG_ 1081 MRR_ObjRelVelY_19 4102;
BA_ "GenSigSendType" SG_ 1081 MRR_ObjRelVelX_19 9;
BA_ "GenSigStartValue" SG_ 1081 MRR_ObjRelVelX_19 4102;
BA_ "IsCrcSignal" SG_ 1081 Checksum74 1;
BA_ "GenSigSendType" SG_ 1081 Checksum74 9;
BA_ "IsRcSignal" SG_ 1081 RollingCounter73 1;
BA_ "GenSigSendType" SG_ 1081 RollingCounter73 9;
BA_ "GenSigSendType" SG_ 1081 MRR_ObjRelAccelX_19 9;
BA_ "GenSigStartValue" SG_ 1081 MRR_ObjRelAccelX_19 512;
BA_ "GenSigSendType" SG_ 1081 MRR_ObjDistY_19 9;
BA_ "GenSigStartValue" SG_ 1081 MRR_ObjDistY_19 1024;
BA_ "GenSigSendType" SG_ 1081 MRR_ObjDistX_19 9;
BA_ "GenSigSendType" SG_ 1081 MRR_ObjObstacleProb_19 9;
BA_ "GenSigSendType" SG_ 1081 MRR_ObjExistProb_19 9;
BA_ "GenSigSendType" SG_ 1081 MRR_ObjID_19 9;
BA_ "IsCrcSignal" SG_ 1081 Checksum73 1;
BA_ "GenSigSendType" SG_ 1081 Checksum73 9;
BA_ "IsRcSignal" SG_ 1082 RollingCounter88 1;
BA_ "GenSigSendType" SG_ 1082 RollingCounter88 9;
BA_ "GenSigSendType" SG_ 1082 MRR_ObjMeasured_21 9;
BA_ "GenSigStartValue" SG_ 1082 MRR_ObjMeasured_21 1;
BA_ "GenSigSendType" SG_ 1082 MRR_ObjMeasured_22 9;
BA_ "GenSigStartValue" SG_ 1082 MRR_ObjMeasured_22 1;
BA_ "GenSigSendType" SG_ 1082 MRR_ObjHeading_22 9;
BA_ "GenSigSendType" SG_ 1082 MRR_ObjAge_22 9;
BA_ "GenSigSendType" SG_ 1082 MRR_ObjRCS_22 9;
BA_ "GenSigStartValue" SG_ 1082 MRR_ObjRCS_22 400;
BA_ "GenSigSendType" SG_ 1082 BlockCounter11 9;
BA_ "GenSigSendType" SG_ 1082 VFC_ObjHeight_22 9;
BA_ "IsCrcSignal" SG_ 1082 Checksum88 1;
BA_ "GenSigSendType" SG_ 1082 Checksum88 9;
BA_ "IsRcSignal" SG_ 1082 RollingCounter87 1;
BA_ "GenSigSendType" SG_ 1082 RollingCounter87 9;
BA_ "GenSigSendType" SG_ 1082 VFC_ObjMotionDirection_22 9;
BA_ "GenSigSendType" SG_ 1082 VFC_ObjLength_22 9;
BA_ "GenSigSendType" SG_ 1082 VFC_ObjWidth_22 9;
BA_ "GenSigSendType" SG_ 1082 MRR_ObjMotionType_22 9;
BA_ "GenSigSendType" SG_ 1082 MRR_ObjRAccelYStd_22 9;
BA_ "GenSigSendType" SG_ 1082 MRR_ObjRAccelXStd_22 9;
BA_ "GenSigSendType" SG_ 1082 MRR_ObjRelVelYStd_22 9;
BA_ "GenSigSendType" SG_ 1082 MRR_ObjRelVelXStd_22 9;
BA_ "IsCrcSignal" SG_ 1082 Checksum87 1;
BA_ "GenSigSendType" SG_ 1082 Checksum87 9;
BA_ "IsRcSignal" SG_ 1082 RollingCounter86 1;
BA_ "GenSigSendType" SG_ 1082 RollingCounter86 9;
BA_ "GenSigSendType" SG_ 1082 MRR_ObjType_22 9;
BA_ "GenSigSendType" SG_ 1082 MRR_ObjDistYStd_22 9;
BA_ "GenSigSendType" SG_ 1082 MRR_ObjDistXStd_22 9;
BA_ "GenSigSendType" SG_ 1082 MRR_ObjRelAccelY_22 9;
BA_ "GenSigStartValue" SG_ 1082 MRR_ObjRelAccelY_22 512;
BA_ "GenSigSendType" SG_ 1082 MRR_ObjRelVelY_22 9;
BA_ "GenSigStartValue" SG_ 1082 MRR_ObjRelVelY_22 4102;
BA_ "GenSigSendType" SG_ 1082 MRR_ObjRelVelX_22 9;
BA_ "GenSigStartValue" SG_ 1082 MRR_ObjRelVelX_22 4102;
BA_ "IsCrcSignal" SG_ 1082 Checksum86 1;
BA_ "GenSigSendType" SG_ 1082 Checksum86 9;
BA_ "IsRcSignal" SG_ 1082 RollingCounter85 1;
BA_ "GenSigSendType" SG_ 1082 RollingCounter85 9;
BA_ "GenSigSendType" SG_ 1082 MRR_ObjRelAccelX_22 9;
BA_ "GenSigStartValue" SG_ 1082 MRR_ObjRelAccelX_22 512;
BA_ "GenSigSendType" SG_ 1082 MRR_ObjDistY_22 9;
BA_ "GenSigStartValue" SG_ 1082 MRR_ObjDistY_22 1024;
BA_ "GenSigSendType" SG_ 1082 MRR_ObjDistX_22 9;
BA_ "GenSigSendType" SG_ 1082 MRR_ObjObstacleProb_22 9;
BA_ "GenSigSendType" SG_ 1082 MRR_ObjExistProb_22 9;
BA_ "GenSigSendType" SG_ 1082 MRR_ObjID_22 9;
BA_ "IsCrcSignal" SG_ 1082 Checksum85 1;
BA_ "GenSigSendType" SG_ 1082 Checksum85 9;
BA_ "IsRcSignal" SG_ 1082 RollingCounter84 1;
BA_ "GenSigSendType" SG_ 1082 RollingCounter84 9;
BA_ "GenSigSendType" SG_ 1082 MRR_ObjRefPoint_21 9;
BA_ "GenSigSendType" SG_ 1082 MRR_ObjRefPoint_22 9;
BA_ "GenSigSendType" SG_ 1082 MRR_ObjAge_21 9;
BA_ "GenSigSendType" SG_ 1082 MRR_ObjRCS_21 9;
BA_ "GenSigStartValue" SG_ 1082 MRR_ObjRCS_21 400;
BA_ "GenSigSendType" SG_ 1082 MRR_ObjHeading_21 9;
BA_ "GenSigSendType" SG_ 1082 VFC_ObjHeight_21 9;
BA_ "IsCrcSignal" SG_ 1082 Checksum84 1;
BA_ "GenSigSendType" SG_ 1082 Checksum84 9;
BA_ "IsRcSignal" SG_ 1082 RollingCounter83 1;
BA_ "GenSigSendType" SG_ 1082 RollingCounter83 9;
BA_ "GenSigSendType" SG_ 1082 VFC_ObjMotionDirection_21 9;
BA_ "GenSigSendType" SG_ 1082 VFC_ObjLength_21 9;
BA_ "GenSigSendType" SG_ 1082 VFC_ObjWidth_21 9;
BA_ "GenSigSendType" SG_ 1082 MRR_ObjMotionType_21 9;
BA_ "GenSigSendType" SG_ 1082 MRR_ObjRAccelYStd_21 9;
BA_ "GenSigSendType" SG_ 1082 MRR_ObjRAccelXStd_21 9;
BA_ "GenSigSendType" SG_ 1082 MRR_ObjRelVelYStd_21 9;
BA_ "GenSigSendType" SG_ 1082 MRR_ObjRelVelXStd_21 9;
BA_ "IsCrcSignal" SG_ 1082 Checksum83 1;
BA_ "GenSigSendType" SG_ 1082 Checksum83 9;
BA_ "IsRcSignal" SG_ 1082 RollingCounter82 1;
BA_ "GenSigSendType" SG_ 1082 RollingCounter82 9;
BA_ "GenSigSendType" SG_ 1082 MRR_ObjType_21 9;
BA_ "GenSigSendType" SG_ 1082 MRR_ObjDistYStd_21 9;
BA_ "GenSigSendType" SG_ 1082 MRR_ObjDistXStd_21 9;
BA_ "GenSigSendType" SG_ 1082 MRR_ObjRelAccelY_21 9;
BA_ "GenSigStartValue" SG_ 1082 MRR_ObjRelAccelY_21 512;
BA_ "GenSigSendType" SG_ 1082 MRR_ObjRelVelY_21 9;
BA_ "GenSigStartValue" SG_ 1082 MRR_ObjRelVelY_21 4102;
BA_ "GenSigSendType" SG_ 1082 MRR_ObjRelVelX_21 9;
BA_ "GenSigStartValue" SG_ 1082 MRR_ObjRelVelX_21 4102;
BA_ "IsCrcSignal" SG_ 1082 Checksum82 1;
BA_ "GenSigSendType" SG_ 1082 Checksum82 9;
BA_ "IsRcSignal" SG_ 1082 RollingCounter81 1;
BA_ "GenSigSendType" SG_ 1082 RollingCounter81 9;
BA_ "GenSigSendType" SG_ 1082 MRR_ObjRelAccelX_21 9;
BA_ "GenSigStartValue" SG_ 1082 MRR_ObjRelAccelX_21 512;
BA_ "GenSigSendType" SG_ 1082 MRR_ObjDistY_21 9;
BA_ "GenSigStartValue" SG_ 1082 MRR_ObjDistY_21 1024;
BA_ "GenSigSendType" SG_ 1082 MRR_ObjDistX_21 9;
BA_ "GenSigSendType" SG_ 1082 MRR_ObjObstacleProb_21 9;
BA_ "GenSigSendType" SG_ 1082 MRR_ObjExistProb_21 9;
BA_ "GenSigSendType" SG_ 1082 MRR_ObjID_21 9;
BA_ "IsCrcSignal" SG_ 1082 Checksum81 1;
BA_ "GenSigSendType" SG_ 1082 Checksum81 9;
BA_ "IsRcSignal" SG_ 1083 RollingCounter96 1;
BA_ "GenSigSendType" SG_ 1083 RollingCounter96 9;
BA_ "GenSigSendType" SG_ 1083 MRR_ObjMeasured_23 9;
BA_ "GenSigStartValue" SG_ 1083 MRR_ObjMeasured_23 1;
BA_ "GenSigSendType" SG_ 1083 MRR_ObjMeasured_24 9;
BA_ "GenSigStartValue" SG_ 1083 MRR_ObjMeasured_24 1;
BA_ "GenSigSendType" SG_ 1083 MRR_ObjHeading_24 9;
BA_ "GenSigSendType" SG_ 1083 MRR_ObjAge_24 9;
BA_ "GenSigSendType" SG_ 1083 MRR_ObjRCS_24 9;
BA_ "GenSigStartValue" SG_ 1083 MRR_ObjRCS_24 400;
BA_ "GenSigSendType" SG_ 1083 BlockCounter12 9;
BA_ "GenSigSendType" SG_ 1083 VFC_ObjHeight_24 9;
BA_ "IsCrcSignal" SG_ 1083 Checksum96 1;
BA_ "GenSigSendType" SG_ 1083 Checksum96 9;
BA_ "IsRcSignal" SG_ 1083 RollingCounter95 1;
BA_ "GenSigSendType" SG_ 1083 RollingCounter95 9;
BA_ "GenSigSendType" SG_ 1083 VFC_ObjMotionDirection_24 9;
BA_ "GenSigSendType" SG_ 1083 VFC_ObjLength_24 9;
BA_ "GenSigSendType" SG_ 1083 VFC_ObjWidth_24 9;
BA_ "GenSigSendType" SG_ 1083 MRR_ObjMotionType_24 9;
BA_ "GenSigSendType" SG_ 1083 MRR_ObjRAccelYStd_24 9;
BA_ "GenSigSendType" SG_ 1083 MRR_ObjRAccelXStd_24 9;
BA_ "GenSigSendType" SG_ 1083 MRR_ObjRelVelYStd_24 9;
BA_ "GenSigSendType" SG_ 1083 MRR_ObjRelVelXStd_24 9;
BA_ "IsCrcSignal" SG_ 1083 Checksum95 1;
BA_ "GenSigSendType" SG_ 1083 Checksum95 9;
BA_ "IsRcSignal" SG_ 1083 RollingCounter94 1;
BA_ "GenSigSendType" SG_ 1083 RollingCounter94 9;
BA_ "GenSigSendType" SG_ 1083 MRR_ObjType_24 9;
BA_ "GenSigSendType" SG_ 1083 MRR_ObjDistYStd_24 9;
BA_ "GenSigSendType" SG_ 1083 MRR_ObjDistXStd_24 9;
BA_ "GenSigSendType" SG_ 1083 MRR_ObjRelAccelY_24 9;
BA_ "GenSigStartValue" SG_ 1083 MRR_ObjRelAccelY_24 512;
BA_ "GenSigSendType" SG_ 1083 MRR_ObjRelVelY_24 9;
BA_ "GenSigStartValue" SG_ 1083 MRR_ObjRelVelY_24 4102;
BA_ "GenSigSendType" SG_ 1083 MRR_ObjRelVelX_24 9;
BA_ "GenSigStartValue" SG_ 1083 MRR_ObjRelVelX_24 4102;
BA_ "IsCrcSignal" SG_ 1083 Checksum94 1;
BA_ "GenSigSendType" SG_ 1083 Checksum94 9;
BA_ "IsRcSignal" SG_ 1083 RollingCounter93 1;
BA_ "GenSigSendType" SG_ 1083 RollingCounter93 9;
BA_ "GenSigSendType" SG_ 1083 MRR_ObjRelAccelX_24 9;
BA_ "GenSigStartValue" SG_ 1083 MRR_ObjRelAccelX_24 512;
BA_ "GenSigSendType" SG_ 1083 MRR_ObjDistY_24 9;
BA_ "GenSigStartValue" SG_ 1083 MRR_ObjDistY_24 1024;
BA_ "GenSigSendType" SG_ 1083 MRR_ObjDistX_24 9;
BA_ "GenSigSendType" SG_ 1083 MRR_ObjObstacleProb_24 9;
BA_ "GenSigSendType" SG_ 1083 MRR_ObjExistProb_24 9;
BA_ "GenSigSendType" SG_ 1083 MRR_ObjID_24 9;
BA_ "IsCrcSignal" SG_ 1083 Checksum93 1;
BA_ "GenSigSendType" SG_ 1083 Checksum93 9;
BA_ "IsRcSignal" SG_ 1083 RollingCounter92 1;
BA_ "GenSigSendType" SG_ 1083 RollingCounter92 9;
BA_ "GenSigSendType" SG_ 1083 MRR_ObjRefPoint_23 9;
BA_ "GenSigSendType" SG_ 1083 MRR_ObjRefPoint_24 9;
BA_ "GenSigSendType" SG_ 1083 MRR_ObjAge_23 9;
BA_ "GenSigSendType" SG_ 1083 MRR_ObjRCS_23 9;
BA_ "GenSigStartValue" SG_ 1083 MRR_ObjRCS_23 400;
BA_ "GenSigSendType" SG_ 1083 MRR_ObjHeading_23 9;
BA_ "GenSigSendType" SG_ 1083 VFC_ObjHeight_23 9;
BA_ "IsCrcSignal" SG_ 1083 Checksum92 1;
BA_ "GenSigSendType" SG_ 1083 Checksum92 9;
BA_ "IsRcSignal" SG_ 1083 RollingCounter91 1;
BA_ "GenSigSendType" SG_ 1083 RollingCounter91 9;
BA_ "GenSigSendType" SG_ 1083 VFC_ObjMotionDirection_23 9;
BA_ "GenSigSendType" SG_ 1083 VFC_ObjLength_23 9;
BA_ "GenSigSendType" SG_ 1083 VFC_ObjWidth_23 9;
BA_ "GenSigSendType" SG_ 1083 MRR_ObjMotionType_23 9;
BA_ "GenSigSendType" SG_ 1083 MRR_ObjRAccelYStd_23 9;
BA_ "GenSigSendType" SG_ 1083 MRR_ObjRAccelXStd_23 9;
BA_ "GenSigSendType" SG_ 1083 MRR_ObjRelVelYStd_23 9;
BA_ "GenSigSendType" SG_ 1083 MRR_ObjRelVelXStd_23 9;
BA_ "IsCrcSignal" SG_ 1083 Checksum91 1;
BA_ "GenSigSendType" SG_ 1083 Checksum91 9;
BA_ "IsRcSignal" SG_ 1083 RollingCounter90 1;
BA_ "GenSigSendType" SG_ 1083 RollingCounter90 9;
BA_ "GenSigSendType" SG_ 1083 MRR_ObjType_23 9;
BA_ "GenSigSendType" SG_ 1083 MRR_ObjDistYStd_23 9;
BA_ "GenSigSendType" SG_ 1083 MRR_ObjDistXStd_23 9;
BA_ "GenSigSendType" SG_ 1083 MRR_ObjRelAccelY_23 9;
BA_ "GenSigStartValue" SG_ 1083 MRR_ObjRelAccelY_23 512;
BA_ "GenSigSendType" SG_ 1083 MRR_ObjRelVelY_23 9;
BA_ "GenSigStartValue" SG_ 1083 MRR_ObjRelVelY_23 4102;
BA_ "GenSigSendType" SG_ 1083 MRR_ObjRelVelX_23 9;
BA_ "GenSigStartValue" SG_ 1083 MRR_ObjRelVelX_23 4102;
BA_ "IsCrcSignal" SG_ 1083 Checksum90 1;
BA_ "GenSigSendType" SG_ 1083 Checksum90 9;
BA_ "IsRcSignal" SG_ 1083 RollingCounter89 1;
BA_ "GenSigSendType" SG_ 1083 RollingCounter89 9;
BA_ "GenSigSendType" SG_ 1083 MRR_ObjRelAccelX_23 9;
BA_ "GenSigStartValue" SG_ 1083 MRR_ObjRelAccelX_23 512;
BA_ "GenSigSendType" SG_ 1083 MRR_ObjDistY_23 9;
BA_ "GenSigStartValue" SG_ 1083 MRR_ObjDistY_23 1024;
BA_ "GenSigSendType" SG_ 1083 MRR_ObjDistX_23 9;
BA_ "GenSigSendType" SG_ 1083 MRR_ObjObstacleProb_23 9;
BA_ "GenSigSendType" SG_ 1083 MRR_ObjExistProb_23 9;
BA_ "GenSigSendType" SG_ 1083 MRR_ObjID_23 9;
BA_ "IsCrcSignal" SG_ 1083 Checksum89 1;
BA_ "GenSigSendType" SG_ 1083 Checksum89 9;
VAL_ 1136 Sync_SyncTime 0 "Valid_value" ;
VAL_ 1136 Sync_OVS 0 "Valid_value" ;
VAL_ 1136 Sync_SGW 0 "Valid_value" ;
VAL_ 1136 Sync_Resd 0 "Valid_value" ;
VAL_ 1136 Sync_Counter 0 "Valid_value" ;
VAL_ 1136 Sync_TimeDomain 0 "Valid_value" ;
VAL_ 1136 Sync_CRC 0 "Valid_value" ;
VAL_ 1136 Sync_Type 0 "Valid_value" ;
VAL_ 302 RollingCounter_IBC_FD1_1 0 "Valid_value" 15 "Invalid_value" ;
VAL_ 302 PushrodStauts 0 "Not_Pressed_Init_Default" 1 "Pressed" 2 "Reserved" 3 "Error" ;
VAL_ 302 InpRodStk 0 "Valid_value" ;
VAL_ 302 InpRodStkSts 0 "Valid_value" 1 "Invalid_value" ;
VAL_ 302 Checksum_IBC_FD1_1 0 "Valid_value" ;
VAL_ 311 RollingCounter_ABS3 0 "Valid_value" 15 "Invalid_value" ;
VAL_ 311 ABSActv 0 "Not_active" 1 "Active" ;
VAL_ 311 VehSpd 0 "Valid_value" 5334 "Reserved" ;
VAL_ 311 ABSFailSts 0 "No_failure" 1 "Failure" ;
VAL_ 311 Checksum_ABS3 0 "Valid_value" ;
VAL_ 311 RollingCounter_ESP1 0 "Valid_value" 15 "Invalid_value" ;
VAL_ 311 VDCActv 0 "Not_active" 1 "Active" ;
VAL_ 311 MSRActv 0 "Not_active" 1 "Active" ;
VAL_ 311 PTCActv 0 "Not_active" 1 "Active" ;
VAL_ 311 BTCActv 0 "Not_active" 1 "Active" ;
VAL_ 311 ESPFuncOffSts 0 "Available_On" 1 "Unavailable_Off" ;
VAL_ 311 ESPFailSts 0 "No_failure" 1 "Failure" ;
VAL_ 311 Checksum_ESP1 0 "Valid_value" ;
VAL_ 311 RollingCounter_ESP2 0 "Valid_value" 15 "Invalid_value" ;
VAL_ 311 ESP_DiagActv 0 "ESP_diagnosis_is_inactive" 1 "ESP_diagnosis_is_active" ;
VAL_ 311 NoBrkForce 0 "Exist_brake_force" 1 "No_brake_force" ;
VAL_ 311 VehStandstill 0 "Not_standstill" 1 "Standstill" 2 "Invalid_short_unavailability,_max_3s" 3 "Reserved" ;
VAL_ 311 Checksum_ESP2 0 "Valid_value" ;
VAL_ 315 RollingCounter_ABS2 0 "Valid_value" 15 "Invalid_value" ;
VAL_ 315 RRWheelSpd 0 "Valid_value" 5334 "Reserved" ;
VAL_ 315 RRWheelSpdVld 0 "Invalid_value" 1 "Valid_value" ;
VAL_ 315 RRWheelDriveDirection 0 "Invalid_value" 1 "Forward" 2 "Backward" 3 "Stop" ;
VAL_ 315 RLWheelSpd 0 "Valid_value" 5334 "Reserved" ;
VAL_ 315 RLWheelSpdVld 0 "Invalid_value" 1 "Valid_value" ;
VAL_ 315 RLWheelDriveDirection 0 "Invalid" 1 "Forward" 2 "Backward" 3 "Stop" ;
VAL_ 315 Checksum_ABS2 0 "Valid_value" ;
VAL_ 315 RollingCounter_ABS1 0 "Valid_value" 15 "Invalid_value" ;
VAL_ 315 FRWheelSpd 0 "Valid_value" 5334 "Reserved" ;
VAL_ 315 FRWheelSpdVld 0 "Invalid_value" 1 "Valid_value" ;
VAL_ 315 FRWheelDriveDirection 0 "Invalid_value" 1 "Forward" 2 "Backward" 3 "Stop" ;
VAL_ 315 FLWheelSpd 0 "Valid_value" 5334 "Reserved" ;
VAL_ 315 FLWheelSpdVld 0 "Invalid_value" 1 "Valid_value" ;
VAL_ 315 FLWheelDriveDirection 0 "Invalid" 1 "Forward" 2 "Backward" 3 "Stop" ;
VAL_ 315 Checksum_ABS1 0 "Valid_value" ;
VAL_ 411 HoodSts_F_PBox 0 "Closed" 1 "Open" ;
VAL_ 412 RTurnLmpSts_R_PBox 0 "Off" 1 "On" ;
VAL_ 412 LTurnLmpSts_R_PBox 0 "Off" 1 "On" ;
VAL_ 545 TGS_LEVER 0 "Select_lever_in_position_P" 1 "Reserved" 2 "Reserved" 3 "Reserved" 4 "Reserved" 5 "Select_lever_in_position_D" 6 "Select_lever_in_position_N" 7 "Select_lever_in_position_R" 8 "Select_lever_in_position_M" 9 "Reserved" 14 "Intermediate_position" 15 "Invalid" ;
VAL_ 581 RollingCounter_ABM2 0 "Valid_value" 15 "Invalid_value" ;
VAL_ 581 VehDynYawRateVld 0 "Invalid" 1 "Valid" ;
VAL_ 581 VehLatAccelVld 0 "Invalid" 1 "Valid" ;
VAL_ 581 VehLgtAccelVld 0 "Invalid" 1 "Valid" ;
VAL_ 581 VehYawRate 0 "Valid_Value" 17442 "Reserved" ;
VAL_ 581 VehLatAccel 0 "Valid_Value" 44067 "Reserved" ;
VAL_ 581 VehLgtAccel 0 "Valid_Value" 44067 "Reserved" ;
VAL_ 581 Checksum_ABM2 0 "Valid_value" ;
VAL_ 639 IP_VehTotDistance 0 "0-9999999-km" 10000000 "Reserved" 16777215 "Invalid" ;
VAL_ 671 WiprReq_F_PBox 0 "WiperOff" 1 "Wiperactiononce" 2 "Speed1(Lo)" 3 "Speed2(Hi)" 4 "Reserved" 7 "Invalid" ;
VAL_ 719 TSRSpdLim 0 "No_Display" 1 "SPL_5" 2 "SPL_10" 3 "SPL_15" 4 "SPL_20" 5 "SPL_25" 6 "SPL_30" 7 "SPL_35" 8 "SPL_40" 9 "SPL_45" 10 "SPL_50" 11 "SPL_55" 12 "SPL_60" 13 "SPL_65" 14 "SPL_70" 15 "SPL_75" 16 "SPL_80" 17 "SPL_85" 18 "SPL_90" 19 "SPL_95" 20 "SPL_100" 21 "SPL_105" 22 "SPL_110" 23 "SPL_115" 24 "SPL_120" 25 "SPL_125" 26 "SPL_130" 27 "SPL_135" 28 "SPL_140" 29 "SPL_145" 30 "SPL_150" 31 "Reserved" 63 "Invalid" ;
VAL_ 719 TSRConSpdLim 0 "No_Display" 1 "SPL_5" 2 "SPL_10" 3 "SPL_15" 4 "SPL_20" 5 "SPL_25" 6 "SPL_30" 7 "SPL_35" 8 "SPL_40" 9 "SPL_45" 10 "SPL_50" 11 "SPL_55" 12 "SPL_60" 13 "SPL_65" 14 "SPL_70" 15 "SPL_75" 16 "SPL_80" 17 "SPL_85" 18 "SPL_90" 19 "SPL_95" 20 "SPL_100" 21 "SPL_105" 22 "SPL_110" 23 "SPL_115" 24 "SPL_120" 25 "SPL_125" 26 "SPL_130" 27 "SPL_135" 28 "SPL_140" 29 "SPL_145" 30 "SPL_150" 31 "Reserved" 63 "Invalid" ;
VAL_ 849 RollingCounter_ABM1 0 "Valid_value" 15 "Invalid_value" ;
VAL_ 849 DrvSBR 0 "No_reminder" 1 "Reminder" ;
VAL_ 849 Checksum_ABM1 0 "Valid_value" ;
VAL_ 880 Time_Day 0 "Invalid" 1 "Valid_day" ;
VAL_ 880 Time_Month 0 "Invalid" 1 "Valid_month" 13 "Reserved" ;
VAL_ 880 Time_Year_Right 0 "Valid_year" 10 "Reserved" 15 "Invalid" ;
VAL_ 880 Time_Year_Left 0 "Valid_year" 10 "Reserved" 15 "Invalid" ;
VAL_ 880 Time_Second 0 "Valid_second" 60 "Reserved" 63 "Invalid" ;
VAL_ 880 Time_Minutes 0 "Valid_minute" 60 "Reserved" 63 "Invalid" ;
VAL_ 880 Time_Hour 0 "Valid_hour" 24 "Reserved" 31 "Invalid" ;
VAL_ 901 ACAmbTemp 0 "Valid_value" 254 "Initial_value" 255 "Invalid_Value" ;
VAL_ 1001 T_BOX_SysErrSts 0 "No_error" 1 "Error" 2 "Standby_Battery_Error" 3 "Reserved" ;
VAL_ 161 RollingCounter_CSA2 0 "Valid_value" 15 "Invalid_value" ;
VAL_ 161 SAS_Sts 0 "SAS_Angle_And_Speed_Correct" 1 "SAS_Not_Calibrated" 2 "Intermittent_Error_Detected" 3 "Permanent_Error_Detected" ;
VAL_ 161 SteerWheelSpdSign 0 "Left_Positive" 1 "Right_Negative" ;
VAL_ 161 SteerWheelSpd 0 "Valid_value" 10161 "Reserved" 32767 "Invalid" ;
VAL_ 161 SteerWheelAngSign 0 "Left_Positive" 1 "Right_Negative" ;
VAL_ 161 SteerWheelAng 0 "Valid_value" 7801 "Reserved" 32767 "Invalid" ;
VAL_ 161 Checksum_CSA2 0 "Valid_values" ;
VAL_ 1073 RollingCounter16 0 "Valid_value" 15 "Invalid_value" ;
VAL_ 1073 MRR_ObjMeasured_3 0 "Init" 1 "Measured" 2 "Predicted" 3 "Reserved" ;
VAL_ 1073 MRR_ObjMeasured_4 0 "Init" 1 "Measured" 2 "Predicted" 3 "Reserved" ;
VAL_ 1073 MRR_ObjHeading_4 0 "Valid_values" 4446 "Reserved" ;
VAL_ 1073 MRR_ObjAge_4 0 "Valid_value" ;
VAL_ 1073 MRR_ObjRCS_4 0 "Valid_values" 961 "Reserved" ;
VAL_ 1073 BlockCounter2 0 "Valid_value" ;
VAL_ 1073 VFC_ObjHeight_4 0 "Valid_values" 601 "Reserved" ;
VAL_ 1073 Checksum16 0 "Valid_value" ;
VAL_ 1073 RollingCounter15 0 "Valid_value" 15 "Invalid_value" ;
VAL_ 1073 VFC_ObjMotionDirection_4 0 "Init" 1 "Inverse_direction" 2 "Same_direction" 3 "cross" 4 "reserved" 5 "reserved" 6 "reserved" 7 "reserved" ;
VAL_ 1073 VFC_ObjLength_4 0 "Valid_values" 401 "Reserved" ;
VAL_ 1073 VFC_ObjWidth_4 0 "Valid_values" 501 "Reserved" ;
VAL_ 1073 MRR_ObjMotionType_4 0 "int" 1 "unknown" 2 "Drive" 3 "Stopped" 4 "Stand" 5 "reserved" 6 "reserved" 7 "reserved" ;
VAL_ 1073 MRR_ObjRAccelYStd_4 0 "Valid_values" ;
VAL_ 1073 MRR_ObjRAccelXStd_4 0 "Valid_values" ;
VAL_ 1073 MRR_ObjRelVelYStd_4 0 "Valid_values" ;
VAL_ 1073 MRR_ObjRelVelXStd_4 0 "Valid_values" ;
VAL_ 1073 Checksum15 0 "Valid_value" ;
VAL_ 1073 RollingCounter14 0 "Valid_value" 15 "Invalid_value" ;
VAL_ 1073 MRR_ObjType_4 0 "Unknown" 1 "Truck" 2 "Car" 3 "Pedestrian" 4 "Cyclist" 5 "Reserved" ;
VAL_ 1073 MRR_ObjDistYStd_4 0 "Valid_values" ;
VAL_ 1073 MRR_ObjDistXStd_4 0 "Valid_values" ;
VAL_ 1073 MRR_ObjRelAccelY_4 0 "Valid_values" ;
VAL_ 1073 MRR_ObjRelVelY_4 0 "Valid_values" 8174 "Reserved" ;
VAL_ 1073 MRR_ObjRelVelX_4 0 "Valid_values" 8174 "Reserved" ;
VAL_ 1073 Checksum14 0 "Valid_value" ;
VAL_ 1073 RollingCounter13 0 "Valid_value" 15 "Invalid_value" ;
VAL_ 1073 MRR_ObjRelAccelX_4 0 "Valid_values" ;
VAL_ 1073 MRR_ObjDistY_4 0 "Valid_values" ;
VAL_ 1073 MRR_ObjDistX_4 0 "Valid_values" 4080 "Reserved" ;
VAL_ 1073 MRR_ObjObstacleProb_4 0 "Valid_values" ;
VAL_ 1073 MRR_ObjExistProb_4 0 "Valid_values" ;
VAL_ 1073 MRR_ObjID_4 0 "Valid_values" ;
VAL_ 1073 Checksum13 0 "Valid_value" ;
VAL_ 1073 RollingCounter12 0 "Valid_value" 15 "Invalid_value" ;
VAL_ 1073 MRR_ObjRefPoint_3 0 "Rear" 1 "Rear_left" 2 "Left" 3 "Front_left" 4 "Front" 5 "Front_Right" 6 "Right" 7 "Rear_right" ;
VAL_ 1073 MRR_ObjRefPoint_4 0 "Rear" 1 "Rear_left" 2 "Left" 3 "Front_left" 4 "Front" 5 "Front_Right" 6 "Right" 7 "Rear_right" ;
VAL_ 1073 MRR_ObjAge_3 0 "Valid_value" ;
VAL_ 1073 MRR_ObjRCS_3 0 "Valid_values" 961 "Reserved" ;
VAL_ 1073 MRR_ObjHeading_3 0 "Valid_values" 4446 "Reserved" ;
VAL_ 1073 VFC_ObjHeight_3 0 "Valid_values" 601 "Reserved" ;
VAL_ 1073 Checksum12 0 "Valid_value" ;
VAL_ 1073 RollingCounter11 0 "Valid_value" 15 "Invalid_value" ;
VAL_ 1073 VFC_ObjMotionDirection_3 0 "Init" 1 "Inverse_direction" 2 "Same_direction" 3 "cross" 4 "reserved" 5 "reserved" 6 "reserved" 7 "reserved" ;
VAL_ 1073 VFC_ObjLength_3 0 "Valid_values" 401 "Reserved" ;
VAL_ 1073 VFC_ObjWidth_3 0 "Valid_values" 501 "Reserved" ;
VAL_ 1073 MRR_ObjMotionType_3 0 "int" 1 "unknown" 2 "Drive" 3 "Stopped" 4 "Stand" 5 "reserved" 6 "reserved" 7 "reserved" ;
VAL_ 1073 MRR_ObjRAccelYStd_3 0 "Valid_values" ;
VAL_ 1073 MRR_ObjRAccelXStd_3 0 "Valid_values" ;
VAL_ 1073 MRR_ObjRelVelYStd_3 0 "Valid_values" ;
VAL_ 1073 MRR_ObjRelVelXStd_3 0 "Valid_values" ;
VAL_ 1073 Checksum11 0 "Valid_value" ;
VAL_ 1073 RollingCounter10 0 "Valid_value" 15 "Invalid_value" ;
VAL_ 1073 MRR_ObjType_3 0 "Unknown" 1 "Truck" 2 "Car" 3 "Pedestrian" 4 "Cyclist" 5 "Reserved" ;
VAL_ 1073 MRR_ObjDistYStd_3 0 "Valid_values" ;
VAL_ 1073 MRR_ObjDistXStd_3 0 "Valid_values" ;
VAL_ 1073 MRR_ObjRelAccelY_3 0 "Valid_values" ;
VAL_ 1073 MRR_ObjRelVelY_3 0 "Valid_values" 8174 "Reserved" ;
VAL_ 1073 MRR_ObjRelVelX_3 0 "Valid_values" 8174 "Reserved" ;
VAL_ 1073 Checksum10 0 "Valid_value" ;
VAL_ 1073 RollingCounter9 0 "Valid_value" 15 "Invalid_value" ;
VAL_ 1073 MRR_ObjRelAccelX_3 0 "Valid_values" ;
VAL_ 1073 MRR_ObjDistY_3 0 "Valid_values" ;
VAL_ 1073 MRR_ObjDistX_3 0 "Valid_values" 4080 "Reserved" ;
VAL_ 1073 MRR_ObjObstacleProb_3 0 "Valid_values" ;
VAL_ 1073 MRR_ObjExistProb_3 0 "Valid_values" ;
VAL_ 1073 MRR_ObjID_3 0 "Valid_values" ;
VAL_ 1073 Checksum9 0 "Valid_value" ;
VAL_ 1074 RollingCounter24 0 "Valid_value" 15 "Invalid_value" ;
VAL_ 1074 MRR_ObjMeasured_5 0 "Init" 1 "Measured" 2 "Predicted" 3 "Reserved" ;
VAL_ 1074 MRR_ObjMeasured_6 0 "Init" 1 "Measured" 2 "Predicted" 3 "Reserved" ;
VAL_ 1074 MRR_ObjHeading_6 0 "Valid_values" 4446 "Reserved" ;
VAL_ 1074 MRR_ObjAge_6 0 "Valid_value" ;
VAL_ 1074 MRR_ObjRCS_6 0 "Valid_values" 961 "Reserved" ;
VAL_ 1074 BlockCounter3 0 "Valid_value" ;
VAL_ 1074 VFC_ObjHeight_6 0 "Valid_values" 601 "Reserved" ;
VAL_ 1074 Checksum24 0 "Valid_value" ;
VAL_ 1074 RollingCounter23 0 "Valid_value" 15 "Invalid_value" ;
VAL_ 1074 VFC_ObjMotionDirection_6 0 "Init" 1 "Inverse_direction" 2 "Same_direction" 3 "cross" 4 "reserved" 5 "reserved" 6 "reserved" 7 "reserved" ;
VAL_ 1074 VFC_ObjLength_6 0 "Valid_values" 401 "Reserved" ;
VAL_ 1074 VFC_ObjWidth_6 0 "Valid_values" 501 "Reserved" ;
VAL_ 1074 MRR_ObjMotionType_6 0 "int" 1 "unknown" 2 "Drive" 3 "Stopped" 4 "Stand" 5 "reserved" 6 "reserved" 7 "reserved" ;
VAL_ 1074 MRR_ObjRAccelYStd_6 0 "Valid_values" ;
VAL_ 1074 MRR_ObjRAccelXStd_6 0 "Valid_values" ;
VAL_ 1074 MRR_ObjRelVelYStd_6 0 "Valid_values" ;
VAL_ 1074 MRR_ObjRelVelXStd_6 0 "Valid_values" ;
VAL_ 1074 Checksum23 0 "Valid_value" ;
VAL_ 1074 RollingCounter22 0 "Valid_value" 15 "Invalid_value" ;
VAL_ 1074 MRR_ObjType_6 0 "Unknown" 1 "Truck" 2 "Car" 3 "Pedestrian" 4 "Cyclist" 5 "Reserved" ;
VAL_ 1074 MRR_ObjDistYStd_6 0 "Valid_values" ;
VAL_ 1074 MRR_ObjDistXStd_6 0 "Valid_values" ;
VAL_ 1074 MRR_ObjRelAccelY_6 0 "Valid_values" ;
VAL_ 1074 MRR_ObjRelVelY_6 0 "Valid_values" 8174 "Reserved" ;
VAL_ 1074 MRR_ObjRelVelX_6 0 "Valid_values" 8174 "Reserved" ;
VAL_ 1074 Checksum22 0 "Valid_value" ;
VAL_ 1074 RollingCounter21 0 "Valid_value" 15 "Invalid_value" ;
VAL_ 1074 MRR_ObjRelAccelX_6 0 "Valid_values" ;
VAL_ 1074 MRR_ObjDistY_6 0 "Valid_values" ;
VAL_ 1074 MRR_ObjDistX_6 0 "Valid_values" 4080 "Reserved" ;
VAL_ 1074 MRR_ObjObstacleProb_6 0 "Valid_values" ;
VAL_ 1074 MRR_ObjExistProb_6 0 "Valid_values" ;
VAL_ 1074 MRR_ObjID_6 0 "Valid_values" ;
VAL_ 1074 Checksum21 0 "Valid_value" ;
VAL_ 1074 RollingCounter20 0 "Valid_value" 15 "Invalid_value" ;
VAL_ 1074 MRR_ObjRefPoint_5 0 "Rear" 1 "Rear_left" 2 "Left" 3 "Front_left" 4 "Front" 5 "Front_Right" 6 "Right" 7 "Rear_right" ;
VAL_ 1074 MRR_ObjRefPoint_6 0 "Rear" 1 "Rear_left" 2 "Left" 3 "Front_left" 4 "Front" 5 "Front_Right" 6 "Right" 7 "Rear_right" ;
VAL_ 1074 MRR_ObjAge_5 0 "Valid_value" ;
VAL_ 1074 MRR_ObjRCS_5 0 "Valid_values" 961 "Reserved" ;
VAL_ 1074 MRR_ObjHeading_5 0 "Valid_values" 4446 "Reserved" ;
VAL_ 1074 VFC_ObjHeight_5 0 "Valid_values" 601 "Reserved" ;
VAL_ 1074 Checksum20 0 "Valid_value" ;
VAL_ 1074 RollingCounter19 0 "Valid_value" 15 "Invalid_value" ;
VAL_ 1074 VFC_ObjMotionDirection_5 0 "Init" 1 "Inverse_direction" 2 "Same_direction" 3 "cross" 4 "reserved" 5 "reserved" 6 "reserved" 7 "reserved" ;
VAL_ 1074 VFC_ObjLength_5 0 "Valid_values" 401 "Reserved" ;
VAL_ 1074 VFC_ObjWidth_5 0 "Valid_values" 501 "Reserved" ;
VAL_ 1074 MRR_ObjMotionType_5 0 "int" 1 "unknown" 2 "Drive" 3 "Stopped" 4 "Stand" 5 "reserved" 6 "reserved" 7 "reserved" ;
VAL_ 1074 MRR_ObjRAccelYStd_5 0 "Valid_values" ;
VAL_ 1074 MRR_ObjRAccelXStd_5 0 "Valid_values" ;
VAL_ 1074 MRR_ObjRelVelYStd_5 0 "Valid_values" ;
VAL_ 1074 MRR_ObjRelVelXStd_5 0 "Valid_values" ;
VAL_ 1074 Checksum19 0 "Valid_value" ;
VAL_ 1074 RollingCounter18 0 "Valid_value" 15 "Invalid_value" ;
VAL_ 1074 MRR_ObjType_5 0 "Unknown" 1 "Truck" 2 "Car" 3 "Pedestrian" 4 "Cyclist" 5 "Reserved" ;
VAL_ 1074 MRR_ObjDistYStd_5 0 "Valid_values" ;
VAL_ 1074 MRR_ObjDistXStd_5 0 "Valid_values" ;
VAL_ 1074 MRR_ObjRelAccelY_5 0 "Valid_values" ;
VAL_ 1074 MRR_ObjRelVelY_5 0 "Valid_values" 8174 "Reserved" ;
VAL_ 1074 MRR_ObjRelVelX_5 0 "Valid_values" 8174 "Reserved" ;
VAL_ 1074 Checksum18 0 "Valid_value" ;
VAL_ 1074 RollingCounter17 0 "Valid_value" 15 "Invalid_value" ;
VAL_ 1074 MRR_ObjRelAccelX_5 0 "Valid_values" ;
VAL_ 1074 MRR_ObjDistY_5 0 "Valid_values" ;
VAL_ 1074 MRR_ObjDistX_5 0 "Valid_values" 4080 "Reserved" ;
VAL_ 1074 MRR_ObjObstacleProb_5 0 "Valid_values" ;
VAL_ 1074 MRR_ObjExistProb_5 0 "Valid_values" ;
VAL_ 1074 MRR_ObjID_5 0 "Valid_values" ;
VAL_ 1074 Checksum17 0 "Valid_value" ;
VAL_ 1075 RollingCounter32 0 "Valid_value" 15 "Invalid_value" ;
VAL_ 1075 MRR_ObjMeasured_7 0 "Init" 1 "Measured" 2 "Predicted" 3 "Reserved" ;
VAL_ 1075 MRR_ObjMeasured_8 0 "Init" 1 "Measured" 2 "Predicted" 3 "Reserved" ;
VAL_ 1075 MRR_ObjHeading_8 0 "Valid_values" 4446 "Reserved" ;
VAL_ 1075 MRR_ObjAge_8 0 "Valid_value" ;
VAL_ 1075 MRR_ObjRCS_8 0 "Valid_values" 961 "Reserved" ;
VAL_ 1075 BlockCounter4 0 "Valid_value" ;
VAL_ 1075 VFC_ObjHeight_8 0 "Valid_values" 601 "Reserved" ;
VAL_ 1075 Checksum32 0 "Valid_value" ;
VAL_ 1075 RollingCounter31 0 "Valid_value" 15 "Invalid_value" ;
VAL_ 1075 VFC_ObjMotionDirection_8 0 "Init" 1 "Inverse_direction" 2 "Same_direction" 3 "cross" 4 "reserved" 5 "reserved" 6 "reserved" 7 "reserved" ;
VAL_ 1075 VFC_ObjLength_8 0 "Valid_values" 401 "Reserved" ;
VAL_ 1075 VFC_ObjWidth_8 0 "Valid_values" 501 "Reserved" ;
VAL_ 1075 MRR_ObjMotionType_8 0 "int" 1 "unknown" 2 "Drive" 3 "Stopped" 4 "Stand" 5 "reserved" 6 "reserved" 7 "reserved" ;
VAL_ 1075 MRR_ObjRAccelYStd_8 0 "Valid_values" ;
VAL_ 1075 MRR_ObjRAccelXStd_8 0 "Valid_values" ;
VAL_ 1075 MRR_ObjRelVelYStd_8 0 "Valid_values" ;
VAL_ 1075 MRR_ObjRelVelXStd_8 0 "Valid_values" ;
VAL_ 1075 Checksum31 0 "Valid_value" ;
VAL_ 1075 RollingCounter30 0 "Valid_value" 15 "Invalid_value" ;
VAL_ 1075 MRR_ObjType_8 0 "Unknown" 1 "Truck" 2 "Car" 3 "Pedestrian" 4 "Cyclist" 5 "Reserved" ;
VAL_ 1075 MRR_ObjDistYStd_8 0 "Valid_values" ;
VAL_ 1075 MRR_ObjDistXStd_8 0 "Valid_values" ;
VAL_ 1075 MRR_ObjRelAccelY_8 0 "Valid_values" ;
VAL_ 1075 MRR_ObjRelVelY_8 0 "Valid_values" 8174 "Reserved" ;
VAL_ 1075 MRR_ObjRelVelX_8 0 "Valid_values" 8174 "Reserved" ;
VAL_ 1075 Checksum30 0 "Valid_value" ;
VAL_ 1075 RollingCounter29 0 "Valid_value" 15 "Invalid_value" ;
VAL_ 1075 MRR_ObjRelAccelX_8 0 "Valid_values" ;
VAL_ 1075 MRR_ObjDistY_8 0 "Valid_values" ;
VAL_ 1075 MRR_ObjDistX_8 0 "Valid_values" 4080 "Reserved" ;
VAL_ 1075 MRR_ObjObstacleProb_8 0 "Valid_values" ;
VAL_ 1075 MRR_ObjExistProb_8 0 "Valid_values" ;
VAL_ 1075 MRR_ObjID_8 0 "Valid_values" ;
VAL_ 1075 Checksum29 0 "Valid_value" ;
VAL_ 1075 RollingCounter28 0 "Valid_value" 15 "Invalid_value" ;
VAL_ 1075 MRR_ObjRefPoint_7 0 "Rear" 1 "Rear_left" 2 "Left" 3 "Front_left" 4 "Front" 5 "Front_Right" 6 "Right" 7 "Rear_right" ;
VAL_ 1075 MRR_ObjRefPoint_8 0 "Rear" 1 "Rear_left" 2 "Left" 3 "Front_left" 4 "Front" 5 "Front_Right" 6 "Right" 7 "Rear_right" ;
VAL_ 1075 MRR_ObjAge_7 0 "Valid_value" ;
VAL_ 1075 MRR_ObjRCS_7 0 "Valid_values" 961 "Reserved" ;
VAL_ 1075 MRR_ObjHeading_7 0 "Valid_values" 4446 "Reserved" ;
VAL_ 1075 VFC_ObjHeight_7 0 "Valid_values" 601 "Reserved" ;
VAL_ 1075 Checksum28 0 "Valid_value" ;
VAL_ 1075 RollingCounter27 0 "Valid_value" 15 "Invalid_value" ;
VAL_ 1075 VFC_ObjMotionDirection_7 0 "Init" 1 "Inverse_direction" 2 "Same_direction" 3 "cross" 4 "reserved" 5 "reserved" 6 "reserved" 7 "reserved" ;
VAL_ 1075 VFC_ObjLength_7 0 "Valid_values" 401 "Reserved" ;
VAL_ 1075 VFC_ObjWidth_7 0 "Valid_values" 501 "Reserved" ;
VAL_ 1075 MRR_ObjMotionType_7 0 "int" 1 "unknown" 2 "Drive" 3 "Stopped" 4 "Stand" 5 "reserved" 6 "reserved" 7 "reserved" ;
VAL_ 1075 MRR_ObjRAccelYStd_7 0 "Valid_values" ;
VAL_ 1075 MRR_ObjRAccelXStd_7 0 "Valid_values" ;
VAL_ 1075 MRR_ObjRelVelYStd_7 0 "Valid_values" ;
VAL_ 1075 MRR_ObjRelVelXStd_7 0 "Valid_values" ;
VAL_ 1075 Checksum27 0 "Valid_value" ;
VAL_ 1075 RollingCounter26 0 "Valid_value" 15 "Invalid_value" ;
VAL_ 1075 MRR_ObjType_7 0 "Unknown" 1 "Truck" 2 "Car" 3 "Pedestrian" 4 "Cyclist" 5 "Reserved" ;
VAL_ 1075 MRR_ObjDistYStd_7 0 "Valid_values" ;
VAL_ 1075 MRR_ObjDistXStd_7 0 "Valid_values" ;
VAL_ 1075 MRR_ObjRelAccelY_7 0 "Valid_values" ;
VAL_ 1075 MRR_ObjRelVelY_7 0 "Valid_values" 8174 "Reserved" ;
VAL_ 1075 MRR_ObjRelVelX_7 0 "Valid_values" 8174 "Reserved" ;
VAL_ 1075 Checksum26 0 "Valid_value" ;
VAL_ 1075 RollingCounter25 0 "Valid_value" 15 "Invalid_value" ;
VAL_ 1075 MRR_ObjRelAccelX_7 0 "Valid_values" ;
VAL_ 1075 MRR_ObjDistY_7 0 "Valid_values" ;
VAL_ 1075 MRR_ObjDistX_7 0 "Valid_values" 4080 "Reserved" ;
VAL_ 1075 MRR_ObjObstacleProb_7 0 "Valid_values" ;
VAL_ 1075 MRR_ObjExistProb_7 0 "Valid_values" ;
VAL_ 1075 MRR_ObjID_7 0 "Valid_values" ;
VAL_ 1075 Checksum25 0 "Valid_value" ;
VAL_ 1076 RollingCounter40 0 "Valid_value" 15 "Invalid_value" ;
VAL_ 1076 MRR_ObjMeasured_9 0 "Init" 1 "Measured" 2 "Predicted" 3 "Reserved" ;
VAL_ 1076 MRR_ObjMeasured_10 0 "Init" 1 "Measured" 2 "Predicted" 3 "Reserved" ;
VAL_ 1076 MRR_ObjHeading_10 0 "Valid_values" 4446 "Reserved" ;
VAL_ 1076 MRR_ObjAge_10 0 "Valid_value" ;
VAL_ 1076 MRR_ObjRCS_10 0 "Valid_values" 961 "Reserved" ;
VAL_ 1076 BlockCounter5 0 "Valid_value" ;
VAL_ 1076 VFC_ObjHeight_10 0 "Valid_values" 601 "Reserved" ;
VAL_ 1076 Checksum40 0 "Valid_value" ;
VAL_ 1076 RollingCounter39 0 "Valid_value" 15 "Invalid_value" ;
VAL_ 1076 VFC_ObjMotionDirection_10 0 "Init" 1 "Inverse_direction" 2 "Same_direction" 3 "cross" 4 "reserved" 5 "reserved" 6 "reserved" 7 "reserved" ;
VAL_ 1076 VFC_ObjLength_10 0 "Valid_values" 401 "Reserved" ;
VAL_ 1076 VFC_ObjWidth_10 0 "Valid_values" 501 "Reserved" ;
VAL_ 1076 MRR_ObjMotionType_10 0 "int" 1 "unknown" 2 "Drive" 3 "Stopped" 4 "Stand" 5 "reserved" 6 "reserved" 7 "reserved" ;
VAL_ 1076 MRR_ObjRAccelYStd_10 0 "Valid_values" ;
VAL_ 1076 MRR_ObjRAccelXStd_10 0 "Valid_values" ;
VAL_ 1076 MRR_ObjRelVelYStd_10 0 "Valid_values" ;
VAL_ 1076 MRR_ObjRelVelXStd_10 0 "Valid_values" ;
VAL_ 1076 Checksum39 0 "Valid_value" ;
VAL_ 1076 RollingCounter38 0 "Valid_value" 15 "Invalid_value" ;
VAL_ 1076 MRR_ObjType_10 0 "Unknown" 1 "Truck" 2 "Car" 3 "Pedestrian" 4 "Cyclist" 5 "Reserved" ;
VAL_ 1076 MRR_ObjDistYStd_10 0 "Valid_values" ;
VAL_ 1076 MRR_ObjDistXStd_10 0 "Valid_values" ;
VAL_ 1076 MRR_ObjRelAccelY_10 0 "Valid_values" ;
VAL_ 1076 MRR_ObjRelVelY_10 0 "Valid_values" 8174 "Reserved" ;
VAL_ 1076 MRR_ObjRelVelX_10 0 "Valid_values" 8174 "Reserved" ;
VAL_ 1076 Checksum38 0 "Valid_value" ;
VAL_ 1076 RollingCounter37 0 "Valid_value" 15 "Invalid_value" ;
VAL_ 1076 MRR_ObjRelAccelX_10 0 "Valid_values" ;
VAL_ 1076 MRR_ObjDistY_10 0 "Valid_values" ;
VAL_ 1076 MRR_ObjDistX_10 0 "Valid_values" 4080 "Reserved" ;
VAL_ 1076 MRR_ObjObstacleProb_10 0 "Valid_values" ;
VAL_ 1076 MRR_ObjExistProb_10 0 "Valid_values" ;
VAL_ 1076 MRR_ObjID_10 0 "Valid_values" ;
VAL_ 1076 Checksum37 0 "Valid_value" ;
VAL_ 1076 RollingCounter36 0 "Valid_value" 15 "Invalid_value" ;
VAL_ 1076 MRR_ObjRefPoint_9 0 "Rear" 1 "Rear_left" 2 "Left" 3 "Front_left" 4 "Front" 5 "Front_Right" 6 "Right" 7 "Rear_right" ;
VAL_ 1076 MRR_ObjRefPoint_10 0 "Rear" 1 "Rear_left" 2 "Left" 3 "Front_left" 4 "Front" 5 "Front_Right" 6 "Right" 7 "Rear_right" ;
VAL_ 1076 MRR_ObjAge_9 0 "Valid_value" ;
VAL_ 1076 MRR_ObjRCS_9 0 "Valid_values" 961 "Reserved" ;
VAL_ 1076 MRR_ObjHeading_9 0 "Valid_values" 4446 "Reserved" ;
VAL_ 1076 VFC_ObjHeight_9 0 "Valid_values" 601 "Reserved" ;
VAL_ 1076 Checksum36 0 "Valid_value" ;
VAL_ 1076 RollingCounter35 0 "Valid_value" 15 "Invalid_value" ;
VAL_ 1076 VFC_ObjMotionDirection_9 0 "Init" 1 "Inverse_direction" 2 "Same_direction" 3 "cross" 4 "reserved" 5 "reserved" 6 "reserved" 7 "reserved" ;
VAL_ 1076 VFC_ObjLength_9 0 "Valid_values" 401 "Reserved" ;
VAL_ 1076 VFC_ObjWidth_9 0 "Valid_values" 501 "Reserved" ;
VAL_ 1076 MRR_ObjMotionType_9 0 "int" 1 "unknown" 2 "Drive" 3 "Stopped" 4 "Stand" 5 "reserved" 6 "reserved" 7 "reserved" ;
VAL_ 1076 MRR_ObjRAccelYStd_9 0 "Valid_values" ;
VAL_ 1076 MRR_ObjRAccelXStd_9 0 "Valid_values" ;
VAL_ 1076 MRR_ObjRelVelYStd_9 0 "Valid_values" ;
VAL_ 1076 MRR_ObjRelVelXStd_9 0 "Valid_values" ;
VAL_ 1076 Checksum35 0 "Valid_value" ;
VAL_ 1076 RollingCounter34 0 "Valid_value" 15 "Invalid_value" ;
VAL_ 1076 MRR_ObjType_9 0 "Unknown" 1 "Truck" 2 "Car" 3 "Pedestrian" 4 "Cyclist" 5 "Reserved" ;
VAL_ 1076 MRR_ObjDistYStd_9 0 "Valid_values" ;
VAL_ 1076 MRR_ObjDistXStd_9 0 "Valid_values" ;
VAL_ 1076 MRR_ObjRelAccelY_9 0 "Valid_values" ;
VAL_ 1076 MRR_ObjRelVelY_9 0 "Valid_values" 8174 "Reserved" ;
VAL_ 1076 MRR_ObjRelVelX_9 0 "Valid_values" 8174 "Reserved" ;
VAL_ 1076 Checksum34 0 "Valid_value" ;
VAL_ 1076 RollingCounter33 0 "Valid_value" 15 "Invalid_value" ;
VAL_ 1076 MRR_ObjRelAccelX_9 0 "Valid_values" ;
VAL_ 1076 MRR_ObjDistY_9 0 "Valid_values" ;
VAL_ 1076 MRR_ObjDistX_9 0 "Valid_values" 4080 "Reserved" ;
VAL_ 1076 MRR_ObjObstacleProb_9 0 "Valid_values" ;
VAL_ 1076 MRR_ObjExistProb_9 0 "Valid_values" ;
VAL_ 1076 MRR_ObjID_9 0 "Valid_values" ;
VAL_ 1076 Checksum33 0 "Valid_value" ;
VAL_ 1077 RollingCounter48 0 "Valid_value" 15 "Invalid_value" ;
VAL_ 1077 MRR_ObjMeasured_11 0 "Init" 1 "Measured" 2 "Predicted" 3 "Reserved" ;
VAL_ 1077 MRR_ObjMeasured_12 0 "Init" 1 "Measured" 2 "Predicted" 3 "Reserved" ;
VAL_ 1077 MRR_ObjHeading_12 0 "Valid_values" 4446 "Reserved" ;
VAL_ 1077 MRR_ObjAge_12 0 "Valid_value" ;
VAL_ 1077 MRR_ObjRCS_12 0 "Valid_values" 961 "Reserved" ;
VAL_ 1077 BlockCounter6 0 "Valid_value" ;
VAL_ 1077 VFC_ObjHeight_12 0 "Valid_values" 601 "Reserved" ;
VAL_ 1077 Checksum48 0 "Valid_value" ;
VAL_ 1077 RollingCounter47 0 "Valid_value" 15 "Invalid_value" ;
VAL_ 1077 VFC_ObjMotionDirection_12 0 "Init" 1 "Inverse_direction" 2 "Same_direction" 3 "cross" 4 "reserved" 5 "reserved" 6 "reserved" 7 "reserved" ;
VAL_ 1077 VFC_ObjLength_12 0 "Valid_values" 401 "Reserved" ;
VAL_ 1077 VFC_ObjWidth_12 0 "Valid_values" 501 "Reserved" ;
VAL_ 1077 MRR_ObjMotionType_12 0 "int" 1 "unknown" 2 "Drive" 3 "Stopped" 4 "Stand" 5 "reserved" 6 "reserved" 7 "reserved" ;
VAL_ 1077 MRR_ObjRAccelYStd_12 0 "Valid_values" ;
VAL_ 1077 MRR_ObjRAccelXStd_12 0 "Valid_values" ;
VAL_ 1077 MRR_ObjRelVelYStd_12 0 "Valid_values" ;
VAL_ 1077 MRR_ObjRelVelXStd_12 0 "Valid_values" ;
VAL_ 1077 Checksum47 0 "Valid_value" ;
VAL_ 1077 RollingCounter46 0 "Valid_value" 15 "Invalid_value" ;
VAL_ 1077 MRR_ObjType_12 0 "Unknown" 1 "Truck" 2 "Car" 3 "Pedestrian" 4 "Cyclist" 5 "Reserved" ;
VAL_ 1077 MRR_ObjDistYStd_12 0 "Valid_values" ;
VAL_ 1077 MRR_ObjDistXStd_12 0 "Valid_values" ;
VAL_ 1077 MRR_ObjRelAccelY_12 0 "Valid_values" ;
VAL_ 1077 MRR_ObjRelVelY_12 0 "Valid_values" 8174 "Reserved" ;
VAL_ 1077 MRR_ObjRelVelX_12 0 "Valid_values" 8174 "Reserved" ;
VAL_ 1077 Checksum46 0 "Valid_value" ;
VAL_ 1077 RollingCounter45 0 "Valid_value" 15 "Invalid_value" ;
VAL_ 1077 MRR_ObjRelAccelX_12 0 "Valid_values" ;
VAL_ 1077 MRR_ObjDistY_12 0 "Valid_values" ;
VAL_ 1077 MRR_ObjDistX_12 0 "Valid_values" 4080 "Reserved" ;
VAL_ 1077 MRR_ObjObstacleProb_12 0 "Valid_values" ;
VAL_ 1077 MRR_ObjExistProb_12 0 "Valid_values" ;
VAL_ 1077 MRR_ObjID_12 0 "Valid_values" ;
VAL_ 1077 Checksum45 0 "Valid_value" ;
VAL_ 1077 RollingCounter44 0 "Valid_value" 15 "Invalid_value" ;
VAL_ 1077 MRR_ObjRefPoint_11 0 "Rear" 1 "Rear_left" 2 "Left" 3 "Front_left" 4 "Front" 5 "Front_Right" 6 "Right" 7 "Rear_right" ;
VAL_ 1077 MRR_ObjRefPoint_12 0 "Rear" 1 "Rear_left" 2 "Left" 3 "Front_left" 4 "Front" 5 "Front_Right" 6 "Right" 7 "Rear_right" ;
VAL_ 1077 MRR_ObjAge_11 0 "Valid_value" ;
VAL_ 1077 MRR_ObjRCS_11 0 "Valid_values" 961 "Reserved" ;
VAL_ 1077 MRR_ObjHeading_11 0 "Valid_values" 4446 "Reserved" ;
VAL_ 1077 VFC_ObjHeight_11 0 "Valid_values" 601 "Reserved" ;
VAL_ 1077 Checksum44 0 "Valid_value" ;
VAL_ 1077 RollingCounter43 0 "Valid_value" 15 "Invalid_value" ;
VAL_ 1077 VFC_ObjMotionDirection_11 0 "Init" 1 "Inverse_direction" 2 "Same_direction" 3 "cross" 4 "reserved" 5 "reserved" 6 "reserved" 7 "reserved" ;
VAL_ 1077 VFC_ObjLength_11 0 "Valid_values" 401 "Reserved" ;
VAL_ 1077 VFC_ObjWidth_11 0 "Valid_values" 501 "Reserved" ;
VAL_ 1077 MRR_ObjMotionType_11 0 "int" 1 "unknown" 2 "Drive" 3 "Stopped" 4 "Stand" 5 "reserved" 6 "reserved" 7 "reserved" ;
VAL_ 1077 MRR_ObjRAccelYStd_11 0 "Valid_values" ;
VAL_ 1077 MRR_ObjRAccelXStd_11 0 "Valid_values" ;
VAL_ 1077 MRR_ObjRelVelYStd_11 0 "Valid_values" ;
VAL_ 1077 MRR_ObjRelVelXStd_11 0 "Valid_values" ;
VAL_ 1077 Checksum43 0 "Valid_value" ;
VAL_ 1077 RollingCounter42 0 "Valid_value" 15 "Invalid_value" ;
VAL_ 1077 MRR_ObjType_11 0 "Unknown" 1 "Truck" 2 "Car" 3 "Pedestrian" 4 "Cyclist" 5 "Reserved" ;
VAL_ 1077 MRR_ObjDistYStd_11 0 "Valid_values" ;
VAL_ 1077 MRR_ObjDistXStd_11 0 "Valid_values" ;
VAL_ 1077 MRR_ObjRelAccelY_11 0 "Valid_values" ;
VAL_ 1077 MRR_ObjRelVelY_11 0 "Valid_values" 8174 "Reserved" ;
VAL_ 1077 MRR_ObjRelVelX_11 0 "Valid_values" 8174 "Reserved" ;
VAL_ 1077 Checksum42 0 "Valid_value" ;
VAL_ 1077 RollingCounter41 0 "Valid_value" 15 "Invalid_value" ;
VAL_ 1077 MRR_ObjRelAccelX_11 0 "Valid_values" ;
VAL_ 1077 MRR_ObjDistY_11 0 "Valid_values" ;
VAL_ 1077 MRR_ObjDistX_11 0 "Valid_values" 4080 "Reserved" ;
VAL_ 1077 MRR_ObjObstacleProb_11 0 "Valid_values" ;
VAL_ 1077 MRR_ObjExistProb_11 0 "Valid_values" ;
VAL_ 1077 MRR_ObjID_11 0 "Valid_values" ;
VAL_ 1077 Checksum41 0 "Valid_value" ;
VAL_ 1078 RollingCounter56 0 "Valid_value" 15 "Invalid_value" ;
VAL_ 1078 MRR_ObjMeasured_13 0 "Init" 1 "Measured" 2 "Predicted" 3 "Reserved" ;
VAL_ 1078 MRR_ObjMeasured_14 0 "Init" 1 "Measured" 2 "Predicted" 3 "Reserved" ;
VAL_ 1078 MRR_ObjHeading_14 0 "Valid_values" 4446 "Reserved" ;
VAL_ 1078 MRR_ObjAge_14 0 "Valid_value" ;
VAL_ 1078 MRR_ObjRCS_14 0 "Valid_values" 961 "Reserved" ;
VAL_ 1078 BlockCounter7 0 "Valid_value" ;
VAL_ 1078 VFC_ObjHeight_14 0 "Valid_values" 601 "Reserved" ;
VAL_ 1078 Checksum56 0 "Valid_value" ;
VAL_ 1078 RollingCounter55 0 "Valid_value" 15 "Invalid_value" ;
VAL_ 1078 VFC_ObjMotionDirection_14 0 "Init" 1 "Inverse_direction" 2 "Same_direction" 3 "cross" 4 "reserved" 5 "reserved" 6 "reserved" 7 "reserved" ;
VAL_ 1078 VFC_ObjLength_14 0 "Valid_values" 401 "Reserved" ;
VAL_ 1078 VFC_ObjWidth_14 0 "Valid_values" 501 "Reserved" ;
VAL_ 1078 MRR_ObjMotionType_14 0 "int" 1 "unknown" 2 "Drive" 3 "Stopped" 4 "Stand" 5 "reserved" 6 "reserved" 7 "reserved" ;
VAL_ 1078 MRR_ObjRAccelYStd_14 0 "Valid_values" ;
VAL_ 1078 MRR_ObjRAccelXStd_14 0 "Valid_values" ;
VAL_ 1078 MRR_ObjRelVelYStd_14 0 "Valid_values" ;
VAL_ 1078 MRR_ObjRelVelXStd_14 0 "Valid_values" ;
VAL_ 1078 Checksum55 0 "Valid_value" ;
VAL_ 1078 RollingCounter54 0 "Valid_value" 15 "Invalid_value" ;
VAL_ 1078 MRR_ObjType_14 0 "Unknown" 1 "Truck" 2 "Car" 3 "Pedestrian" 4 "Cyclist" 5 "Reserved" ;
VAL_ 1078 MRR_ObjDistYStd_14 0 "Valid_values" ;
VAL_ 1078 MRR_ObjDistXStd_14 0 "Valid_values" ;
VAL_ 1078 MRR_ObjRelAccelY_14 0 "Valid_values" ;
VAL_ 1078 MRR_ObjRelVelY_14 0 "Valid_values" 8174 "Reserved" ;
VAL_ 1078 MRR_ObjRelVelX_14 0 "Valid_values" 8174 "Reserved" ;
VAL_ 1078 Checksum54 0 "Valid_value" ;
VAL_ 1078 RollingCounter53 0 "Valid_value" 15 "Invalid_value" ;
VAL_ 1078 MRR_ObjRelAccelX_14 0 "Valid_values" ;
VAL_ 1078 MRR_ObjDistY_14 0 "Valid_values" ;
VAL_ 1078 MRR_ObjDistX_14 0 "Valid_values" 4080 "Reserved" ;
VAL_ 1078 MRR_ObjObstacleProb_14 0 "Valid_values" ;
VAL_ 1078 MRR_ObjExistProb_14 0 "Valid_values" ;
VAL_ 1078 MRR_ObjID_14 0 "Valid_values" ;
VAL_ 1078 Checksum53 0 "Valid_value" ;
VAL_ 1078 RollingCounter52 0 "Valid_value" 15 "Invalid_value" ;
VAL_ 1078 MRR_ObjRefPoint_13 0 "Rear" 1 "Rear_left" 2 "Left" 3 "Front_left" 4 "Front" 5 "Front_Right" 6 "Right" 7 "Rear_right" ;
VAL_ 1078 MRR_ObjRefPoint_14 0 "Rear" 1 "Rear_left" 2 "Left" 3 "Front_left" 4 "Front" 5 "Front_Right" 6 "Right" 7 "Rear_right" ;
VAL_ 1078 MRR_ObjAge_13 0 "Valid_value" ;
VAL_ 1078 MRR_ObjRCS_13 0 "Valid_values" 961 "Reserved" ;
VAL_ 1078 MRR_ObjHeading_13 0 "Valid_values" 4446 "Reserved" ;
VAL_ 1078 VFC_ObjHeight_13 0 "Valid_values" 601 "Reserved" ;
VAL_ 1078 Checksum52 0 "Valid_value" ;
VAL_ 1078 RollingCounter51 0 "Valid_value" 15 "Invalid_value" ;
VAL_ 1078 VFC_ObjMotionDirection_13 0 "Init" 1 "Inverse_direction" 2 "Same_direction" 3 "cross" 4 "reserved" 5 "reserved" 6 "reserved" 7 "reserved" ;
VAL_ 1078 VFC_ObjLength_13 0 "Valid_values" 401 "Reserved" ;
VAL_ 1078 VFC_ObjWidth_13 0 "Valid_values" 501 "Reserved" ;
VAL_ 1078 MRR_ObjMotionType_13 0 "int" 1 "unknown" 2 "Drive" 3 "Stopped" 4 "Stand" 5 "reserved" 6 "reserved" 7 "reserved" ;
VAL_ 1078 MRR_ObjRAccelYStd_13 0 "Valid_values" ;
VAL_ 1078 MRR_ObjRAccelXStd_13 0 "Valid_values" ;
VAL_ 1078 MRR_ObjRelVelYStd_13 0 "Valid_values" ;
VAL_ 1078 MRR_ObjRelVelXStd_13 0 "Valid_values" ;
VAL_ 1078 Checksum51 0 "Valid_value" ;
VAL_ 1078 RollingCounter50 0 "Valid_value" 15 "Invalid_value" ;
VAL_ 1078 MRR_ObjType_13 0 "Unknown" 1 "Truck" 2 "Car" 3 "Pedestrian" 4 "Cyclist" 5 "Reserved" ;
VAL_ 1078 MRR_ObjDistYStd_13 0 "Valid_values" ;
VAL_ 1078 MRR_ObjDistXStd_13 0 "Valid_values" ;
VAL_ 1078 MRR_ObjRelAccelY_13 0 "Valid_values" ;
VAL_ 1078 MRR_ObjRelVelY_13 0 "Valid_values" 8174 "Reserved" ;
VAL_ 1078 MRR_ObjRelVelX_13 0 "Valid_values" 8174 "Reserved" ;
VAL_ 1078 Checksum50 0 "Valid_value" ;
VAL_ 1078 RollingCounter49 0 "Valid_value" 15 "Invalid_value" ;
VAL_ 1078 MRR_ObjRelAccelX_13 0 "Valid_values" ;
VAL_ 1078 MRR_ObjDistY_13 0 "Valid_values" ;
VAL_ 1078 MRR_ObjDistX_13 0 "Valid_values" 4080 "Reserved" ;
VAL_ 1078 MRR_ObjObstacleProb_13 0 "Valid_values" ;
VAL_ 1078 MRR_ObjExistProb_13 0 "Valid_values" ;
VAL_ 1078 MRR_ObjID_13 0 "Valid_values" ;
VAL_ 1078 Checksum49 0 "Valid_value" ;
VAL_ 1079 RollingCounter64 0 "Valid_value" 15 "Invalid_value" ;
VAL_ 1079 MRR_ObjMeasured_15 0 "Init" 1 "Measured" 2 "Predicted" 3 "Reserved" ;
VAL_ 1079 MRR_ObjMeasured_16 0 "Init" 1 "Measured" 2 "Predicted" 3 "Reserved" ;
VAL_ 1079 MRR_ObjHeading_16 0 "Valid_values" 4446 "Reserved" ;
VAL_ 1079 MRR_ObjAge_16 0 "Valid_value" ;
VAL_ 1079 MRR_ObjRCS_16 0 "Valid_values" 961 "Reserved" ;
VAL_ 1079 BlockCounter8 0 "Valid_value" ;
VAL_ 1079 VFC_ObjHeight_16 0 "Valid_values" 601 "Reserved" ;
VAL_ 1079 Checksum64 0 "Valid_value" ;
VAL_ 1079 RollingCounter63 0 "Valid_value" 15 "Invalid_value" ;
VAL_ 1079 VFC_ObjMotionDirection_16 0 "Init" 1 "Inverse_direction" 2 "Same_direction" 3 "cross" 4 "reserved" 5 "reserved" 6 "reserved" 7 "reserved" ;
VAL_ 1079 VFC_ObjLength_16 0 "Valid_values" 401 "Reserved" ;
VAL_ 1079 VFC_ObjWidth_16 0 "Valid_values" 501 "Reserved" ;
VAL_ 1079 MRR_ObjMotionType_16 0 "int" 1 "unknown" 2 "Drive" 3 "Stopped" 4 "Stand" 5 "reserved" 6 "reserved" 7 "reserved" ;
VAL_ 1079 MRR_ObjRAccelYStd_16 0 "Valid_values" ;
VAL_ 1079 MRR_ObjRAccelXStd_16 0 "Valid_values" ;
VAL_ 1079 MRR_ObjRelVelYStd_16 0 "Valid_values" ;
VAL_ 1079 MRR_ObjRelVelXStd_16 0 "Valid_values" ;
VAL_ 1079 Checksum63 0 "Valid_value" ;
VAL_ 1079 RollingCounter62 0 "Valid_value" 15 "Invalid_value" ;
VAL_ 1079 MRR_ObjType_16 0 "Unknown" 1 "Truck" 2 "Car" 3 "Pedestrian" 4 "Cyclist" 5 "Reserved" ;
VAL_ 1079 MRR_ObjDistYStd_16 0 "Valid_values" ;
VAL_ 1079 MRR_ObjDistXStd_16 0 "Valid_values" ;
VAL_ 1079 MRR_ObjRelAccelY_16 0 "Valid_values" ;
VAL_ 1079 MRR_ObjRelVelY_16 0 "Valid_values" 8174 "Reserved" ;
VAL_ 1079 MRR_ObjRelVelX_16 0 "Valid_values" 8174 "Reserved" ;
VAL_ 1079 Checksum62 0 "Valid_value" ;
VAL_ 1079 RollingCounter61 0 "Valid_value" 15 "Invalid_value" ;
VAL_ 1079 MRR_ObjRelAccelX_16 0 "Valid_values" ;
VAL_ 1079 MRR_ObjDistY_16 0 "Valid_values" ;
VAL_ 1079 MRR_ObjDistX_16 0 "Valid_values" 4080 "Reserved" ;
VAL_ 1079 MRR_ObjObstacleProb_16 0 "Valid_values" ;
VAL_ 1079 MRR_ObjExistProb_16 0 "Valid_values" ;
VAL_ 1079 MRR_ObjID_16 0 "Valid_values" ;
VAL_ 1079 Checksum61 0 "Valid_value" ;
VAL_ 1079 RollingCounter60 0 "Valid_value" 15 "Invalid_value" ;
VAL_ 1079 MRR_ObjRefPoint_15 0 "Rear" 1 "Rear_left" 2 "Left" 3 "Front_left" 4 "Front" 5 "Front_Right" 6 "Right" 7 "Rear_right" ;
VAL_ 1079 MRR_ObjRefPoint_16 0 "Rear" 1 "Rear_left" 2 "Left" 3 "Front_left" 4 "Front" 5 "Front_Right" 6 "Right" 7 "Rear_right" ;
VAL_ 1079 MRR_ObjAge_15 0 "Valid_value" ;
VAL_ 1079 MRR_ObjRCS_15 0 "Valid_values" 961 "Reserved" ;
VAL_ 1079 MRR_ObjHeading_15 0 "Valid_values" 4446 "Reserved" ;
VAL_ 1079 VFC_ObjHeight_15 0 "Valid_values" 601 "Reserved" ;
VAL_ 1079 Checksum60 0 "Valid_value" ;
VAL_ 1079 RollingCounter59 0 "Valid_value" 15 "Invalid_value" ;
VAL_ 1079 VFC_ObjMotionDirection_15 0 "Init" 1 "Inverse_direction" 2 "Same_direction" 3 "cross" 4 "reserved" 5 "reserved" 6 "reserved" 7 "reserved" ;
VAL_ 1079 VFC_ObjLength_15 0 "Valid_values" 401 "Reserved" ;
VAL_ 1079 VFC_ObjWidth_15 0 "Valid_values" 501 "Reserved" ;
VAL_ 1079 MRR_ObjMotionType_15 0 "int" 1 "unknown" 2 "Drive" 3 "Stopped" 4 "Stand" 5 "reserved" 6 "reserved" 7 "reserved" ;
VAL_ 1079 MRR_ObjRAccelYStd_15 0 "Valid_values" ;
VAL_ 1079 MRR_ObjRAccelXStd_15 0 "Valid_values" ;
VAL_ 1079 MRR_ObjRelVelYStd_15 0 "Valid_values" ;
VAL_ 1079 MRR_ObjRelVelXStd_15 0 "Valid_values" ;
VAL_ 1079 Checksum59 0 "Valid_value" ;
VAL_ 1079 RollingCounter58 0 "Valid_value" 15 "Invalid_value" ;
VAL_ 1079 MRR_ObjType_15 0 "Unknown" 1 "Truck" 2 "Car" 3 "Pedestrian" 4 "Cyclist" 5 "Reserved" ;
VAL_ 1079 MRR_ObjDistYStd_15 0 "Valid_values" ;
VAL_ 1079 MRR_ObjDistXStd_15 0 "Valid_values" ;
VAL_ 1079 MRR_ObjRelAccelY_15 0 "Valid_values" ;
VAL_ 1079 MRR_ObjRelVelY_15 0 "Valid_values" 8174 "Reserved" ;
VAL_ 1079 MRR_ObjRelVelX_15 0 "Valid_values" 8174 "Reserved" ;
VAL_ 1079 Checksum58 0 "Valid_value" ;
VAL_ 1079 RollingCounter57 0 "Valid_value" 15 "Invalid_value" ;
VAL_ 1079 MRR_ObjRelAccelX_15 0 "Valid_values" ;
VAL_ 1079 MRR_ObjDistY_15 0 "Valid_values" ;
VAL_ 1079 MRR_ObjDistX_15 0 "Valid_values" 4080 "Reserved" ;
VAL_ 1079 MRR_ObjObstacleProb_15 0 "Valid_values" ;
VAL_ 1079 MRR_ObjExistProb_15 0 "Valid_values" ;
VAL_ 1079 MRR_ObjID_15 0 "Valid_values" ;
VAL_ 1079 Checksum57 0 "Valid_value" ;
VAL_ 1080 RollingCounter72 0 "Valid_value" 15 "Invalid_value" ;
VAL_ 1080 MRR_ObjMeasured_17 0 "Init" 1 "Measured" 2 "Predicted" 3 "Reserved" ;
VAL_ 1080 MRR_ObjMeasured_18 0 "Init" 1 "Measured" 2 "Predicted" 3 "Reserved" ;
VAL_ 1080 MRR_ObjHeading_18 0 "Valid_values" 4446 "Reserved" ;
VAL_ 1080 MRR_ObjAge_18 0 "Valid_value" ;
VAL_ 1080 MRR_ObjRCS_18 0 "Valid_values" 961 "Reserved" ;
VAL_ 1080 BlockCounter9 0 "Valid_value" ;
VAL_ 1080 VFC_ObjHeight_18 0 "Valid_values" 601 "Reserved" ;
VAL_ 1080 Checksum72 0 "Valid_value" ;
VAL_ 1080 RollingCounter71 0 "Valid_value" 15 "Invalid_value" ;
VAL_ 1080 VFC_ObjMotionDirection_18 0 "Init" 1 "Inverse_direction" 2 "Same_direction" 3 "cross" 4 "reserved" 5 "reserved" 6 "reserved" 7 "reserved" ;
VAL_ 1080 VFC_ObjLength_18 0 "Valid_values" 401 "Reserved" ;
VAL_ 1080 VFC_ObjWidth_18 0 "Valid_values" 501 "Reserved" ;
VAL_ 1080 MRR_ObjMotionType_18 0 "int" 1 "unknown" 2 "Drive" 3 "Stopped" 4 "Stand" 5 "reserved" 6 "reserved" 7 "reserved" ;
VAL_ 1080 MRR_ObjRAccelYStd_18 0 "Valid_values" ;
VAL_ 1080 MRR_ObjRAccelXStd_18 0 "Valid_values" ;
VAL_ 1080 MRR_ObjRelVelYStd_18 0 "Valid_values" ;
VAL_ 1080 MRR_ObjRelVelXStd_18 0 "Valid_values" ;
VAL_ 1080 Checksum71 0 "Valid_value" ;
VAL_ 1080 RollingCounter70 0 "Valid_value" 15 "Invalid_value" ;
VAL_ 1080 MRR_ObjType_18 0 "Unknown" 1 "Truck" 2 "Car" 3 "Pedestrian" 4 "Cyclist" 5 "Reserved" ;
VAL_ 1080 MRR_ObjDistYStd_18 0 "Valid_values" ;
VAL_ 1080 MRR_ObjDistXStd_18 0 "Valid_values" ;
VAL_ 1080 MRR_ObjRelAccelY_18 0 "Valid_values" ;
VAL_ 1080 MRR_ObjRelVelY_18 0 "Valid_values" 8174 "Reserved" ;
VAL_ 1080 MRR_ObjRelVelX_18 0 "Valid_values" 8174 "Reserved" ;
VAL_ 1080 Checksum70 0 "Valid_value" ;
VAL_ 1080 RollingCounter69 0 "Valid_value" 15 "Invalid_value" ;
VAL_ 1080 MRR_ObjRelAccelX_18 0 "Valid_values" ;
VAL_ 1080 MRR_ObjDistY_18 0 "Valid_values" ;
VAL_ 1080 MRR_ObjDistX_18 0 "Valid_values" 4080 "Reserved" ;
VAL_ 1080 MRR_ObjObstacleProb_18 0 "Valid_values" ;
VAL_ 1080 MRR_ObjExistProb_18 0 "Valid_values" ;
VAL_ 1080 MRR_ObjID_18 0 "Valid_values" ;
VAL_ 1080 Checksum69 0 "Valid_value" ;
VAL_ 1080 RollingCounter68 0 "Valid_value" 15 "Invalid_value" ;
VAL_ 1080 MRR_ObjRefPoint_17 0 "Rear" 1 "Rear_left" 2 "Left" 3 "Front_left" 4 "Front" 5 "Front_Right" 6 "Right" 7 "Rear_right" ;
VAL_ 1080 MRR_ObjRefPoint_18 0 "Rear" 1 "Rear_left" 2 "Left" 3 "Front_left" 4 "Front" 5 "Front_Right" 6 "Right" 7 "Rear_right" ;
VAL_ 1080 MRR_ObjAge_17 0 "Valid_value" ;
VAL_ 1080 MRR_ObjRCS_17 0 "Valid_values" 961 "Reserved" ;
VAL_ 1080 MRR_ObjHeading_17 0 "Valid_values" 4446 "Reserved" ;
VAL_ 1080 VFC_ObjHeight_17 0 "Valid_values" 601 "Reserved" ;
VAL_ 1080 Checksum68 0 "Valid_value" ;
VAL_ 1080 RollingCounter67 0 "Valid_value" 15 "Invalid_value" ;
VAL_ 1080 VFC_ObjMotionDirection_17 0 "Init" 1 "Inverse_direction" 2 "Same_direction" 3 "cross" 4 "reserved" 5 "reserved" 6 "reserved" 7 "reserved" ;
VAL_ 1080 VFC_ObjLength_17 0 "Valid_values" 401 "Reserved" ;
VAL_ 1080 VFC_ObjWidth_17 0 "Valid_values" 501 "Reserved" ;
VAL_ 1080 MRR_ObjMotionType_17 0 "int" 1 "unknown" 2 "Drive" 3 "Stopped" 4 "Stand" 5 "reserved" 6 "reserved" 7 "reserved" ;
VAL_ 1080 MRR_ObjRAccelYStd_17 0 "Valid_values" ;
VAL_ 1080 MRR_ObjRAccelXStd_17 0 "Valid_values" ;
VAL_ 1080 MRR_ObjRelVelYStd_17 0 "Valid_values" ;
VAL_ 1080 MRR_ObjRelVelXStd_17 0 "Valid_values" ;
VAL_ 1080 Checksum67 0 "Valid_value" ;
VAL_ 1080 RollingCounter66 0 "Valid_value" 15 "Invalid_value" ;
VAL_ 1080 MRR_ObjType_17 0 "Unknown" 1 "Truck" 2 "Car" 3 "Pedestrian" 4 "Cyclist" 5 "Reserved" ;
VAL_ 1080 MRR_ObjDistYStd_17 0 "Valid_values" ;
VAL_ 1080 MRR_ObjDistXStd_17 0 "Valid_values" ;
VAL_ 1080 MRR_ObjRelAccelY_17 0 "Valid_values" ;
VAL_ 1080 MRR_ObjRelVelY_17 0 "Valid_values" 8174 "Reserved" ;
VAL_ 1080 MRR_ObjRelVelX_17 0 "Valid_values" 8174 "Reserved" ;
VAL_ 1080 Checksum66 0 "Valid_value" ;
VAL_ 1080 RollingCounter65 0 "Valid_value" 15 "Invalid_value" ;
VAL_ 1080 MRR_ObjRelAccelX_17 0 "Valid_values" ;
VAL_ 1080 MRR_ObjDistY_17 0 "Valid_values" ;
VAL_ 1080 MRR_ObjDistX_17 0 "Valid_values" 4080 "Reserved" ;
VAL_ 1080 MRR_ObjObstacleProb_17 0 "Valid_values" ;
VAL_ 1080 MRR_ObjExistProb_17 0 "Valid_values" ;
VAL_ 1080 MRR_ObjID_17 0 "Valid_values" ;
VAL_ 1080 Checksum65 0 "Valid_value" ;
VAL_ 1081 RollingCounter80 0 "Valid_value" 15 "Invalid_value" ;
VAL_ 1081 MRR_ObjMeasured_19 0 "Init" 1 "Measured" 2 "Predicted" 3 "Reserved" ;
VAL_ 1081 MRR_ObjMeasured_20 0 "Init" 1 "Measured" 2 "Predicted" 3 "Reserved" ;
VAL_ 1081 MRR_ObjHeading_20 0 "Valid_values" 4446 "Reserved" ;
VAL_ 1081 MRR_ObjAge_20 0 "Valid_value" ;
VAL_ 1081 MRR_ObjRCS_20 0 "Valid_values" 961 "Reserved" ;
VAL_ 1081 BlockCounter10 0 "Valid_value" ;
VAL_ 1081 VFC_ObjHeight_20 0 "Valid_values" 601 "Reserved" ;
VAL_ 1081 Checksum80 0 "Valid_value" ;
VAL_ 1081 RollingCounter79 0 "Valid_value" 15 "Invalid_value" ;
VAL_ 1081 VFC_ObjMotionDirection_20 0 "Init" 1 "Inverse_direction" 2 "Same_direction" 3 "cross" 4 "reserved" 5 "reserved" 6 "reserved" 7 "reserved" ;
VAL_ 1081 VFC_ObjLength_20 0 "Valid_values" 401 "Reserved" ;
VAL_ 1081 VFC_ObjWidth_20 0 "Valid_values" 501 "Reserved" ;
VAL_ 1081 MRR_ObjMotionType_20 0 "int" 1 "unknown" 2 "Drive" 3 "Stopped" 4 "Stand" 5 "reserved" 6 "reserved" 7 "reserved" ;
VAL_ 1081 MRR_ObjRAccelYStd_20 0 "Valid_values" ;
VAL_ 1081 MRR_ObjRAccelXStd_20 0 "Valid_values" ;
VAL_ 1081 MRR_ObjRelVelYStd_20 0 "Valid_values" ;
VAL_ 1081 MRR_ObjRelVelXStd_20 0 "Valid_values" ;
VAL_ 1081 Checksum79 0 "Valid_value" ;
VAL_ 1081 RollingCounter78 0 "Valid_value" 15 "Invalid_value" ;
VAL_ 1081 MRR_ObjType_20 0 "Unknown" 1 "Truck" 2 "Car" 3 "Pedestrian" 4 "Cyclist" 5 "Reserved" ;
VAL_ 1081 MRR_ObjDistYStd_20 0 "Valid_values" ;
VAL_ 1081 MRR_ObjDistXStd_20 0 "Valid_values" ;
VAL_ 1081 MRR_ObjRelAccelY_20 0 "Valid_values" ;
VAL_ 1081 MRR_ObjRelVelY_20 0 "Valid_values" 8174 "Reserved" ;
VAL_ 1081 MRR_ObjRelVelX_20 0 "Valid_values" 8174 "Reserved" ;
VAL_ 1081 Checksum78 0 "Valid_value" ;
VAL_ 1081 RollingCounter77 0 "Valid_value" 15 "Invalid_value" ;
VAL_ 1081 MRR_ObjRelAccelX_20 0 "Valid_values" ;
VAL_ 1081 MRR_ObjDistY_20 0 "Valid_values" ;
VAL_ 1081 MRR_ObjDistX_20 0 "Valid_values" 4080 "Reserved" ;
VAL_ 1081 MRR_ObjObstacleProb_20 0 "Valid_values" ;
VAL_ 1081 MRR_ObjExistProb_20 0 "Valid_values" ;
VAL_ 1081 MRR_ObjID_20 0 "Valid_values" ;
VAL_ 1081 Checksum77 0 "Valid_value" ;
VAL_ 1081 RollingCounter76 0 "Valid_value" 15 "Invalid_value" ;
VAL_ 1081 MRR_ObjRefPoint_19 0 "Rear" 1 "Rear_left" 2 "Left" 3 "Front_left" 4 "Front" 5 "Front_Right" 6 "Right" 7 "Rear_right" ;
VAL_ 1081 MRR_ObjRefPoint_20 0 "Rear" 1 "Rear_left" 2 "Left" 3 "Front_left" 4 "Front" 5 "Front_Right" 6 "Right" 7 "Rear_right" ;
VAL_ 1081 MRR_ObjAge_19 0 "Valid_value" ;
VAL_ 1081 MRR_ObjRCS_19 0 "Valid_values" 961 "Reserved" ;
VAL_ 1081 MRR_ObjHeading_19 0 "Valid_values" 4446 "Reserved" ;
VAL_ 1081 VFC_ObjHeight_19 0 "Valid_values" 601 "Reserved" ;
VAL_ 1081 Checksum76 0 "Valid_value" ;
VAL_ 1081 RollingCounter75 0 "Valid_value" 15 "Invalid_value" ;
VAL_ 1081 VFC_ObjMotionDirection_19 0 "Init" 1 "Inverse_direction" 2 "Same_direction" 3 "cross" 4 "reserved" 5 "reserved" 6 "reserved" 7 "reserved" ;
VAL_ 1081 VFC_ObjLength_19 0 "Valid_values" 401 "Reserved" ;
VAL_ 1081 VFC_ObjWidth_19 0 "Valid_values" 501 "Reserved" ;
VAL_ 1081 MRR_ObjMotionType_19 0 "int" 1 "unknown" 2 "Drive" 3 "Stopped" 4 "Stand" 5 "reserved" 6 "reserved" 7 "reserved" ;
VAL_ 1081 MRR_ObjRAccelYStd_19 0 "Valid_values" ;
VAL_ 1081 MRR_ObjRAccelXStd_19 0 "Valid_values" ;
VAL_ 1081 MRR_ObjRelVelYStd_19 0 "Valid_values" ;
VAL_ 1081 MRR_ObjRelVelXStd_19 0 "Valid_values" ;
VAL_ 1081 Checksum75 0 "Valid_value" ;
VAL_ 1081 RollingCounter74 0 "Valid_value" 15 "Invalid_value" ;
VAL_ 1081 MRR_ObjType_19 0 "Unknown" 1 "Truck" 2 "Car" 3 "Pedestrian" 4 "Cyclist" 5 "Reserved" ;
VAL_ 1081 MRR_ObjDistYStd_19 0 "Valid_values" ;
VAL_ 1081 MRR_ObjDistXStd_19 0 "Valid_values" ;
VAL_ 1081 MRR_ObjRelAccelY_19 0 "Valid_values" ;
VAL_ 1081 MRR_ObjRelVelY_19 0 "Valid_values" 8174 "Reserved" ;
VAL_ 1081 MRR_ObjRelVelX_19 0 "Valid_values" 8174 "Reserved" ;
VAL_ 1081 Checksum74 0 "Valid_value" ;
VAL_ 1081 RollingCounter73 0 "Valid_value" 15 "Invalid_value" ;
VAL_ 1081 MRR_ObjRelAccelX_19 0 "Valid_values" ;
VAL_ 1081 MRR_ObjDistY_19 0 "Valid_values" ;
VAL_ 1081 MRR_ObjDistX_19 0 "Valid_values" 4080 "Reserved" ;
VAL_ 1081 MRR_ObjObstacleProb_19 0 "Valid_values" ;
VAL_ 1081 MRR_ObjExistProb_19 0 "Valid_values" ;
VAL_ 1081 MRR_ObjID_19 0 "Valid_values" ;
VAL_ 1081 Checksum73 0 "Valid_value" ;
VAL_ 1082 RollingCounter88 0 "Valid_value" 15 "Invalid_value" ;
VAL_ 1082 MRR_ObjMeasured_21 0 "Init" 1 "Measured" 2 "Predicted" 3 "Reserved" ;
VAL_ 1082 MRR_ObjMeasured_22 0 "Init" 1 "Measured" 2 "Predicted" 3 "Reserved" ;
VAL_ 1082 MRR_ObjHeading_22 0 "Valid_values" 4446 "Reserved" ;
VAL_ 1082 MRR_ObjAge_22 0 "Valid_value" ;
VAL_ 1082 MRR_ObjRCS_22 0 "Valid_values" 961 "Reserved" ;
VAL_ 1082 BlockCounter11 0 "Valid_value" ;
VAL_ 1082 VFC_ObjHeight_22 0 "Valid_values" 601 "Reserved" ;
VAL_ 1082 Checksum88 0 "Valid_value" ;
VAL_ 1082 RollingCounter87 0 "Valid_value" 15 "Invalid_value" ;
VAL_ 1082 VFC_ObjMotionDirection_22 0 "Init" 1 "Inverse_direction" 2 "Same_direction" 3 "cross" 4 "reserved" 5 "reserved" 6 "reserved" 7 "reserved" ;
VAL_ 1082 VFC_ObjLength_22 0 "Valid_values" 401 "Reserved" ;
VAL_ 1082 VFC_ObjWidth_22 0 "Valid_values" 501 "Reserved" ;
VAL_ 1082 MRR_ObjMotionType_22 0 "int" 1 "unknown" 2 "Drive" 3 "Stopped" 4 "Stand" 5 "reserved" 6 "reserved" 7 "reserved" ;
VAL_ 1082 MRR_ObjRAccelYStd_22 0 "Valid_values" ;
VAL_ 1082 MRR_ObjRAccelXStd_22 0 "Valid_values" ;
VAL_ 1082 MRR_ObjRelVelYStd_22 0 "Valid_values" ;
VAL_ 1082 MRR_ObjRelVelXStd_22 0 "Valid_values" ;
VAL_ 1082 Checksum87 0 "Valid_value" ;
VAL_ 1082 RollingCounter86 0 "Valid_value" 15 "Invalid_value" ;
VAL_ 1082 MRR_ObjType_22 0 "Unknown" 1 "Truck" 2 "Car" 3 "Pedestrian" 4 "Cyclist" 5 "Reserved" ;
VAL_ 1082 MRR_ObjDistYStd_22 0 "Valid_values" ;
VAL_ 1082 MRR_ObjDistXStd_22 0 "Valid_values" ;
VAL_ 1082 MRR_ObjRelAccelY_22 0 "Valid_values" ;
VAL_ 1082 MRR_ObjRelVelY_22 0 "Valid_values" 8174 "Reserved" ;
VAL_ 1082 MRR_ObjRelVelX_22 0 "Valid_values" 8174 "Reserved" ;
VAL_ 1082 Checksum86 0 "Valid_value" ;
VAL_ 1082 RollingCounter85 0 "Valid_value" 15 "Invalid_value" ;
VAL_ 1082 MRR_ObjRelAccelX_22 0 "Valid_values" ;
VAL_ 1082 MRR_ObjDistY_22 0 "Valid_values" ;
VAL_ 1082 MRR_ObjDistX_22 0 "Valid_values" 4080 "Reserved" ;
VAL_ 1082 MRR_ObjObstacleProb_22 0 "Valid_values" ;
VAL_ 1082 MRR_ObjExistProb_22 0 "Valid_values" ;
VAL_ 1082 MRR_ObjID_22 0 "Valid_values" ;
VAL_ 1082 Checksum85 0 "Valid_value" ;
VAL_ 1082 RollingCounter84 0 "Valid_value" 15 "Invalid_value" ;
VAL_ 1082 MRR_ObjRefPoint_21 0 "Rear" 1 "Rear_left" 2 "Left" 3 "Front_left" 4 "Front" 5 "Front_Right" 6 "Right" 7 "Rear_right" ;
VAL_ 1082 MRR_ObjRefPoint_22 0 "Rear" 1 "Rear_left" 2 "Left" 3 "Front_left" 4 "Front" 5 "Front_Right" 6 "Right" 7 "Rear_right" ;
VAL_ 1082 MRR_ObjAge_21 0 "Valid_value" ;
VAL_ 1082 MRR_ObjRCS_21 0 "Valid_values" 961 "Reserved" ;
VAL_ 1082 MRR_ObjHeading_21 0 "Valid_values" 4446 "Reserved" ;
VAL_ 1082 VFC_ObjHeight_21 0 "Valid_values" 601 "Reserved" ;
VAL_ 1082 Checksum84 0 "Valid_value" ;
VAL_ 1082 RollingCounter83 0 "Valid_value" 15 "Invalid_value" ;
VAL_ 1082 VFC_ObjMotionDirection_21 0 "Init" 1 "Inverse_direction" 2 "Same_direction" 3 "cross" 4 "reserved" 5 "reserved" 6 "reserved" 7 "reserved" ;
VAL_ 1082 VFC_ObjLength_21 0 "Valid_values" 401 "Reserved" ;
VAL_ 1082 VFC_ObjWidth_21 0 "Valid_values" 501 "Reserved" ;
VAL_ 1082 MRR_ObjMotionType_21 0 "int" 1 "unknown" 2 "Drive" 3 "Stopped" 4 "Stand" 5 "reserved" 6 "reserved" 7 "reserved" ;
VAL_ 1082 MRR_ObjRAccelYStd_21 0 "Valid_values" ;
VAL_ 1082 MRR_ObjRAccelXStd_21 0 "Valid_values" ;
VAL_ 1082 MRR_ObjRelVelYStd_21 0 "Valid_values" ;
VAL_ 1082 MRR_ObjRelVelXStd_21 0 "Valid_values" ;
VAL_ 1082 Checksum83 0 "Valid_value" ;
VAL_ 1082 RollingCounter82 0 "Valid_value" 15 "Invalid_value" ;
VAL_ 1082 MRR_ObjType_21 0 "Unknown" 1 "Truck" 2 "Car" 3 "Pedestrian" 4 "Cyclist" 5 "Reserved" ;
VAL_ 1082 MRR_ObjDistYStd_21 0 "Valid_values" ;
VAL_ 1082 MRR_ObjDistXStd_21 0 "Valid_values" ;
VAL_ 1082 MRR_ObjRelAccelY_21 0 "Valid_values" ;
VAL_ 1082 MRR_ObjRelVelY_21 0 "Valid_values" 8174 "Reserved" ;
VAL_ 1082 MRR_ObjRelVelX_21 0 "Valid_values" 8174 "Reserved" ;
VAL_ 1082 Checksum82 0 "Valid_value" ;
VAL_ 1082 RollingCounter81 0 "Valid_value" 15 "Invalid_value" ;
VAL_ 1082 MRR_ObjRelAccelX_21 0 "Valid_values" ;
VAL_ 1082 MRR_ObjDistY_21 0 "Valid_values" ;
VAL_ 1082 MRR_ObjDistX_21 0 "Valid_values" 4080 "Reserved" ;
VAL_ 1082 MRR_ObjObstacleProb_21 0 "Valid_values" ;
VAL_ 1082 MRR_ObjExistProb_21 0 "Valid_values" ;
VAL_ 1082 MRR_ObjID_21 0 "Valid_values" ;
VAL_ 1082 Checksum81 0 "Valid_value" ;
VAL_ 1083 RollingCounter96 0 "Valid_value" 15 "Invalid_value" ;
VAL_ 1083 MRR_ObjMeasured_23 0 "Init" 1 "Measured" 2 "Predicted" 3 "Reserved" ;
VAL_ 1083 MRR_ObjMeasured_24 0 "Init" 1 "Measured" 2 "Predicted" 3 "Reserved" ;
VAL_ 1083 MRR_ObjHeading_24 0 "Valid_values" 4446 "Reserved" ;
VAL_ 1083 MRR_ObjAge_24 0 "Valid_value" ;
VAL_ 1083 MRR_ObjRCS_24 0 "Valid_values" 961 "Reserved" ;
VAL_ 1083 BlockCounter12 0 "Valid_value" ;
VAL_ 1083 VFC_ObjHeight_24 0 "Valid_values" 601 "Reserved" ;
VAL_ 1083 Checksum96 0 "Valid_value" ;
VAL_ 1083 RollingCounter95 0 "Valid_value" 15 "Invalid_value" ;
VAL_ 1083 VFC_ObjMotionDirection_24 0 "Init" 1 "Inverse_direction" 2 "Same_direction" 3 "cross" 4 "reserved" 5 "reserved" 6 "reserved" 7 "reserved" ;
VAL_ 1083 VFC_ObjLength_24 0 "Valid_values" 401 "Reserved" ;
VAL_ 1083 VFC_ObjWidth_24 0 "Valid_values" 501 "Reserved" ;
VAL_ 1083 MRR_ObjMotionType_24 0 "int" 1 "unknown" 2 "Drive" 3 "Stopped" 4 "Stand" 5 "reserved" 6 "reserved" 7 "reserved" ;
VAL_ 1083 MRR_ObjRAccelYStd_24 0 "Valid_values" ;
VAL_ 1083 MRR_ObjRAccelXStd_24 0 "Valid_values" ;
VAL_ 1083 MRR_ObjRelVelYStd_24 0 "Valid_values" ;
VAL_ 1083 MRR_ObjRelVelXStd_24 0 "Valid_values" ;
VAL_ 1083 Checksum95 0 "Valid_value" ;
VAL_ 1083 RollingCounter94 0 "Valid_value" 15 "Invalid_value" ;
VAL_ 1083 MRR_ObjType_24 0 "Unknown" 1 "Truck" 2 "Car" 3 "Pedestrian" 4 "Cyclist" 5 "Reserved" ;
VAL_ 1083 MRR_ObjDistYStd_24 0 "Valid_values" ;
VAL_ 1083 MRR_ObjDistXStd_24 0 "Valid_values" ;
VAL_ 1083 MRR_ObjRelAccelY_24 0 "Valid_values" ;
VAL_ 1083 MRR_ObjRelVelY_24 0 "Valid_values" 8174 "Reserved" ;
VAL_ 1083 MRR_ObjRelVelX_24 0 "Valid_values" 8174 "Reserved" ;
VAL_ 1083 Checksum94 0 "Valid_value" ;
VAL_ 1083 RollingCounter93 0 "Valid_value" 15 "Invalid_value" ;
VAL_ 1083 MRR_ObjRelAccelX_24 0 "Valid_values" ;
VAL_ 1083 MRR_ObjDistY_24 0 "Valid_values" ;
VAL_ 1083 MRR_ObjDistX_24 0 "Valid_values" 4080 "Reserved" ;
VAL_ 1083 MRR_ObjObstacleProb_24 0 "Valid_values" ;
VAL_ 1083 MRR_ObjExistProb_24 0 "Valid_values" ;
VAL_ 1083 MRR_ObjID_24 0 "Valid_values" ;
VAL_ 1083 Checksum93 0 "Valid_value" ;
VAL_ 1083 RollingCounter92 0 "Valid_value" 15 "Invalid_value" ;
VAL_ 1083 MRR_ObjRefPoint_23 0 "Rear" 1 "Rear_left" 2 "Left" 3 "Front_left" 4 "Front" 5 "Front_Right" 6 "Right" 7 "Rear_right" ;
VAL_ 1083 MRR_ObjRefPoint_24 0 "Rear" 1 "Rear_left" 2 "Left" 3 "Front_left" 4 "Front" 5 "Front_Right" 6 "Right" 7 "Rear_right" ;
VAL_ 1083 MRR_ObjAge_23 0 "Valid_value" ;
VAL_ 1083 MRR_ObjRCS_23 0 "Valid_values" 961 "Reserved" ;
VAL_ 1083 MRR_ObjHeading_23 0 "Valid_values" 4446 "Reserved" ;
VAL_ 1083 VFC_ObjHeight_23 0 "Valid_values" 601 "Reserved" ;
VAL_ 1083 Checksum92 0 "Valid_value" ;
VAL_ 1083 RollingCounter91 0 "Valid_value" 15 "Invalid_value" ;
VAL_ 1083 VFC_ObjMotionDirection_23 0 "Init" 1 "Inverse_direction" 2 "Same_direction" 3 "cross" 4 "reserved" 5 "reserved" 6 "reserved" 7 "reserved" ;
VAL_ 1083 VFC_ObjLength_23 0 "Valid_values" 401 "Reserved" ;
VAL_ 1083 VFC_ObjWidth_23 0 "Valid_values" 501 "Reserved" ;
VAL_ 1083 MRR_ObjMotionType_23 0 "int" 1 "unknown" 2 "Drive" 3 "Stopped" 4 "Stand" 5 "reserved" 6 "reserved" 7 "reserved" ;
VAL_ 1083 MRR_ObjRAccelYStd_23 0 "Valid_values" ;
VAL_ 1083 MRR_ObjRAccelXStd_23 0 "Valid_values" ;
VAL_ 1083 MRR_ObjRelVelYStd_23 0 "Valid_values" ;
VAL_ 1083 MRR_ObjRelVelXStd_23 0 "Valid_values" ;
VAL_ 1083 Checksum91 0 "Valid_value" ;
VAL_ 1083 RollingCounter90 0 "Valid_value" 15 "Invalid_value" ;
VAL_ 1083 MRR_ObjType_23 0 "Unknown" 1 "Truck" 2 "Car" 3 "Pedestrian" 4 "Cyclist" 5 "Reserved" ;
VAL_ 1083 MRR_ObjDistYStd_23 0 "Valid_values" ;
VAL_ 1083 MRR_ObjDistXStd_23 0 "Valid_values" ;
VAL_ 1083 MRR_ObjRelAccelY_23 0 "Valid_values" ;
VAL_ 1083 MRR_ObjRelVelY_23 0 "Valid_values" 8174 "Reserved" ;
VAL_ 1083 MRR_ObjRelVelX_23 0 "Valid_values" 8174 "Reserved" ;
VAL_ 1083 Checksum90 0 "Valid_value" ;
VAL_ 1083 RollingCounter89 0 "Valid_value" 15 "Invalid_value" ;
VAL_ 1083 MRR_ObjRelAccelX_23 0 "Valid_values" ;
VAL_ 1083 MRR_ObjDistY_23 0 "Valid_values" ;
VAL_ 1083 MRR_ObjDistX_23 0 "Valid_values" 4080 "Reserved" ;
VAL_ 1083 MRR_ObjObstacleProb_23 0 "Valid_values" ;
VAL_ 1083 MRR_ObjExistProb_23 0 "Valid_values" ;
VAL_ 1083 MRR_ObjID_23 0 "Valid_values" ;
VAL_ 1083 Checksum89 0 "Valid_value" ;
